VERSION ""

NS_ :

BS_:

BU_: VirtualNode_TEST LCDAM AVM ADV Gateway APA
VAL_TABLE_ HU_PDCAutoOnFunctionReq 3 "Reserved" 2 "OFF" 1 "ON" 0 "Inactive" ;
VAL_TABLE_ HU_BlindSpotFilledFunctionReq 3 "Reserved" 2 "On" 1 "Off" 0 "Inactive" ;
VAL_TABLE_ DisplayTheme 7 "Reserved" 6 "Reserved" 5 "Reserved" 4 "Reserved" 3 "Theme 3" 2 "Theme 2" 1 "Theme 1" 0 "Not define" ;
VAL_TABLE_ HU_PDCBuzzerReq 3 "Reserved" 2 "On" 1 "Off" 0 "Inactive" ;
VAL_TABLE_ PDCFunctionReq 3 "Reserved" 2 "On" 1 "Off" 0 "Inactive" ;
VAL_TABLE_ GW_OTAMode 7 "Reserved" 6 "Reserved" 5 "Reserved" 4 "Reserved" 3 "Reserved" 2 "Reserved" 1 "OTA Mode" 0 "Normal Mode" ;
VAL_TABLE_ GW_RemoteVehicleMode 1 "Remote Mode" 0 "Normal Mode" ;
VAL_TABLE_ WarningCmd_RCTA_Right 3 "Reserved" 2 "Warning level 2" 1 "Warning level 1" 0 "Inactive" ;
VAL_TABLE_ WarningCmd_RCTA_left 3 "Reserved" 2 "Warning level 2" 1 "Warning level 1" 0 "Inactive" ;
VAL_TABLE_ ADV_TargetTracingAvaialble 1 "Available" 0 "Not Available" ;
VAL_TABLE_ ADV_DebugEnabled 1 "Enabled" 0 "Not Enabled" ;
VAL_TABLE_ ADV_CurrentDirection 1 "Backward" 0 "Forward" ;
VAL_TABLE_ ADV_PathTracingAvaialble 1 "Available" 0 "Not Available" ;
VAL_TABLE_ ADV_Alarm_Position_Rear_Right 3 "Invalid" 2 "Range 2" 1 "Range 1" 0 "No Object" ;
VAL_TABLE_ ADV_Alarm_Position_Rear_Left 3 "Invalid" 2 "Range 2" 1 "Range 1" 0 "No Object" ;
VAL_TABLE_ ADV_Alarm_Position_Front_Right 3 "Invalid" 2 "Range 2" 1 "Range 1" 0 "No Object" ;
VAL_TABLE_ ADV_Alarm_Position_Front_Left 3 "Invalid" 2 "Range 2" 1 "Range 1" 0 "No Object" ;
VAL_TABLE_ ADV_PDCSchedule 3 "Reserved" 2 "Reserved" 1 "Sensor one time" 0 "No Request" ;
VAL_TABLE_ ADV_RightSlotSearchType 3 "All" 2 "Parallel" 1 "Perpedicular" 0 "Inactive" ;
VAL_TABLE_ ADV_LeftSlotSearchType 3 "All" 2 "Parallel" 1 "Perpedicular" 0 "Inactive" ;
VAL_TABLE_ ADV_FunctionAbnormalTip 63 "Reserved" 62 "Reserved" 61 "Reserved" 60 "Reserved" 59 "Reserved" 58 "Reserved" 57 "Reserved" 56 "Reserved" 55 "Wireless charging,ifstopcharging" 54 "Wireless charge station founded" 53 "Wireless charge enquiry charging" 52 "Air suspension is adjusting" 51 "Vehicle is in remote mode" 50 "Start park out tip" 49 "Start park in tip" 48 "Disclaimer tip" 47 "Wifi signal loss" 46 "Abnormal tire pressure" 45 "Space Unknown" 44 "Space Insufficient" 43 "Parking has been completed" 42 "Press DMH to start or exit" 41 "vehicle height not fulfilled" 40 "Vehicle direction incorrect" 39 "EPS Sys Can't Respons Correctly" 38 "Driving brake SysCan'tRespoCorre" 37 "AVS SysCan'tRespCorrectly" 36 "StartSysCan'tResp Correctly" 35 "Door SysCan'tResponCorrectly" 34 "Remote contro Sys Can't RespCorr" 33 "Gear shift SysCan'tResCorrectly" 32 "ParkinBrakeSysCan'tRespCorrectly" 31 "Forward-look signa is unavailab" 30 "PDC Signal Interf Not Available" 29 "AVS Signal Interf Not Available" 28 "YAW Signal Interf Not Available" 27 "SAS Signal Interf Not Available" 26 "Onekey startup interf is unavail" 25 "IVI Interface Not Available" 24 "VehicleDriveInterf Not Available" 23 "Comfort Sys Interfac unavailable" 22 "Steering interface unavailable" 21 "Parking Brake Interf unavailable" 20 "Shift gears interfac unavailable" 19 "DrivingBrake Interfa unavailable" 18 "SACC or LKA activated" 17 "Tracking error" 16 "Unable to switch vehicle mode" 15 "Space Insufficient" 14 "Obstacle is too close" 13 "Door open" 12 "Cannot enter parking status" 11 "Speed too fast,system exit" 10 "Speed too fast,Please slow down" 9 "Parki can'tcomple pleasetakeover" 8 "Road surface complexity" 7 "Gradient too high" 6 "Driver intervention EPB" 5 "Driver intervention steeringwhee" 4 "Driver intervention brake pedal" 3 "Vehicle not started" 2 "Parking syst exit by hard butt" 1 "Parking sys exit by soft butt" 0 "No Tip" ;
VAL_TABLE_ ADV_ParkOutDirection 7 "Reserved" 6 "Reserved" 5 "Left Parallel" 4 "Right Parallel" 3 "Left perpendicular" 2 "Rear perpendicular" 1 "Front perpendicular" 0 "Right perpendicular" ;
VAL_TABLE_ ADV_ParkInSlotSearchMode 1 "Manual" 0 "Auto" ;
VAL_TABLE_ ADV_ParkType 7 "Reserved" 6 "Reserved" 5 "Reserved" 4 "Reserved" 3 "Auto" 2 "Backward Oblique" 1 "Backward Perpendicular" 0 "Parallel" ;
VAL_TABLE_ RemoteAVSViewModeReq 15 "Reserved" 14 "Reserved" 13 "Reserved" 12 "Reserved" 11 "Screen Dragged 3D View" 10 "Rear Rim view" 9 "Front Rim view" 8 "Reserved" 7 "Rear Wide View" 6 "Front Wide View" 5 "Top View and Right View" 4 "Top View and Left View" 3 "Top View and Rear View" 2 "Top View and Front View" 1 "All Top View" 0 "Inactive" ;
VAL_TABLE_ RemoteAVSSharpnessReq 3 "Reserved" 2 "HD" 1 "SD" 0 "No Request" ;
VAL_TABLE_ RemoteMonitoringReq 3 "Reserved" 2 "On" 1 "Off" 0 "Inactive" ;
VAL_TABLE_ DoorSt_RR 1 "Open" 0 "Close" ;
VAL_TABLE_ DoorSt_RL 1 "Open" 0 "Close" ;
VAL_TABLE_ MCP_AVSandFRadarSwitch 1 "Pressed" 0 "Not pressed" ;
VAL_TABLE_ ParkOutDirection 15 "Reserved" 14 "Reserved" 13 "Reserved" 12 "Reserved" 11 "Reserved" 10 "Reserved" 9 "Reserved" 8 "Reserved" 7 "Remote control" 6 "Left Parallel" 5 "Right Parallel" 4 "Left perpendicular" 3 "Rear perpendicular" 2 "Front perpendicular" 1 "Right perpendicular" 0 "No request" ;
VAL_TABLE_ TargetSelection_Area 1 "Green Area" 0 "Red Area" ;
VAL_TABLE_ DMS_VehicleModeInfo 15 "Invalid value" 14 "Reserved" 13 "Reserved" 12 "Reserved" 11 "Reserved" 10 "Reserved" 9 "Reserved" 8 "Reserved" 7 "EV" 6 "Individual" 5 "Off road" 4 "Snow" 3 "Sport" 2 "Comfort" 1 "Eco" 0 "Auto" ;
VAL_TABLE_ EngineHoodSt 1 "Open" 0 "Close" ;
VAL_TABLE_ AutoLightMode 1 "Active" 0 "Inactive" ;
VAL_TABLE_ WheelSpeedDirection_RR 3 "Invalid Value" 2 "Backward" 1 "Forward" 0 "Stop" ;
VAL_TABLE_ WheelSpeedDirection_RL 3 "Invalid Value" 2 "Backward" 1 "Forward" 0 "Stop" ;
VAL_TABLE_ WheelSpeedDirection_FR 3 "Invalid Value" 2 "Backward" 1 "Forward" 0 "Stop" ;
VAL_TABLE_ WheelSpeedDirection_FL 3 "Invalid Value" 2 "Backward" 1 "Forward" 0 "Stop" ;
VAL_TABLE_ SensorErrorSt_RLS 1 "Error" 0 "No error" ;
VAL_TABLE_ ObjectRange_RLS 7 "Invalid Value" 6 "Range 6" 5 "Range 5" 4 "Range 4" 3 "Range 3" 2 "Range 2" 1 "Range 1" 0 "No Object" ;
VAL_TABLE_ SensorErrorSt_FRS 1 "Error" 0 "No error" ;
VAL_TABLE_ ObjectRange_FRS 7 "Invalid Value" 6 "Range 6" 5 "Range 5" 4 "Range 4" 3 "Range 3" 2 "Range 2" 1 "Range 1" 0 "No Object" ;
VAL_TABLE_ SensorErrorSt_FLS 1 "Error" 0 "No error" ;
VAL_TABLE_ ObjectRange_FLS 7 "Invalid Value" 6 "Range 6" 5 "Range 5" 4 "Range 4" 3 "Range 3" 2 "Range 2" 1 "Range 1" 0 "No Object" ;
VAL_TABLE_ SensorBlockageSt_RLS 1 "Blockage" 0 "No blockage" ;
VAL_TABLE_ SensorBlockageSt_FRS 1 "Blockage" 0 "No blockage" ;
VAL_TABLE_ SensorBlockageSt_FLS 1 "Blockage" 0 "No blockage" ;
VAL_TABLE_ PDC_FunctionTip 7 "Reserved" 6 "Searching both slot failure" 5 "Searching both slot success" 4 "Searching left slot success" 3 "Searching left slot failure" 2 "Searching right slot success" 1 "Searching right slot failure" 0 "Inactive" ;
VAL_TABLE_ SwitchScreenRequest_PDC 3 "Reserved" 2 "PDC Display Enter Request" 1 "PDC Display Exit Request" 0 "Inactive" ;
VAL_TABLE_ PDCAutoOnFunctionInd 1 "On" 0 "Off" ;
VAL_TABLE_ BuzzerSwitchSt 1 "On" 0 "Off" ;
VAL_TABLE_ RadarSysSt_RearSide 1 "On" 0 "Off" ;
VAL_TABLE_ RadarSysSt_FrontSide 1 "On" 0 "Off" ;
VAL_TABLE_ BuzzerAlarmPosition 7 "Reserved" 6 "Reserved" 5 "Reserved" 4 "Front + Rear" 3 "SelfCheck" 2 "Rear" 1 "Front" 0 "Off" ;
VAL_TABLE_ AVS_RemoteViewModeFeedback 31 "Reserved" 30 "Reserved" 29 "Reserved" 28 "Reserved" 27 "Reserved" 26 "Reserved" 25 "Reserved" 24 "Rear Rim view Failure" 23 "Rear Rim view Success" 22 "Front Rim view Failure" 21 "Front Rim view Success" 20 "Reserved" 19 "Reserved" 18 "Rear Wide View Failure" 17 "Rear Wide View Success" 16 "Front Wide View Failure" 15 "Front Wide View Success" 14 "Top View and Right View Failure" 13 "Top View and Right View Success" 12 "Top View and Left View Failure" 11 "Top View and Left View Success" 10 "Top View and Rear View Failure" 9 "Top View and Rear View Success" 8 "Top View and Front View Failure" 7 "Top View and Front View Success" 6 "All Top View Failure" 5 "All Top View Success" 4 "On Failure" 3 "On Success" 2 "Off Failure" 1 "Off Success" 0 "Inactive" ;
VAL_TABLE_ TurnFollowUpFunctionInd 1 "On" 0 "Off" ;
VAL_TABLE_ RemoteMonitoringModeSt_AVS 1 "Video Mode" 0 "Picture Mode" ;
VAL_TABLE_ RemoteMonitoringSt_AVS 1 "On" 0 "Off" ;
VAL_TABLE_ RemoteMonitoringSharpnessSt_AVS 1 "HD" 0 "SD" ;
VAL_TABLE_ AVS_RemoteSharpnessFeedback 7 "Reserved" 6 "Reserved" 5 "Reserved" 4 "HD Failure" 3 "HD Success" 2 "SD Failure" 1 "SD Success" 0 "Inactive" ;
VAL_TABLE_ AVS_RemoteMonitorigFeedback 7 "Reserved" 6 "Reserved" 5 "Reserved" 4 "On Failure" 3 "On Success" 2 "Off Failure" 1 "Off Success" 0 "Inactive" ;
VAL_TABLE_ AVS_PDWarning_Rear 1 "Warning" 0 "No warning" ;
VAL_TABLE_ AVS_PDWarning_Front 1 "Warning" 0 "No warning" ;
VAL_TABLE_ AVS_CalibrationSt 3 "Reserved" 2 "Calibrated" 1 "Calibrating" 0 "Not calibrated" ;
VAL_TABLE_ AVS_AbnormalTip 7 "Reserved" 6 "Reserved" 5 "Reserved" 4 "Reserved" 3 "Reserved" 2 "Reserved" 1 "Speed too high" 0 "Inactive" ;
VAL_TABLE_ AVSCameraBlockageSt_Right 1 "Blockage" 0 "No Blockage" ;
VAL_TABLE_ AVSCameraBlockageSt_Left 1 "Blockage" 0 "No Blockage" ;
VAL_TABLE_ AVSCameraBlockageSt_Rear 1 "Blockage" 0 "No Blockage" ;
VAL_TABLE_ AVSCameraBlockageSt_Front 1 "Blockage" 0 "No Blockage" ;
VAL_TABLE_ FoundSlotBuzzerTip 1 "Active" 0 "Inactive" ;
VAL_TABLE_ BlindSpotFilledFunctionInd 1 "On" 0 "Off" ;
VAL_TABLE_ AVSViewtype 3 "Reserved" 2 "Other" 1 "3D" 0 "2D" ;
VAL_TABLE_ SensorBlockageSt 1 "blockage" 0 "No blockage" ;
VAL_TABLE_ SensorErrorSt 1 "error" 0 "No error" ;
VAL_TABLE_ ObjectRange 7 "Invalid Value" 6 "Range 6" 5 "Range 5" 4 "Range 4" 3 "Range 3" 2 "Range 2" 1 "Range 1" 0 "No Object" ;
VAL_TABLE_ TxRxSt_ 3 "Reserved" 2 "Rx" 1 "Tx" 0 "Reserved" ;
VAL_TABLE_ VtSif_HU_SpeechReq_AVS 3 "Reserved" 2 "On" 1 "Off" 0 "Inactive" ;
VAL_TABLE_ ViSig_APS_Slot1_Info 3 "Reserved" 2 "Obstacle" 1 "No obstacle" 0 "Initial" ;
VAL_TABLE_ VtSigHU_AVMSwitchScreenResp 3 "Reserved" 2 "AVM Exit Response" 1 "AVM Enter Response" 0 "Inactive" ;

BO_ 3221225472 VECTOR__INDEPENDENT_SIG_MSG: 0 Vector__XXX
 SG_ USS_DIAG_MRL : 0|10@1+ (1,0) [0|1023] "" Vector__XXX
 SG_ Distance_PDC_6 : 0|10@1+ (1,0) [0|0] "cm" Vector__XXX
 SG_ SafetySW_PDCAVM_Switch : 0|1@1+ (1,0) [0|0] "" Vector__XXX
 SG_ YRS_2_Reserve : 0|16@1- (1,0) [0|0] "" Vector__XXX
 SG_ YRS_1_Reserve : 0|8@1+ (1,0) [0|0] "" Vector__XXX
 SG_ PDC_SwitchScreenRequest : 0|2@1+ (1,0) [0|0] "" Vector__XXX
 SG_ PDC_BuzzerSwitchSt : 0|1@1+ (1,0) [0|0] "" Vector__XXX
 SG_ PDC_AutoOnFunctionInd : 0|1@1+ (1,0) [0|0] "" Vector__XXX
 SG_ PDC_SideRadarSystemStatus : 0|1@1+ (1,0) [0|0] "" Vector__XXX
 SG_ PDC_RRLevel : 0|3@1+ (1,0) [0|0] "" Vector__XXX
 SG_ PDC_RLLevel : 0|3@1+ (1,0) [0|0] "" Vector__XXX
 SG_ PDC_RearRadarSystemStatus : 0|1@1+ (1,0) [0|0] "" Vector__XXX
 SG_ PDC_FrontRadarSystemStatus : 0|1@1+ (1,0) [0|0] "" Vector__XXX
 SG_ PDC_FRLevel : 0|3@1- (1,0) [0|0] "" Vector__XXX
 SG_ PDC_FLLevel : 0|3@1+ (1,0) [0|0] "" Vector__XXX
 SG_ PDC_CenterRRLevel : 0|3@1+ (1,0) [0|0] "" Vector__XXX
 SG_ PDC_CenterRLLevel : 0|3@1+ (1,0) [0|0] "" Vector__XXX
 SG_ PDC_CenterFRLevel : 0|3@1+ (1,0) [0|7] "" Vector__XXX
 SG_ PDC_CenterFLLevel : 0|3@1+ (1,0) [0|0] "" Vector__XXX
 SG_ PDC_BuzzerControl : 0|3@1+ (1,0) [0|0] "" Vector__XXX
 SG_ PDC_RightLongDistSensorErrSta : 0|2@1- (1,0) [0|0] "" Vector__XXX
 SG_ PDC_LeftLongDistSensorErrSta : 0|2@1- (1,0) [0|0] "" Vector__XXX
 SG_ PDC_RRSensorErrorStatus : 0|2@1- (1,0) [0|0] "" Vector__XXX
 SG_ PDC_CenterRRSensorErrorStatus : 0|2@1- (1,0) [0|0] "" Vector__XXX
 SG_ PDC_CenterRLSensorErrorStatus : 0|2@1- (1,0) [0|0] "" Vector__XXX
 SG_ PDC_RLSensorErrorStatus : 0|2@1- (1,0) [0|0] "" Vector__XXX
 SG_ PDC_FRSensorErrorStatus : 0|2@1- (1,0) [0|0] "" Vector__XXX
 SG_ PDC_CenterFRSensorErrorStatus : 0|2@1+ (1,0) [0|0] "" Vector__XXX
 SG_ PDC_CenterFLSensorErrorStatus : 0|2@1- (1,0) [0|0] "" Vector__XXX
 SG_ PDC_FLSensorErrorStatus : 0|2@1+ (1,0) [0|0] "" Vector__XXX
 SG_ AY1Offset : 0|12@1- (0.01,0) [-20.48|20.47] "m/s2" Vector__XXX
 SG_ AX1Offset : 0|12@1- (0.01,0) [-20.48|20.47] "m/s2" Vector__XXX
 SG_ YawRateOffset : 0|12@1- (0.05,0) [-102.4|102.35] "" Vector__XXX
 SG_ LiveCounter_YRS2 : 0|4@1+ (1,0) [0|0] "Pulse" Vector__XXX
 SG_ Checksum_YRS2 : 0|8@1+ (1,0) [0|0] "" Vector__XXX
 SG_ BCM_RightTurnLightCmd : 0|1@1+ (1,0) [0|0] "" Vector__XXX
 SG_ BCM_LeftTurnLightCmd : 0|1@1+ (1,0) [0|0] "" Vector__XXX
 SG_ HU_SpeechRequest_AVMView : 0|4@1+ (1,0) [0|0] "" Vector__XXX
 SG_ HU_SpeechRequest_AVMandPDC : 0|2@1+ (1,0) [0|0] "" Vector__XXX
 SG_ HU_PDCFunctionReq : 0|1@1+ (1,0) [0|0] "" Vector__XXX
 SG_ HU_PDCBuzzerReq : 0|1@1+ (1,0) [0|0] "" Vector__XXX
 SG_ HU_PDCAutoOnFunctionReq : 0|1@1+ (1,0) [0|0] "" Vector__XXX
 SG_ HU_PDCAVMFunctionCmd : 0|1@1+ (1,0) [0|0] "" Vector__XXX
 SG_ reserve_1 : 0|32@1+ (1,0) [0|0] "" Vector__XXX
 SG_ ScreenPressPosition_X : 0|11@1+ (1,0) [0|0] "pixel" Vector__XXX
 SG_ AVS_SpeechControlFeedback : 0|5@1+ (1,0) [0|0] "" Vector__XXX
 SG_ MODWarning_Right : 0|1@1+ (1,0) [0|0] "" Vector__XXX
 SG_ MODWarning_Left : 0|1@1+ (1,0) [0|0] "" Vector__XXX
 SG_ CTAWarning_Rear : 0|1@1+ (1,0) [0|0] "" Vector__XXX
 SG_ CTAWarning_Front : 0|1@1+ (1,0) [0|0] "" Vector__XXX
 SG_ SensorBlockageSt_RLong : 0|1@1+ (1,0) [0|0] "" Vector__XXX
 SG_ SensorBlockageSt_Llong : 0|1@1+ (1,0) [0|0] "" Vector__XXX
 SG_ PDC_SearchingSlotPosition : 0|2@1+ (1,0) [0|0] "" Vector__XXX
 SG_ PDC_SpeechControlFeedback : 0|3@1+ (1,0) [0|0] "" Vector__XXX
 SG_ SensorErrorSt_RLong : 0|1@1+ (1,0) [0|0] "" Vector__XXX
 SG_ SensorErrorSt_LLong : 0|1@1+ (1,0) [0|0] "" Vector__XXX
 SG_ RadarSysSt_Side : 0|1@1+ (1,0) [0|1] "" Vector__XXX
 SG_ HandParkingBrakeSt : 0|2@1+ (1,0) [0|0] "" Vector__XXX
 SG_ FogLightSt_FR : 0|1@1+ (1,0) [0|0] "" Vector__XXX
 SG_ FogLightSt_FL : 0|1@1+ (1,0) [0|0] "" Vector__XXX
 SG_ ParkInSlotSearchModeSet : 0|2@1+ (1,0) [0|0] "" Vector__XXX
 SG_ AVSViewModeReponse : 0|4@1+ (1,0) [0|0] "" Vector__XXX
 SG_ ScreenPressPosition_Y : 0|11@1+ (1,0) [0|0] "pixel" Vector__XXX
 SG_ ABS_2_Reserve : 0|8@1+ (1,0) [0|0] "" Vector__XXX
 SG_ PDC_DIS_RRS : 0|10@1- (1,0) [0|1023] "" Vector__XXX
 SG_ PDC_DIS_RLS : 0|10@1+ (1,0) [0|1023] "" Vector__XXX

BO_ 746 USS_SLOT_R_CD: 8 APA
 SG_ USS_SLOT_R_Dy : 48|16@1- (1,0) [-32768|32767] ""  APA
 SG_ USS_SLOT_R_Dx : 32|16@1- (1,0) [-32768|32767] ""  APA
 SG_ USS_SLOT_R_Cy : 16|16@1- (1,0) [-32768|32767] ""  APA
 SG_ USS_SLOT_R_Cx : 0|16@1- (1,0) [-32768|32767] ""  APA

BO_ 745 USS_SLOT_R_AB: 8 APA
 SG_ USS_SLOT_R_By : 48|16@1- (1,0) [-32768|32767] ""  APA
 SG_ USS_SLOT_R_Bx : 32|16@1- (1,0) [-32768|32767] ""  APA
 SG_ USS_SLOT_R_Ay : 16|16@1- (1,0) [-32768|32767] ""  APA
 SG_ USS_SLOT_R_Ax : 0|16@1- (1,0) [-32768|32767] ""  APA

BO_ 744 USS_SLOT_L_CD: 8 APA
 SG_ USS_SLOT_L_Dy : 48|16@1- (1,0) [-32768|32767] ""  APA
 SG_ USS_SLOT_L_Dx : 32|16@1- (1,0) [-32768|32767] ""  APA
 SG_ USS_SLOT_L_Cy : 16|16@1- (1,0) [-32768|32767] ""  APA
 SG_ USS_SLOT_L_Cx : 0|16@1- (1,0) [-32768|32767] ""  APA

BO_ 743 USS_SLOT_L_AB: 8 APA
 SG_ USS_SLOT_L_By : 48|16@1- (1,0) [-32768|32767] ""  APA
 SG_ USS_SLOT_L_Bx : 32|16@1- (1,0) [-32768|32767] ""  APA
 SG_ USS_SLOT_L_AY : 16|16@1- (1,0) [-32768|32767] ""  APA
 SG_ USS_SLOT_L_Ax : 0|16@1- (1,0) [-32768|32767] ""  APA

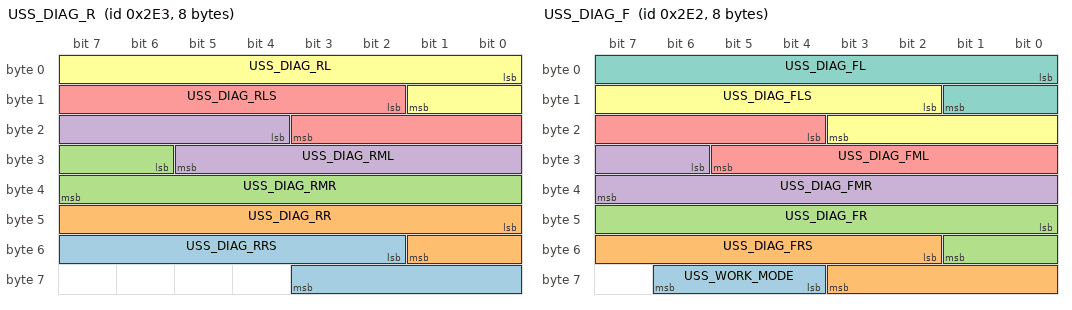
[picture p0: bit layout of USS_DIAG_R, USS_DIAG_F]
BO_ 739 USS_DIAG_R: 8 APA
 SG_ USS_DIAG_RRS : 50|10@1+ (1,0) [0|1023] ""  APA
 SG_ USS_DIAG_RR : 40|10@1+ (1,0) [0|1023] ""  APA
 SG_ USS_DIAG_RMR : 30|10@1+ (1,0) [0|1023] ""  APA
 SG_ USS_DIAG_RML : 20|10@1+ (1,0) [0|1023] ""  APA
 SG_ USS_DIAG_RLS : 10|10@1+ (1,0) [0|1023] ""  APA
 SG_ USS_DIAG_RL : 0|10@1+ (1,0) [0|1023] ""  APA

BO_ 738 USS_DIAG_F: 8 APA
 SG_ USS_WORK_MODE : 60|3@1+ (1,0) [0|7] ""  APA
 SG_ USS_DIAG_FRS : 50|10@1+ (1,0) [0|1023] ""  APA
 SG_ USS_DIAG_FR : 40|10@1+ (1,0) [0|1023] ""  APA
 SG_ USS_DIAG_FMR : 30|10@1+ (1,0) [0|1023] ""  APA
 SG_ USS_DIAG_FML : 20|10@1+ (1,0) [0|1023] ""  APA
 SG_ USS_DIAG_FLS : 10|10@1+ (1,0) [0|1023] ""  APA
 SG_ USS_DIAG_FL : 0|10@1+ (1,0) [0|1023] ""  APA

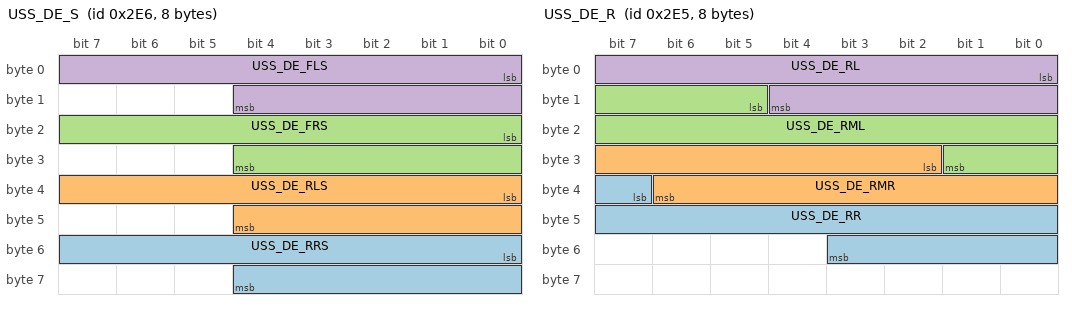
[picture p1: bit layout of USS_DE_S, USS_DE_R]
BO_ 742 USS_DE_S: 8 APA
 SG_ USS_DE_RRS : 48|13@1+ (1,0) [0|65535] ""  APA
 SG_ USS_DE_RLS : 32|13@1+ (1,0) [0|65535] ""  APA
 SG_ USS_DE_FRS : 16|13@1+ (1,0) [0|65535] ""  APA
 SG_ USS_DE_FLS : 0|13@1+ (1,0) [0|65535] ""  APA

BO_ 741 USS_DE_R: 8 APA
 SG_ USS_DE_RR : 39|13@1+ (1,0) [0|65535] ""  APA
 SG_ USS_DE_RMR : 26|13@1+ (1,0) [0|65535] ""  APA
 SG_ USS_DE_RML : 13|13@1+ (1,0) [0|65535] ""  APA
 SG_ USS_DE_RL : 0|13@1+ (1,0) [0|65535] ""  APA

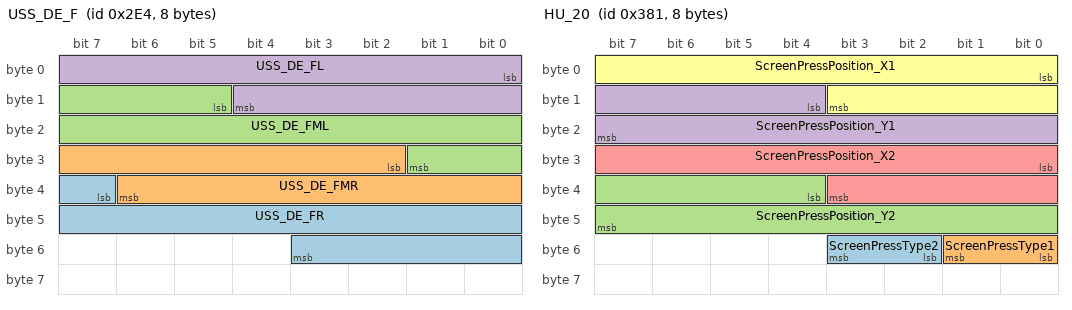
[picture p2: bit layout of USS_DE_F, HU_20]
BO_ 740 USS_DE_F: 8 APA
 SG_ USS_DE_FR : 39|13@1+ (1,0) [0|65535] "" Vector__XXX
 SG_ USS_DE_FMR : 26|13@1+ (1,0) [0|65535] "" Vector__XXX
 SG_ USS_DE_FML : 13|13@1+ (1,0) [0|65535] "" Vector__XXX
 SG_ USS_DE_FL : 0|13@1+ (1,0) [0|65535] "" Vector__XXX

BO_ 994 alpha_distance_R: 8 VirtualNode_TEST
 SG_ alpha_USS_RR : 48|16@1+ (1,0) [0|65535] ""  APA
 SG_ alpha_USS_RMR : 32|16@1+ (1,0) [0|65535] ""  APA
 SG_ alpha_USS_RML : 16|16@1+ (1,0) [0|65535] ""  APA
 SG_ alpha_USS_RL : 0|16@1+ (1,0) [0|65535] ""  APA

BO_ 995 alpha_distance_Long: 8 VirtualNode_TEST
 SG_ alpha_USS_RR_long : 48|16@1+ (1,0) [0|65535] ""  APA
 SG_ alpha_USS_RL_long : 32|16@1+ (1,0) [0|65535] ""  APA
 SG_ alpha_USS_FR_long : 16|16@1+ (1,0) [0|65535] ""  APA
 SG_ alpha_USS_FL_long : 0|16@1+ (1,0) [0|65535] ""  APA

BO_ 993 alpha_distance_F: 8 VirtualNode_TEST
 SG_ alpha_USS_FR : 48|16@1+ (1,0) [0|65535] ""  APA
 SG_ alpha_USS_FMR : 32|16@1+ (1,0) [0|65535] ""  APA
 SG_ alpha_USS_FML : 16|16@1+ (1,0) [0|65535] ""  APA
 SG_ alpha_USS_FL : 0|16@1+ (1,0) [0|65535] ""  APA

BO_ 897 HU_20: 8 Gateway
 SG_ ScreenPressType2 : 50|2@1+ (1,0) [0|0] ""  APA
 SG_ ScreenPressType1 : 48|2@1+ (1,0) [0|0] ""  APA
 SG_ ScreenPressPosition_Y2 : 36|12@1+ (1,0) [0|720] "pixel"  APA
 SG_ ScreenPressPosition_Y1 : 12|12@1+ (1,0) [0|720] "pixel"  APA
 SG_ ScreenPressPosition_X2 : 24|12@1+ (1,0) [0|2607] "pixel"  APA
 SG_ ScreenPressPosition_X1 : 0|12@1+ (1,0) [0|2607] "pixel"  APA

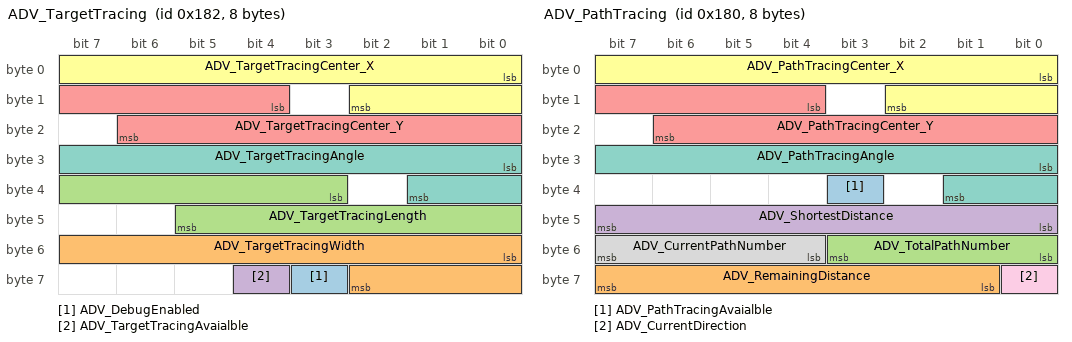
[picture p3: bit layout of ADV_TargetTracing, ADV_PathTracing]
BO_ 386 ADV_TargetTracing: 8 ADV
 SG_ ADV_DebugEnabled : 59|1@1+ (1,0) [0|0] ""  APA
 SG_ ADV_TargetTracingWidth : 48|11@1+ (1,0) [0|2000] "cm"  APA
 SG_ ADV_TargetTracingLength : 35|11@1- (1,0) [0|2000] "cm"  APA
 SG_ ADV_TargetTracingAvaialble : 60|1@1+ (1,0) [0|0] ""  APA
 SG_ ADV_TargetTracingCenter_Y : 12|11@1- (1,0) [-1000|1000] "cm"  APA
 SG_ ADV_TargetTracingCenter_X : 0|11@1- (1,0) [-1000|1000] "cm"  APA
 SG_ ADV_TargetTracingAngle : 24|10@1+ (1,0) [0|360] "degree"  APA

BO_ 384 ADV_PathTracing: 8 ADV
 SG_ ADV_PathTracingAvaialble : 35|1@1- (1,0) [0|0] ""  APA
 SG_ ADV_RemainingDistance : 57|7@1+ (1,0) [0|100] "%"  APA
 SG_ ADV_TotalPathNumber : 48|4@1+ (1,0) [0|10] ""  APA
 SG_ ADV_ShortestDistance : 40|8@1- (1,0) [-126|127] "cm"  APA
 SG_ ADV_PathTracingCenter_Y : 12|11@1- (1,0) [-1000|1000] "cm"  APA
 SG_ ADV_PathTracingCenter_X : 0|11@1- (1,0) [-1000|1000] "cm"  APA
 SG_ ADV_PathTracingAngle : 24|10@1+ (1,0) [0|360] "degree"  APA
 SG_ ADV_CurrentPathNumber : 52|4@1+ (1,0) [0|10] ""  APA
 SG_ ADV_CurrentDirection : 56|1@1+ (1,0) [0|0] ""  APA

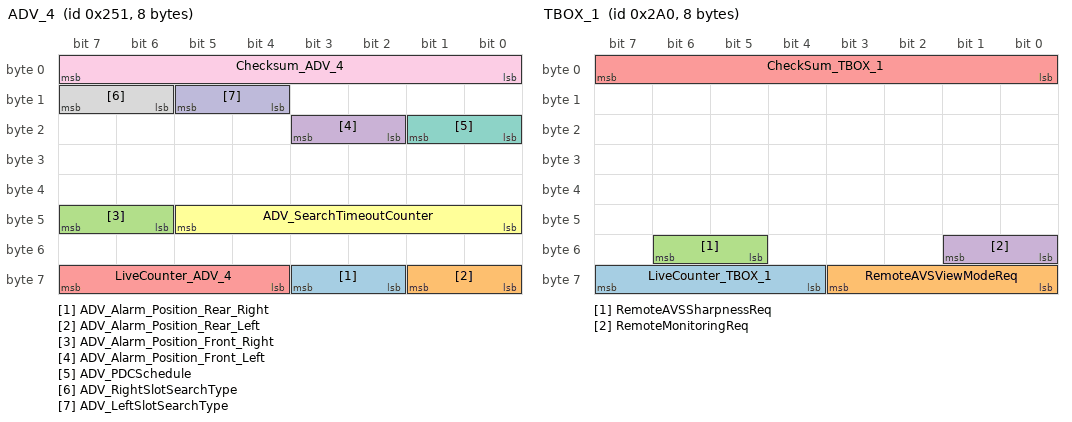
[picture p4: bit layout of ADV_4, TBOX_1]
BO_ 593 ADV_4: 8 ADV
 SG_ ADV_Alarm_Position_Rear_Right : 58|2@1+ (1,0) [0|0] ""  APA
 SG_ ADV_Alarm_Position_Rear_Left : 56|2@1+ (1,0) [0|0] ""  APA
 SG_ ADV_Alarm_Position_Front_Right : 46|2@1+ (1,0) [0|0] ""  APA
 SG_ ADV_Alarm_Position_Front_Left : 18|2@1+ (1,0) [0|0] ""  APA
 SG_ LiveCounter_ADV_4 : 60|4@1+ (1,0) [0|15] "Pulse"  APA
 SG_ ADV_SearchTimeoutCounter : 40|6@1+ (1,0) [0|63] "seconds"  APA
 SG_ ADV_PDCSchedule : 16|2@1+ (1,0) [0|0] ""  APA
 SG_ ADV_RightSlotSearchType : 14|2@1+ (1,0) [0|0] ""  APA
 SG_ Checksum_ADV_4 : 0|8@1+ (1,0) [0|255] ""  APA
 SG_ ADV_LeftSlotSearchType : 12|2@1+ (1,0) [0|0] ""  APA

BO_ 672 TBOX_1: 8 Gateway
 SG_ LiveCounter_TBOX_1 : 60|4@1+ (1,0) [0|15] "pulse"  APA
 SG_ RemoteAVSViewModeReq : 56|4@1+ (1,0) [0|0] ""  APA
 SG_ RemoteAVSSharpnessReq : 53|2@1+ (1,0) [0|0] ""  APA
 SG_ RemoteMonitoringReq : 48|2@1+ (1,0) [0|0] ""  APA
 SG_ CheckSum_TBOX_1 : 0|8@1+ (1,0) [0|255] ""  APA

BO_ 591 RRDCU_1: 8 Gateway
 SG_ DoorSt_RR : 2|1@1+ (1,0) [0|0] ""  APA

BO_ 590 RLDCU_1: 8 Gateway
 SG_ DoorSt_RL : 2|1@1+ (1,0) [0|0] ""  APA

BO_ 420 MCP_1: 8 Gateway
 SG_ MCP_AVSandFRadarSwitch : 25|1@1+ (1,0) [0|1] ""  APA

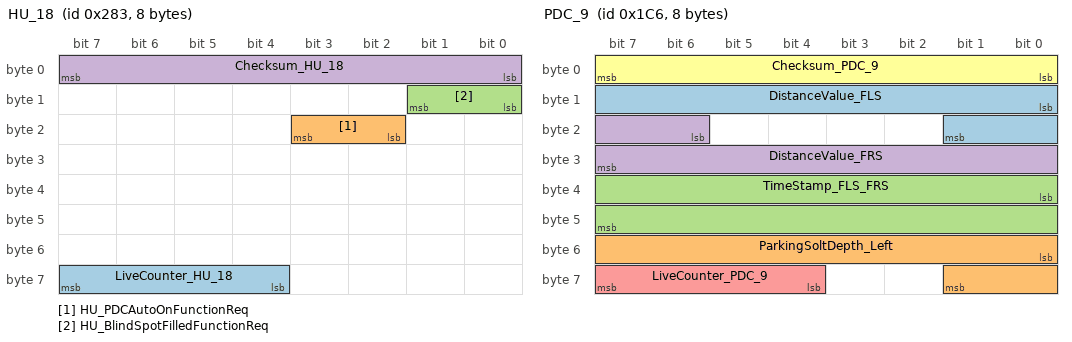
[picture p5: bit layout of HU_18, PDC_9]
BO_ 643 HU_18: 8 Gateway
 SG_ LiveCounter_HU_18 : 60|4@1+ (1,0) [0|15] "Pulse"  APA
 SG_ HU_PDCAutoOnFunctionReq : 18|2@1+ (1,0) [0|0] ""  APA
 SG_ HU_BlindSpotFilledFunctionReq : 8|2@1+ (1,0) [0|0] ""  APA
 SG_ Checksum_HU_18 : 0|8@1+ (1,0) [0|255] ""  APA

BO_ 657 HU_14: 8 Gateway
 SG_ DisplayTheme : 24|3@1+ (1,0) [0|0] ""  APA

BO_ 667 HU_10: 8 Gateway
 SG_ LiveCounter_HU_10 : 60|4@1+ (1,0) [0|15] "Pulse"  APA
 SG_ HU_PDCBuzzerReq : 22|2@1+ (1,0) [0|0] ""  APA
 SG_ Checksum_HU_10 : 0|8@1+ (1,0) [0|255] ""  APA

BO_ 688 GW_Config: 8 Gateway
 SG_ GW_RemoteVehicleMode : 12|1@1+ (1,0) [0|0] ""  APA
 SG_ GW_OTAMode : 16|3@1+ (1,0) [0|0] ""  APA

BO_ 534 DMS_2: 8 Gateway
 SG_ DMS_VehicleModeinfo : 8|4@1+ (1,0) [0|0] ""  APA

BO_ 571 BCM1_7: 8 Gateway
 SG_ Brightness_L : 8|8@1+ (400,0) [0|101200] "LUX"  APA
 SG_ Brightness_H : 16|10@1+ (6,0) [0|6126] "LUX"  APA
 SG_ Rainlntensity : 0|4@1+ (0.1,0) [0|1.5] ""  APA

BO_ 564 BCM1_3: 8 Gateway
 SG_ EngineHoodSt : 12|1@1+ (1,0) [0|0] ""  APA

BO_ 454 PDC_9: 8 APA
 SG_ DistanceValue_FLS : 8|10@1+ (1,0) [0|500] "cm"  AVM,ADV
 SG_ ParkingSoltDepth_Left : 48|10@1+ (1,0) [0|500] "cm"  AVM,ADV
 SG_ TimeStamp_FLS_FRS : 32|16@1+ (1,0) [0|65535] "ms"  AVM,ADV
 SG_ DistanceValue_FRS : 22|10@1+ (1,0) [0|500] "cm"  AVM,ADV
 SG_ LiveCounter_PDC_9 : 60|4@1+ (1,0) [0|15] "Pulse"  AVM,ADV
 SG_ Checksum_PDC_9 : 0|8@1+ (1,0) [0|255] ""  AVM,ADV

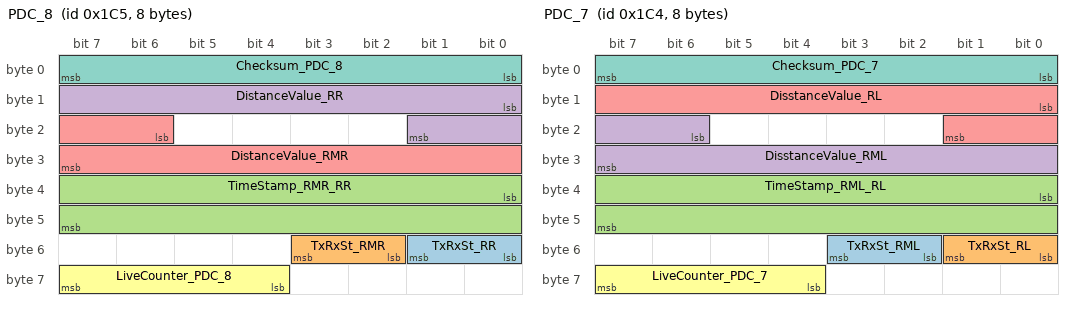
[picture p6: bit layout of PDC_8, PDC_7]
BO_ 453 PDC_8: 8 APA
 SG_ TxRxSt_RR : 48|2@1+ (1,0) [0|0] ""  AVM,ADV
 SG_ TxRxSt_RMR : 50|2@1+ (1,0) [0|0] ""  AVM,ADV
 SG_ TimeStamp_RMR_RR : 32|16@1+ (1,0) [0|65535] "ms"  AVM,ADV
 SG_ DistanceValue_RR : 8|10@1+ (1,0) [0|500] "cm"  AVM,ADV
 SG_ DistanceValue_RMR : 22|10@1+ (1,0) [0|500] "cm"  AVM,ADV
 SG_ LiveCounter_PDC_8 : 60|4@1+ (1,0) [0|15] "Pulse"  AVM,ADV
 SG_ Checksum_PDC_8 : 0|8@1+ (1,0) [0|255] ""  AVM,ADV

BO_ 452 PDC_7: 8 APA
 SG_ TxRxSt_RML : 50|2@1+ (1,0) [0|0] ""  AVM,ADV
 SG_ TxRxSt_RL : 48|2@1+ (1,0) [0|0] ""  AVM,ADV
 SG_ TimeStamp_RML_RL : 32|16@1+ (1,0) [0|65535] "ms"  AVM,ADV
 SG_ DisstanceValue_RML : 22|10@1+ (1,0) [0|500] "cm"  AVM,ADV
 SG_ DisstanceValue_RL : 8|10@1+ (1,0) [0|500] "cm"  AVM,ADV
 SG_ LiveCounter_PDC_7 : 60|4@1+ (1,0) [0|15] "Pulse"  AVM,ADV
 SG_ Checksum_PDC_7 : 0|8@1+ (1,0) [0|255] ""  AVM,ADV

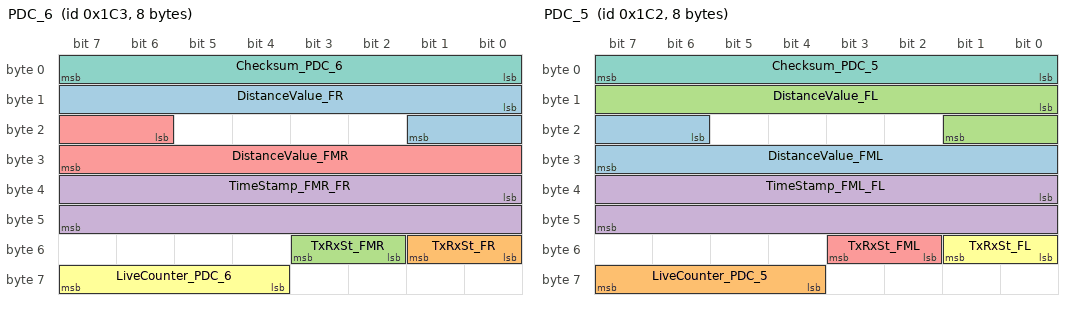
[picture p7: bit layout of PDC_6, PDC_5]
BO_ 451 PDC_6: 8 APA
 SG_ DistanceValue_FR : 8|10@1+ (1,0) [0|500] "cm"  AVM,ADV
 SG_ TxRxSt_FR : 48|2@1+ (1,0) [0|0] ""  AVM,ADV
 SG_ TxRxSt_FMR : 50|2@1+ (1,0) [0|0] ""  AVM,ADV
 SG_ TimeStamp_FMR_FR : 32|16@1+ (1,0) [0|65535] "ms"  AVM,ADV
 SG_ DistanceValue_FMR : 22|10@1+ (1,0) [0|500] "cm"  AVM,ADV
 SG_ LiveCounter_PDC_6 : 60|4@1+ (1,0) [0|15] "Pulse"  AVM,ADV
 SG_ Checksum_PDC_6 : 0|8@1+ (1,0) [0|255] ""  AVM,ADV

BO_ 450 PDC_5: 8 APA
 SG_ DistanceValue_FML : 22|10@1+ (1,0) [0|500] "cm" Vector__XXX
 SG_ LiveCounter_PDC_5 : 60|4@1+ (1,0) [0|15] "Pulse"  AVM,ADV
 SG_ DistanceValue_FL : 8|10@1+ (1,0) [0|500] "cm"  AVM,ADV
 SG_ TimeStamp_FML_FL : 32|16@1+ (1,0) [0|65535] "ms"  AVM,ADV
 SG_ TxRxSt_FML : 50|2@1+ (1,0) [0|0] ""  AVM,ADV
 SG_ TxRxSt_FL : 48|2@1+ (1,0) [0|0] ""  AVM,ADV
 SG_ Checksum_PDC_5 : 0|8@1+ (1,0) [0|255] ""  AVM,ADV

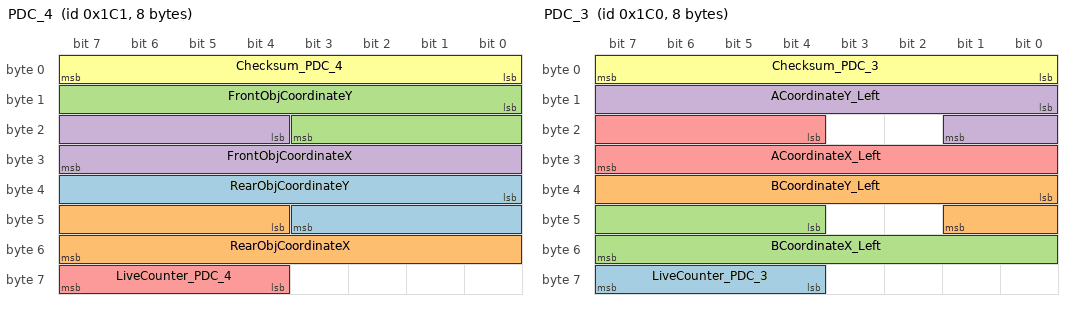
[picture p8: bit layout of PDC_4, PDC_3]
BO_ 449 PDC_4: 8 APA
 SG_ RearObjCoordinateY : 32|12@1- (2,0) [-4000|4000] "cm"  AVM,ADV
 SG_ RearObjCoordinateX : 44|12@1- (2,0) [-4000|4000] "cm"  AVM,ADV
 SG_ FrontObjCoordinateY : 8|12@1- (2,0) [-4000|4000] "cm"  AVM,ADV
 SG_ FrontObjCoordinateX : 20|12@1- (2,0) [-4000|4000] "cm"  AVM,ADV
 SG_ LiveCounter_PDC_4 : 60|4@1+ (1,0) [0|15] "Pulse"  AVM,ADV
 SG_ Checksum_PDC_4 : 0|8@1+ (1,0) [0|255] ""  AVM,ADV

BO_ 448 PDC_3: 8 APA
 SG_ LiveCounter_PDC_3 : 60|4@1+ (1,0) [0|15] "Pulse"  AVM,ADV
 SG_ BCoordinateY_Left : 32|10@1+ (1,0) [0|500] "cm"  AVM,ADV
 SG_ BCoordinateX_Left : 44|12@1+ (1,0) [0|3600] "cm"  AVM,ADV
 SG_ ACoordinateY_Left : 8|10@1+ (1,0) [0|500] "cm"  AVM,ADV
 SG_ ACoordinateX_Left : 20|12@1+ (1,0) [0|3600] "cm"  AVM,ADV
 SG_ Checksum_PDC_3 : 0|8@1+ (1,0) [0|255] ""  AVM,ADV

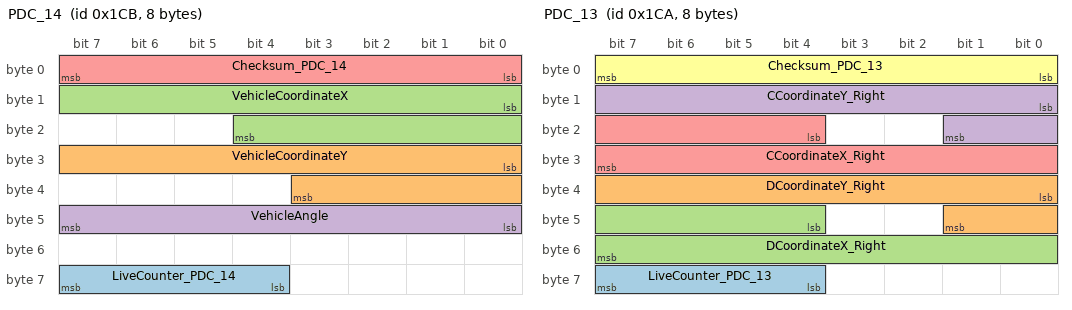
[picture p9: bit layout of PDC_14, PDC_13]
BO_ 459 PDC_14: 8 APA
 SG_ LiveCounter_PDC_14 : 60|4@1+ (1,0) [0|15] "Pulse"  AVM,ADV
 SG_ VehicleCoordinateY : 24|12@1- (1,0) [-1000|1000] "cm"  AVM,ADV
 SG_ VehicleCoordinateX : 8|13@1+ (1,0) [0|5000] "cm"  AVM,ADV
 SG_ VehicleAngle : 40|8@1- (0.1,0) [-10|10] "бу"  AVM,ADV
 SG_ Checksum_PDC_14 : 0|8@1+ (1,0) [0|255] ""  AVM,ADV

BO_ 458 PDC_13: 8 APA
 SG_ LiveCounter_PDC_13 : 60|4@1+ (1,0) [0|15] "Pulse"  AVM,ADV
 SG_ DCoordinateY_Right : 32|10@1+ (1,0) [0|500] "cm"  AVM,ADV
 SG_ DCoordinateX_Right : 44|12@1+ (1,0) [0|3600] "cm"  AVM,ADV
 SG_ CCoordinateY_Right : 8|10@1+ (1,0) [0|500] "cm"  AVM,ADV
 SG_ CCoordinateX_Right : 20|12@1+ (1,0) [0|3600] "cm"  AVM,ADV
 SG_ Checksum_PDC_13 : 0|8@1+ (1,0) [0|255] ""  AVM,ADV

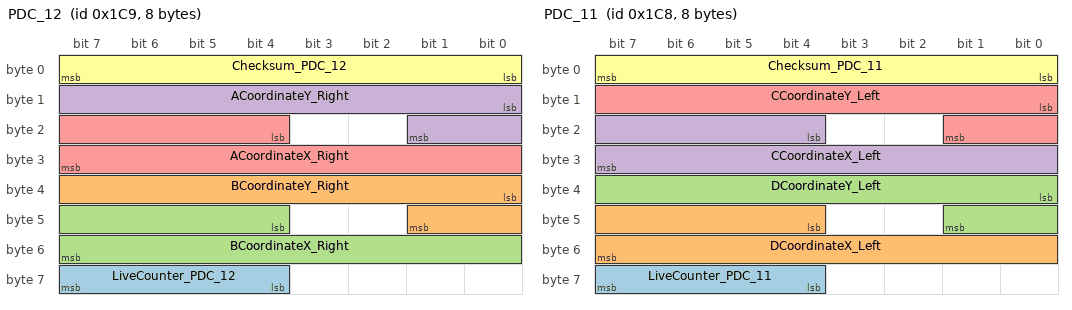
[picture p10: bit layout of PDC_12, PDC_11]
BO_ 457 PDC_12: 8 APA
 SG_ LiveCounter_PDC_12 : 60|4@1+ (1,0) [0|15] "Pulse"  AVM
 SG_ BCoordinateY_Right : 32|10@1+ (1,0) [0|500] "cm"  AVM
 SG_ BCoordinateX_Right : 44|12@1+ (1,0) [0|3600] "cm"  AVM
 SG_ ACoordinateY_Right : 8|10@1+ (1,0) [0|500] "cm"  AVM
 SG_ ACoordinateX_Right : 20|12@1+ (1,0) [0|3600] "cm"  AVM
 SG_ Checksum_PDC_12 : 0|8@1+ (1,0) [0|255] ""  AVM

BO_ 456 PDC_11: 8 APA
 SG_ LiveCounter_PDC_11 : 60|4@1+ (1,0) [0|15] "Pulse"  AVM,ADV
 SG_ DCoordinateX_Left : 44|12@1+ (1,0) [0|3600] "cm"  AVM,ADV
 SG_ DCoordinateY_Left : 32|10@1+ (1,0) [0|500] "cm"  AVM,ADV
 SG_ CCoordinateX_Left : 20|12@1+ (1,0) [0|3600] "cm"  AVM,ADV
 SG_ CCoordinateY_Left : 8|10@1+ (1,0) [0|500] "cm"  AVM,ADV
 SG_ Checksum_PDC_11 : 0|8@1+ (1,0) [0|255] ""  AVM,ADV

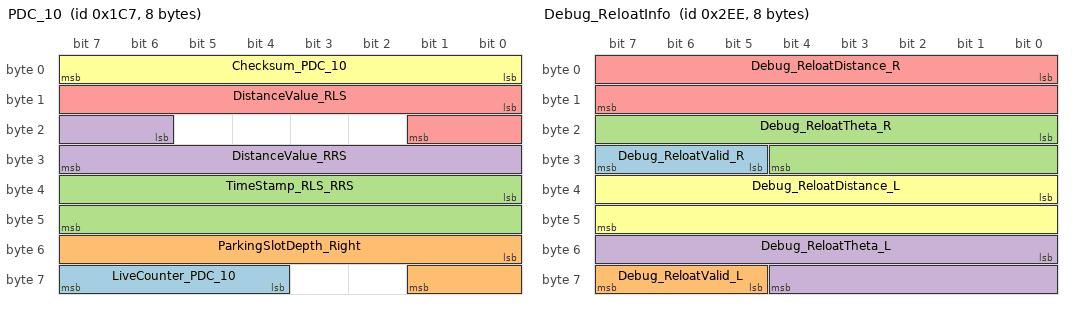
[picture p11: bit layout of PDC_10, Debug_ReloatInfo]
BO_ 455 PDC_10: 8 APA
 SG_ LiveCounter_PDC_10 : 60|4@1+ (1,0) [0|15] "Pulse"  AVM,ADV
 SG_ ParkingSlotDepth_Right : 48|10@1+ (1,0) [0|500] "cm"  AVM,ADV
 SG_ TimeStamp_RLS_RRS : 32|16@1+ (1,0) [0|65535] "ms"  AVM,ADV
 SG_ DistanceValue_RRS : 22|10@1+ (1,0) [0|500] "cm"  AVM,ADV
 SG_ DistanceValue_RLS : 8|10@1+ (1,0) [0|500] "cm"  AVM,ADV
 SG_ Checksum_PDC_10 : 0|8@1+ (1,0) [0|255] ""  AVM,ADV

BO_ 751 Debug_CanStaInfo: 8 APA
 SG_ CanTaskAlive : 16|16@1+ (1,0) [0|0] "" Vector__XXX
 SG_ PubuicCanSta : 8|8@1+ (1,0) [0|0] "" Vector__XXX
 SG_ PrivateCanSta : 0|8@1+ (1,0) [0|0] "" Vector__XXX

BO_ 750 Debug_ReloatInfo: 8 APA
 SG_ Debug_ReloatValid_R : 29|3@1+ (1,0) [0|7] "" Vector__XXX
 SG_ Debug_ReloatValid_L : 61|3@1+ (1,0) [0|7] "" Vector__XXX
 SG_ Debug_ReloatTheta_R : 16|13@1- (0.1,0) [-409.6|409.5] "deg" Vector__XXX
 SG_ Debug_ReloatTheta_L : 48|13@1- (0.1,0) [-409.6|409.5] "deg" Vector__XXX
 SG_ Debug_ReloatDistance_R : 0|16@1+ (1,0) [0|65535] "mm" Vector__XXX
 SG_ Debug_ReloatDistance_L : 32|16@1+ (1,0) [0|65535] "mm" Vector__XXX

BO_ 747 TargetSlot_AB: 8 APA
 SG_ TargetSlot_By : 48|16@1- (1,0) [-32768|32767] "mm" Vector__XXX
 SG_ TargetSlot_Bx : 32|16@1- (1,0) [-32768|32767] "mm" Vector__XXX
 SG_ TargetSlot_Ay : 16|16@1- (1,0) [-32768|32767] "mm" Vector__XXX
 SG_ TargetSlot_Ax : 0|16@1- (1,0) [-32768|32767] "mm" Vector__XXX

BO_ 749 TargetPointInfo: 8 APA
 SG_ FV_TargetPoint_Y : 32|16@1- (0.001,0) [-32.768|32.767] "mm" Vector__XXX
 SG_ FV_TargetPoint_X : 16|16@1- (0.001,0) [-32.768|32.767] "mm" Vector__XXX
 SG_ FV_TargetPoint_Angle : 0|16@1- (0.0001,0) [-3.2768|3.2767] "rad" Vector__XXX

BO_ 748 TargetSlot_CD: 8 APA
 SG_ TargetSlot_Dy : 48|16@1- (1,0) [-32768|32767] "mm" Vector__XXX
 SG_ TargetSlot_Dx : 32|16@1- (1,0) [-32768|32767] "mm" Vector__XXX
 SG_ TargetSlot_Cy : 16|16@1- (1,0) [-32768|32767] "mm" Vector__XXX
 SG_ TargetSlot_Cx : 0|16@1- (1,0) [-32768|32767] "mm" Vector__XXX

BO_ 737 DR_2: 8 APA
 SG_ USS_SLOT_R_DEPTH : 48|16@1+ (1,0) [0|65535] "mm" Vector__XXX
 SG_ USS_SLOT_L_DEPTH : 32|16@1+ (1,0) [0|65535] "mm" Vector__XXX
 SG_ DR_RAW : 0|32@1+ (1,0) [0|4294967295] "" Vector__XXX

BO_ 736 DR_1: 8 APA
 SG_ DR_Y : 32|32@1- (1,0) [-2147483648|2147483647] "mm" Vector__XXX
 SG_ DR_X : 0|32@1- (1,0) [-2147483648|2147483647] "mm" Vector__XXX

BO_ 578 PLG_1: 8 Gateway
 SG_ LuggageDoorSt : 0|1@1+ (1,0) [0|0] ""  APA

BO_ 588 PDCU_1: 8 Gateway
 SG_ MirrorFoldSt_FR : 34|2@1+ (1,0) [0|0] ""  APA
 SG_ DoorSt_FR : 2|1@1+ (1,0) [0|0] ""  APA

BO_ 656 IC_1: 8 Gateway
 SG_ OdometerValue : 24|25@1+ (0.1,0) [0|3355443] "km"  APA

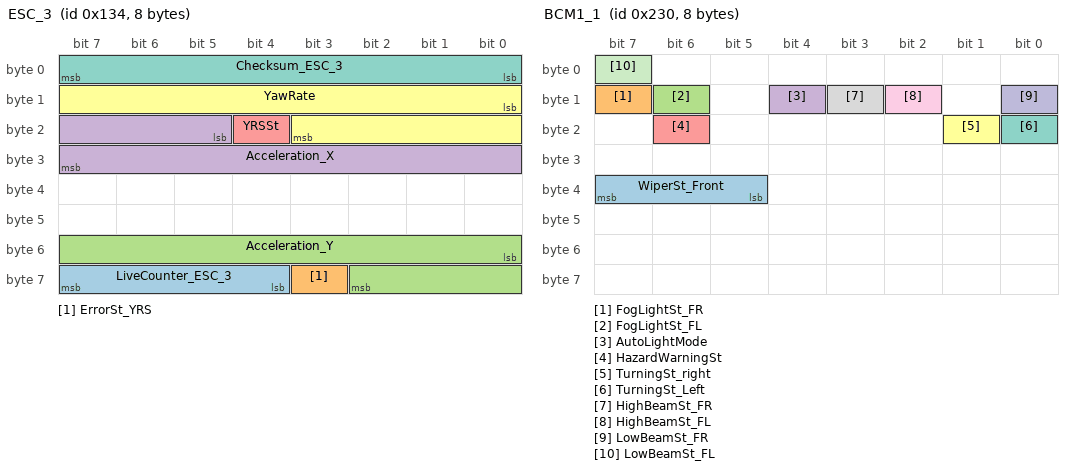
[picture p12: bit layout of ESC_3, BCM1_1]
BO_ 308 ESC_3: 8 Gateway
 SG_ LiveCounter_ESC_3 : 60|4@1+ (1,0) [0|15] ""  APA
 SG_ ErrorSt_YRS : 59|1@1+ (1,0) [0|0] ""  APA
 SG_ Acceleration_Y : 48|11@1+ (0.027127,-21.593) [-21.593|21.593184] "m/s2"  APA
 SG_ Acceleration_X : 21|11@1+ (0.027127,-21.593) [-21.593|21.593184] "m/s2"  APA
 SG_ YRSSt : 20|1@1+ (1,0) [0|0] ""  APA
 SG_ YawRate : 8|12@1+ (0.05,-100) [-100|100] "deg/s"  APA
 SG_ Checksum_ESC_3 : 0|8@1+ (1,0) [0|255] ""  APA

BO_ 306 ESC_2: 8 Gateway
 SG_ LiveCounter_ESC_2 : 60|4@1+ (1,0) [0|15] ""  APA
 SG_ WorkingSt_EPB : 48|2@1+ (1,0) [0|0] ""  APA
 SG_ Checksum_ESC_2 : 0|8@1+ (1,0) [0|255] ""  APA

BO_ 148 EMS_3: 8 Gateway
 SG_ LiveCounter_EMS_3 : 60|4@1+ (1,0) [0|15] ""  APA
 SG_ BrakePedalSt : 35|2@1+ (1,0) [0|0] ""  APA
 SG_ Checksum_EMS_3 : 0|8@1+ (1,0) [0|255] ""  APA

BO_ 586 DDCU_1: 8 Gateway
 SG_ MirrorFoldSt_FL : 34|2@1+ (1,0) [0|0] ""  APA
 SG_ DoorSt_FL : 2|1@1+ (1,0) [0|0] ""  APA

BO_ 560 BCM1_1: 8 Gateway
 SG_ WiperSt_Front : 37|3@1+ (1,0) [0|0] ""  APA
 SG_ FogLightSt_FR : 15|1@1+ (1,0) [0|0] ""  APA
 SG_ FogLightSt_FL : 14|1@1+ (1,0) [0|0] ""  APA
 SG_ AutoLightMode : 12|1@1+ (1,0) [0|0] ""  APA
 SG_ HazardWarningSt : 22|1@1+ (1,0) [0|0] ""  APA
 SG_ TurningSt_right : 17|1@1+ (1,0) [0|0] ""  APA
 SG_ TurningSt_Left : 16|1@1+ (1,0) [0|0] ""  APA
 SG_ HighBeamSt_FR : 11|1@1+ (1,0) [0|0] ""  APA
 SG_ HighBeamSt_FL : 10|1@1+ (1,0) [0|0] ""  APA
 SG_ LowBeamSt_FR : 8|1@1+ (1,0) [0|0] ""  APA
 SG_ LowBeamSt_FL : 7|1@1+ (1,0) [0|0] ""  APA

BO_ 546 ATC_2: 8 Gateway
 SG_ AmbientTemp : 24|8@1+ (0.5,-40) [-40|86.5] "буC"  APA

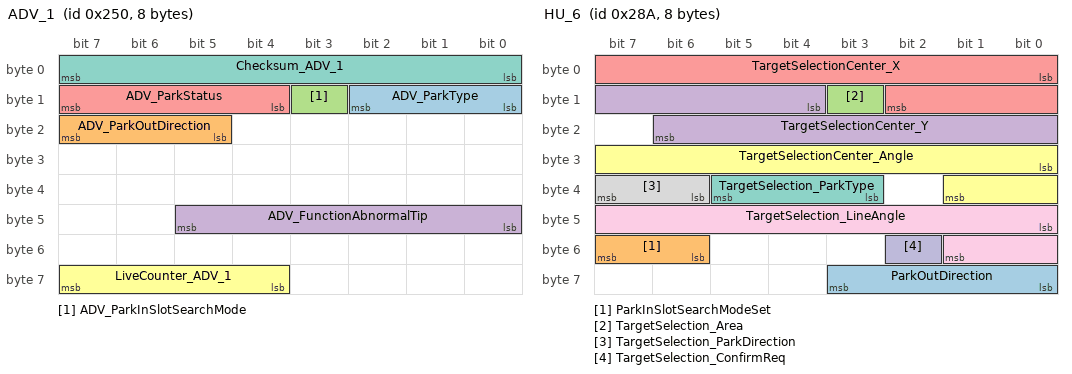
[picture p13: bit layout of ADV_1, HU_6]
BO_ 592 ADV_1: 8 ADV
 SG_ ADV_ParkType : 8|3@1+ (1,0) [0|0] ""  APA
 SG_ ADV_ParkOutDirection : 21|3@1- (1,0) [0|0] ""  APA
 SG_ ADV_ParkInSlotSearchMode : 11|1@1+ (1,0) [0|0] ""  APA
 SG_ ADV_FunctionAbnormalTip : 40|6@1+ (1,0) [0|0] ""  APA
 SG_ ADV_ParkStatus : 12|4@1+ (1,0) [0|0] ""  APA
 SG_ LiveCounter_ADV_1 : 60|4@1+ (1,0) [0|15] "Pulse"  APA
 SG_ Checksum_ADV_1 : 0|8@1+ (1,0) [0|255] ""  APA

BO_ 650 HU_6: 8 Gateway
 SG_ ParkOutDirection : 56|4@1+ (1,0) [0|0] ""  APA
 SG_ ParkInSlotSearchModeSet : 54|2@1+ (1,0) [0|0] ""  APA
 SG_ TargetSelection_Area : 11|1@1+ (1,0) [0|0] ""  APA
 SG_ TargetSelectionCenter_Y : 12|11@1+ (1,-1000) [-1000|1000] "cm"  APA
 SG_ TargetSelectionCenter_X : 0|11@1+ (1,-1000) [-1000|1000] "cm"  APA
 SG_ TargetSelectionCenter_Angle : 24|10@1+ (1,0) [0|360] "degree"  APA
 SG_ TargetSelection_ParkType : 35|3@1+ (1,0) [0|7] ""  APA
 SG_ TargetSelection_ParkDirection : 38|2@1+ (1,0) [0|0] ""  APA
 SG_ TargetSelection_LineAngle : 40|10@1+ (1,0) [0|360] "degree"  APA
 SG_ TargetSelection_ConfirmReq : 50|1@1+ (1,0) [0|0] ""  APA

BO_ 605 PDC_2: 8 APA
 SG_ SensorErrorSt_RRS : 39|1@1+ (1,0) [0|0] ""  AVM,Gateway
 SG_ SensorErrorSt_RLS : 35|1@1+ (1,0) [0|0] ""  AVM,Gateway
 SG_ SensorErrorSt_FRS : 31|1@1+ (1,0) [0|0] ""  AVM,Gateway
 SG_ SensorErrorSt_FLS : 27|1@1+ (1,0) [0|0] ""  AVM,Gateway
 SG_ SensorBlockageSt_RRS : 21|1@1+ (1,0) [0|0] ""  ADV,AVM,Gateway
 SG_ SensorBlockageSt_RLS : 20|1@1+ (1,0) [0|0] ""  ADV,AVM,Gateway
 SG_ SensorBlockageSt_FRS : 19|1@1+ (1,0) [0|0] ""  ADV,AVM,Gateway
 SG_ SensorBlockageSt_FLS : 18|1@1+ (1,0) [0|0] ""  ADV,AVM,Gateway
 SG_ ObjectRange_RRS : 36|3@1+ (1,0) [0|0] ""  AVM,Gateway
 SG_ ObjectRange_RLS : 32|3@1+ (1,0) [0|0] ""  AVM,Gateway
 SG_ ObjectRange_FRS : 28|3@1+ (1,0) [0|0] ""  AVM,Gateway
 SG_ ObjectRange_FLS : 24|3@1+ (1,0) [0|0] ""  AVM,Gateway
 SG_ ParkingSlotDegree_Right : 52|12@1+ (0.1,0) [0|180] "бу"  AVM,Gateway
 SG_ ParkingSlotDegree_Left : 40|12@1+ (0.1,0) [0|180] "бу"  AVM,Gateway
 SG_ SensorBlockageSt_RR : 8|1@1+ (1,0) [0|0] ""  ADV,Gateway,AVM
 SG_ SensorBlockageSt_RMR : 9|1@1+ (1,0) [0|0] ""  ADV,Gateway,AVM
 SG_ SensorBlockageSt_RML : 10|1@1+ (1,0) [0|0] ""  ADV,Gateway,AVM
 SG_ SensorBlockageSt_RL : 11|1@1+ (1,0) [0|0] ""  ADV,Gateway,AVM
 SG_ SensorBlockageSt_FR : 12|1@1+ (1,0) [0|0] ""  ADV,Gateway,AVM
 SG_ SensorBlockageSt_FMR : 13|1@1+ (1,0) [0|0] ""  ADV,Gateway,AVM
 SG_ SensorBlockageSt_FML : 14|1@1+ (1,0) [0|0] ""  ADV,Gateway,AVM
 SG_ SensorBlockageSt_FL : 15|1@1+ (1,0) [0|1] ""  ADV,Gateway,AVM

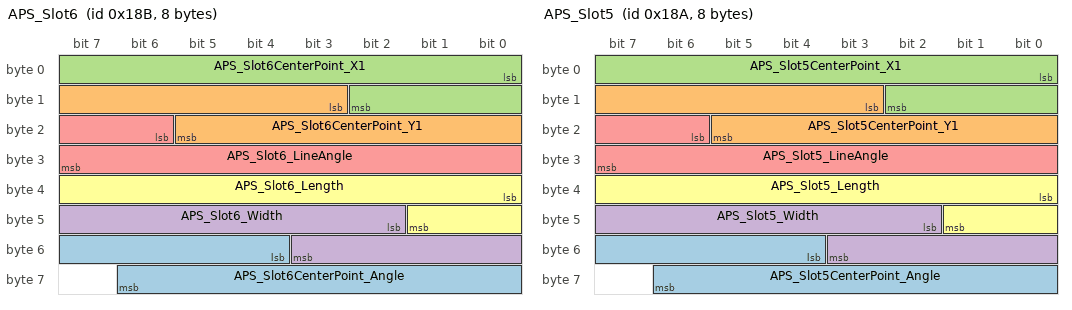
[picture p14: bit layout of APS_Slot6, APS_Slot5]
BO_ 395 APS_Slot6: 8 APA
 SG_ APS_Slot6CenterPoint_Angle : 52|11@1+ (0.1,0) [0|204.7] "degree" Vector__XXX
 SG_ APS_Slot6CenterPoint_Y1 : 11|11@1+ (1,-1000) [-1000|1000] "cm"  ADV,Gateway
 SG_ APS_Slot6CenterPoint_X1 : 0|11@1+ (1,-1000) [-1000|1000] "cm"  ADV,Gateway
 SG_ APS_Slot6_Width : 42|10@1+ (1,0) [0|1000] "cm"  ADV,Gateway
 SG_ APS_Slot6_LineAngle : 22|10@1+ (1,0) [0|360] "degree"  ADV,Gateway
 SG_ APS_Slot6_Length : 32|10@1+ (1,0) [0|1000] "cm"  ADV,Gateway

BO_ 394 APS_Slot5: 8 APA
 SG_ APS_Slot5CenterPoint_Angle : 52|11@1+ (0.1,0) [0|204.7] "degree" Vector__XXX
 SG_ APS_Slot5CenterPoint_Y1 : 11|11@1+ (1,-1000) [-1000|1000] "cm"  ADV,Gateway
 SG_ APS_Slot5CenterPoint_X1 : 0|11@1+ (1,-1000) [-1000|1000] "cm"  ADV,Gateway
 SG_ APS_Slot5_Width : 42|10@1+ (1,0) [0|1000] "cm"  ADV,Gateway
 SG_ APS_Slot5_LineAngle : 22|10@1+ (1,0) [0|360] "degree"  ADV,Gateway
 SG_ APS_Slot5_Length : 32|10@1+ (1,0) [0|1000] "cm"  ADV,Gateway

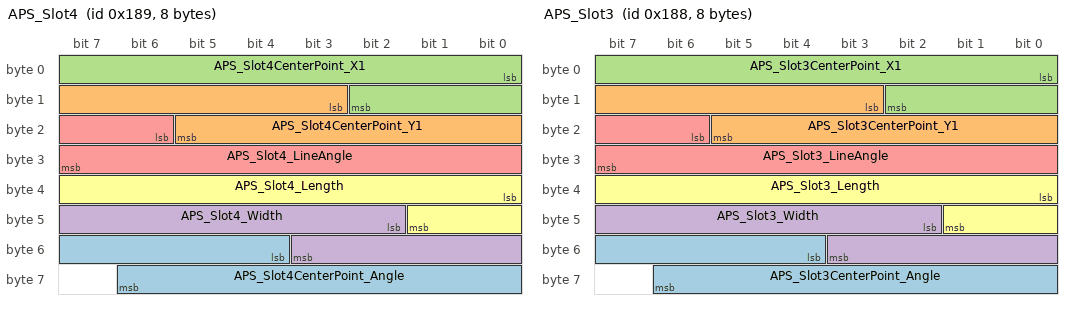
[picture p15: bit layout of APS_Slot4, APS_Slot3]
BO_ 393 APS_Slot4: 8 APA
 SG_ APS_Slot4CenterPoint_Angle : 52|11@1+ (0.1,0) [0|204.7] "degree" Vector__XXX
 SG_ APS_Slot4CenterPoint_Y1 : 11|11@1+ (1,-1000) [-1000|1000] "cm"  ADV,Gateway
 SG_ APS_Slot4CenterPoint_X1 : 0|11@1+ (1,-1000) [-1000|1000] "cm"  ADV,Gateway
 SG_ APS_Slot4_Width : 42|10@1+ (1,0) [0|1023] "cm"  ADV,Gateway
 SG_ APS_Slot4_LineAngle : 22|10@1+ (1,0) [0|360] "degree"  ADV,Gateway
 SG_ APS_Slot4_Length : 32|10@1+ (1,0) [0|1000] "cm"  ADV,Gateway

BO_ 392 APS_Slot3: 8 APA
 SG_ APS_Slot3CenterPoint_Angle : 52|11@1+ (0.1,0) [0|180] "degree" Vector__XXX
 SG_ APS_Slot3CenterPoint_Y1 : 11|11@1+ (1,-1000) [-1000|1000] "cm"  ADV,Gateway
 SG_ APS_Slot3CenterPoint_X1 : 0|11@1+ (1,-1000) [-1000|1000] "cm"  ADV,Gateway
 SG_ APS_Slot3_Width : 42|10@1+ (1,0) [0|1000] "cm"  ADV,Gateway
 SG_ APS_Slot3_LineAngle : 22|10@1+ (1,0) [0|360] "degree"  ADV,Gateway
 SG_ APS_Slot3_Length : 32|10@1+ (1,0) [0|1000] "cm"  ADV,Gateway

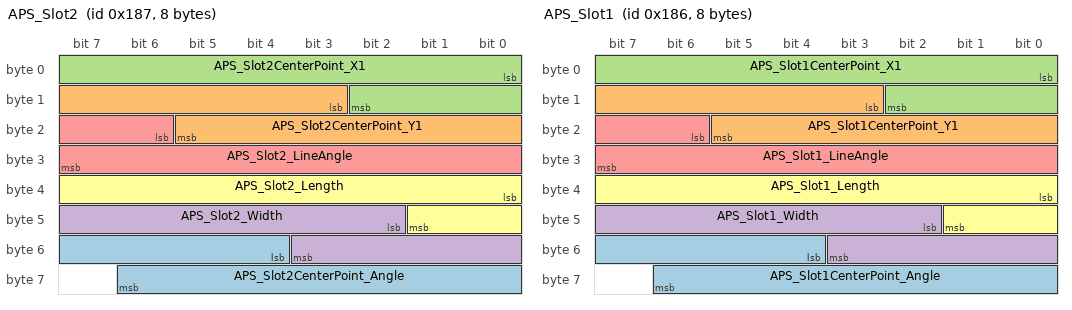
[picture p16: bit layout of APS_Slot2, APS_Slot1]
BO_ 391 APS_Slot2: 8 APA
 SG_ APS_Slot2CenterPoint_Angle : 52|11@1+ (0.1,0) [0|204.7] "degree" Vector__XXX
 SG_ APS_Slot2CenterPoint_Y1 : 11|11@1+ (1,-1000) [-1000|1000] "cm"  ADV,Gateway
 SG_ APS_Slot2CenterPoint_X1 : 0|11@1+ (1,-1000) [-1000|1000] "cm"  ADV,Gateway
 SG_ APS_Slot2_Width : 42|10@1+ (1,0) [0|1000] "cm"  ADV,Gateway
 SG_ APS_Slot2_LineAngle : 22|10@1+ (1,0) [0|360] "degree"  ADV,Gateway
 SG_ APS_Slot2_Length : 32|10@1+ (1,0) [0|1000] "cm"  ADV,Gateway

BO_ 390 APS_Slot1: 8 APA
 SG_ APS_Slot1CenterPoint_Angle : 52|11@1+ (0.1,0) [0|204.7] "degree" Vector__XXX
 SG_ APS_Slot1CenterPoint_Y1 : 11|11@1+ (1,-1000) [-1000|1000] "cm"  ADV,Gateway
 SG_ APS_Slot1CenterPoint_X1 : 0|11@1+ (1,-1000) [-1000|1000] "cm"  ADV,Gateway
 SG_ APS_Slot1_Width : 42|10@1+ (1,0) [0|1000] "cm"  ADV,Gateway
 SG_ APS_Slot1_LineAngle : 22|10@1+ (1,0) [0|360] "degree"  ADV,Gateway
 SG_ APS_Slot1_Length : 32|10@1+ (1,0) [0|1000] "cm"  ADV,Gateway

BO_ 388 APS_PSD: 8 APA
 SG_ APS_ParkingSlotAvailability : 63|1@1+ (1,0) [0|0] "" Vector__XXX
 SG_ APS_Slot6_BothSidesInfo : 58|2@1+ (1,0) [0|0] ""  Gateway,ADV
 SG_ APS_Slot5_BothSidesInfo : 56|2@1+ (1,0) [0|0] ""  Gateway,ADV
 SG_ APS_Slot3_BothSidesInfo : 52|2@1+ (1,0) [0|0] ""  Gateway,ADV
 SG_ APS_Slot4_BothSidesInfo : 54|2@1+ (1,0) [0|0] ""  Gateway,ADV
 SG_ APS_Slot2_BothSidesInfo : 50|2@1+ (1,0) [0|0] ""  Gateway,ADV
 SG_ APS_Slot1_BothSidesInfo : 48|2@1+ (1,0) [0|0] ""  Gateway,ADV
 SG_ APS_Slot6_ParkType : 44|2@1+ (1,0) [0|0] ""  Gateway,ADV
 SG_ APS_Slot6_ParkDirection : 46|1@1+ (1,0) [0|0] ""  Gateway,ADV
 SG_ APS_Slot6_Info : 42|2@1+ (1,0) [0|0] ""  Gateway,ADV
 SG_ APS_Slot6_DetectStatus : 40|2@1+ (1,0) [0|0] ""  Gateway,ADV
 SG_ APS_Slot5_ParkType : 36|2@1+ (1,0) [0|0] ""  Gateway,ADV
 SG_ APS_Slot5_ParkDirection : 38|1@1+ (1,0) [0|0] ""  Gateway,ADV
 SG_ APS_Slot5_Info : 34|2@1+ (1,0) [0|0] ""  Gateway,ADV
 SG_ APS_Slot5_DetectStatus : 32|2@1+ (1,0) [0|0] ""  Gateway,ADV
 SG_ APS_Slot4_ParkType : 28|2@1+ (1,0) [0|0] ""  Gateway,ADV
 SG_ APS_Slot4_ParkDirection : 30|1@1+ (1,0) [0|0] ""  Gateway,ADV
 SG_ APS_Slot4_Info : 26|2@1+ (1,0) [0|0] ""  Gateway,ADV
 SG_ APS_Slot4_DetectStatus : 24|2@1+ (1,0) [0|0] ""  Gateway,ADV
 SG_ APS_Slot3_ParkType : 20|2@1+ (1,0) [0|0] ""  Gateway,ADV
 SG_ APS_Slot3_ParkDirection : 22|1@1+ (1,0) [0|0] ""  Gateway,ADV
 SG_ APS_Slot3_Info : 18|2@1+ (1,0) [0|0] ""  Gateway,ADV
 SG_ APS_Slot3_DetectStatus : 16|2@1+ (1,0) [0|0] ""  Gateway,ADV
 SG_ APS_Slot2_ParkType : 12|2@1+ (1,0) [0|0] ""  Gateway,ADV
 SG_ APS_Slot2_ParkDirection : 14|1@1+ (1,0) [0|0] ""  Gateway,ADV
 SG_ APS_Slot2_Info : 10|2@1+ (1,0) [0|0] ""  Gateway,ADV
 SG_ APS_Slot2_DetectStatus : 8|2@1+ (1,0) [0|0] ""  Gateway,ADV
 SG_ APS_Slot1_ParkType : 4|2@1+ (1,0) [0|0] ""  Gateway,ADV
 SG_ APS_Slot1_ParkDirection : 6|1@1+ (1,0) [0|0] ""  Gateway,ADV
 SG_ APS_Slot1_Info : 2|2@1+ (1,0) [0|0] ""  Gateway,ADV
 SG_ APS_Slot1_DetectStatus : 0|2@1+ (1,0) [0|0] ""  Gateway,ADV

BO_ 604 PDC_1: 8 APA
 SG_ PDC_FunctionTip : 61|3@1+ (1,0) [0|0] ""  Gateway
 SG_ BuzzerAlarmPosition : 8|3@1+ (1,0) [0|0] ""  Gateway
 SG_ RadarSysSt_RearSide : 12|1@1+ (1,0) [0|0] ""  Gateway
 SG_ RadarSysSt_FrontSide : 11|1@1+ (1,0) [0|0] ""  Gateway
 SG_ BuzzerSwitchSt : 13|1@1+ (1,0) [0|0] ""  Gateway
 SG_ SwitchScreenRequest_PDC : 54|2@1+ (1,0) [0|0] ""  Gateway
 SG_ PDCAutoOnFunctionInd : 53|1@1+ (1,0) [0|0] ""  Gateway
 SG_ SensorErrorSt_FL : 47|1@1+ (1,0) [0|0] ""  Gateway
 SG_ ObjectRange_FL : 44|3@1+ (1,0) [0|0] ""  Gateway
 SG_ SensorErrorSt_FML : 43|1@1+ (1,0) [0|0] ""  Gateway
 SG_ ObjectRange_FML : 40|3@1+ (1,0) [0|0] ""  Gateway
 SG_ SensorErrorSt_FMR : 39|1@1+ (1,0) [0|0] ""  Gateway
 SG_ ObjectRange_FMR : 36|3@1+ (1,0) [0|0] ""  Gateway
 SG_ SensorErrorSt_FR : 35|1@1+ (1,0) [0|0] ""  Gateway
 SG_ ObjectRange_FR : 32|3@1+ (1,0) [0|0] ""  Gateway
 SG_ SensorErrorSt_RL : 31|1@1+ (1,0) [0|0] ""  Gateway
 SG_ ObjectRange_RL : 28|3@1+ (1,0) [0|0] ""  Gateway
 SG_ SensorErrorSt_RML : 27|1@1+ (1,0) [0|0] ""  Gateway
 SG_ ObjectRange_RML : 24|3@1+ (1,0) [0|0] ""  Gateway
 SG_ SensorErrorSt_RMR : 23|1@1+ (1,0) [0|0] ""  Gateway
 SG_ ObjectRange_RMR : 20|3@1+ (1,0) [0|0] ""  Gateway
 SG_ SensorErrorSt_RR : 19|1@1+ (1,0) [0|0] ""  Gateway
 SG_ ObjectRange_RR : 16|3@1+ (1,0) [0|0] ""  Gateway
 SG_ BuzeerCmd_PDC : 5|3@1+ (1,0) [0|7] ""  Gateway
 SG_ RadarSysSt_Rear : 3|1@1+ (1,0) [0|1] ""  ADV,Gateway
 SG_ RadarSysSt_Front : 2|1@1+ (1,0) [0|0] ""  ADV,Gateway
 SG_ ErrorSt_PDC : 1|1@1+ (1,0) [0|0] ""  ADV,Gateway,APA
 SG_ SysSt_PDC : 0|1@1+ (1,0) [0|0] ""  ADV,Gateway,APA
 SG_ PDC_SearchingSlotPosition : 59|2@1+ (1,0) [0|0] ""  Gateway
 SG_ PDC_SpeechControlFeedback : 56|3@1+ (1,0) [0|0] ""  Gateway

BO_ 180 TCU_3: 8 Gateway
 SG_ LiveCounter_TCU_3 : 60|4@1+ (1,0) [0|15] ""  APA
 SG_ Checksum_TCU_3 : 0|8@1+ (1,0) [0|255] ""  APA
 SG_ LeverInfo : 56|4@1+ (1,0) [0|0] ""  APA

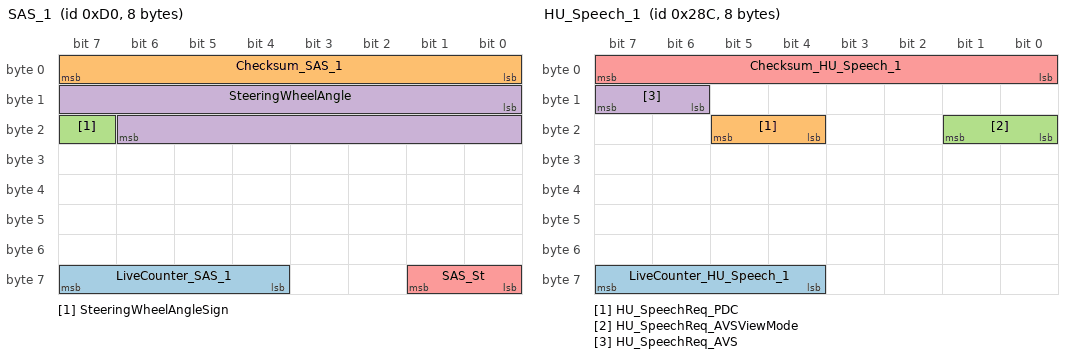
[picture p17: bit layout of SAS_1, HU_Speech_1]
BO_ 208 SAS_1: 8 Gateway
 SG_ LiveCounter_SAS_1 : 60|4@1+ (1,0) [0|15] ""  APA
 SG_ Checksum_SAS_1 : 0|8@1+ (1,0) [0|255] ""  APA
 SG_ SteeringWheelAngleSign : 23|1@1+ (1,0) [0|0] ""  APA
 SG_ SteeringWheelAngle : 8|15@1+ (0.04375,0) [0|1433.5125] "бу"  APA
 SG_ SAS_St : 56|2@1+ (1,0) [0|0] ""  APA

BO_ 652 HU_Speech_1: 8 Gateway
 SG_ LiveCounter_HU_Speech_1 : 60|4@1+ (1,0) [0|0] "Pulse"  APA
 SG_ HU_SpeechReq_PDC : 20|2@1+ (1,0) [0|0] ""  APA
 SG_ HU_SpeechReq_AVSViewMode : 16|2@1+ (1,0) [0|0] ""  APA
 SG_ HU_SpeechReq_AVS : 14|2@1+ (1,0) [0|0] ""  APA
 SG_ Checksum_HU_Speech_1 : 0|8@1+ (1,0) [0|255] ""  APA

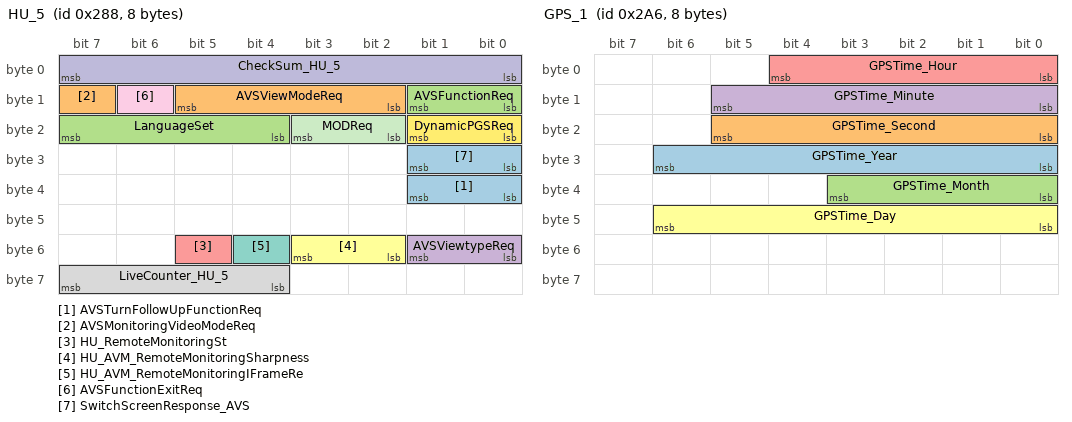
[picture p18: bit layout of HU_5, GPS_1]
BO_ 648 HU_5: 8 Gateway
 SG_ AVSTurnFollowUpFunctionReq : 32|2@1+ (1,0) [0|0] ""  APA
 SG_ AVSMonitoringVideoModeReq : 15|1@1+ (1,0) [0|0] ""  APA
 SG_ AVSFunctionReq : 8|2@1+ (1,0) [0|0] ""  APA
 SG_ AVSViewtypeReq : 48|2@1+ (1,0) [0|0] ""  APA
 SG_ HU_RemoteMonitoringSt : 53|1@1+ (1,0) [0|0] "" Vector__XXX
 SG_ HU_AVM_RemoteMonitoringSharpness : 50|2@1+ (1,0) [0|0] "" Vector__XXX
 SG_ HU_AVM_RemoteMonitoringIFrameRe : 52|1@1+ (1,0) [0|0] "" Vector__XXX
 SG_ LiveCounter_HU_5 : 60|4@1+ (1,0) [0|15] "pulse"  APA
 SG_ AVSFunctionExitReq : 14|1@1+ (1,0) [0|0] ""  APA
 SG_ CheckSum_HU_5 : 0|8@1+ (1,0) [0|255] ""  APA
 SG_ MODReq : 18|2@1+ (1,0) [0|0] ""  APA
 SG_ DynamicPGSReq : 16|2@1+ (1,0) [0|0] ""  APA
 SG_ SwitchScreenResponse_AVS : 24|2@1+ (1,0) [0|0] ""  APA
 SG_ AVSViewModeReq : 10|4@1+ (1,0) [0|0] ""  APA
 SG_ LanguageSet : 20|4@1+ (1,0) [0|0] ""  APA

BO_ 562 BCM1_2: 8 Gateway
 SG_ PowerMode : 4|4@1+ (1,0) [0|0] ""  APA

BO_ 678 GPS_1: 8 Gateway
 SG_ GPSTime_Year : 24|7@1+ (1,0) [0|125] "year"  APA
 SG_ GPSTime_Second : 16|6@1+ (1,0) [0|59] "minute"  APA
 SG_ GPSTime_Month : 32|4@1+ (1,0) [1|12] "month"  APA
 SG_ GPSTime_Minute : 8|6@1+ (1,0) [0|59] "minute"  APA
 SG_ GPSTime_Hour : 0|5@1+ (1,0) [0|23] "hour"  APA
 SG_ GPSTime_Day : 40|7@1+ (1,0) [1|31] "day"  APA

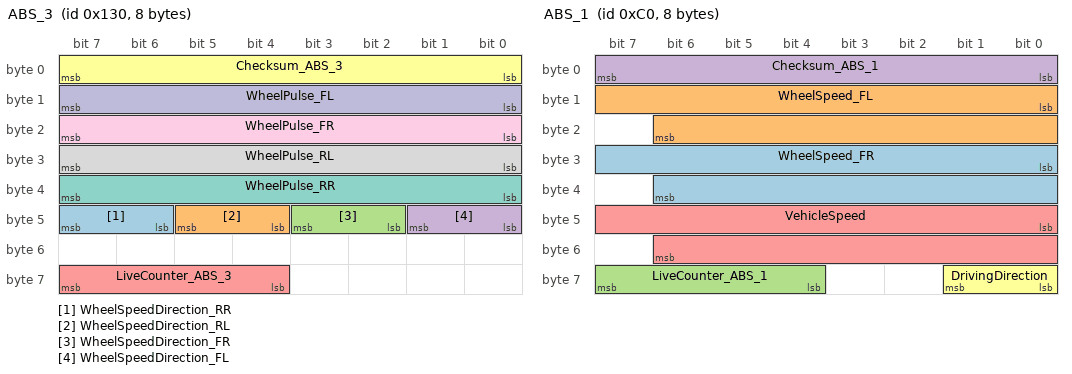
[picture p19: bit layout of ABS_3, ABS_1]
BO_ 304 ABS_3: 8 Gateway
 SG_ WheelSpeedDirection_RR : 46|2@1+ (1,0) [0|0] ""  APA
 SG_ WheelSpeedDirection_RL : 44|2@1+ (1,0) [0|0] ""  APA
 SG_ WheelSpeedDirection_FR : 42|2@1+ (1,0) [0|0] ""  APA
 SG_ WheelSpeedDirection_FL : 40|2@1+ (1,0) [0|0] ""  APA
 SG_ LiveCounter_ABS_3 : 60|4@1+ (1,0) [0|15] ""  APA
 SG_ Checksum_ABS_3 : 0|8@1+ (1,0) [0|255] ""  APA
 SG_ WheelPulse_RR : 32|8@1+ (1,0) [0|253] ""  APA
 SG_ WheelPulse_RL : 24|8@1+ (1,0) [0|253] ""  APA
 SG_ WheelPulse_FR : 16|8@1+ (1,0) [0|253] ""  APA
 SG_ WheelPulse_FL : 8|8@1+ (1,0) [0|253] ""  APA

BO_ 194 ABS_2: 8 Gateway
 SG_ WheelSpeed_RR : 24|15@1+ (0.01,0) [0|327.65] "km/h"  APA
 SG_ WheelSpeed_RL : 8|15@1+ (0.01,0) [0|327.65] "km/h"  APA
 SG_ LiveCounter_ABS_2 : 60|4@1+ (1,0) [0|15] ""  APA
 SG_ Checksum_ABS_2 : 0|8@1+ (1,0) [0|255] ""  APA

BO_ 192 ABS_1: 8 Gateway
 SG_ WheelSpeed_FR : 24|15@1+ (0.01,0) [0|327.65] "km/h"  APA
 SG_ WheelSpeed_FL : 8|15@1+ (0.01,0) [0|327.65] "km/h"  APA
 SG_ LiveCounter_ABS_1 : 60|4@1+ (1,0) [0|15] ""  APA
 SG_ Checksum_ABS_1 : 0|8@1+ (1,0) [0|255] ""  APA
 SG_ VehicleSpeed : 40|15@1+ (0.01,0) [0|327.65] "km/h"  APA
 SG_ DrivingDirection : 56|2@1+ (1,0) [0|0] ""  APA

BO_ 1422 AVM_NM: 8 APA
 SG_ Extension_information : 32|8@1+ (1,0) [0|0] "" Vector__XXX
 SG_ Stay_awake_reason : 24|8@1+ (1,0) [0|0] "" Vector__XXX
 SG_ Wakeup_reason : 16|8@1+ (1,0) [0|0] "" Vector__XXX

BO_ 2015 Diag_Fun_Req: 8 Gateway
 SG_ Diag_Fun_Req : 0|64@1+ (1,0) [0|0] ""  APA,Gateway

BO_ 1838 AVM_Phy_Resp: 8 APA
 SG_ AVM_Phy_Resp : 0|64@1+ (1,0) [0|0] ""  Gateway

BO_ 1830 AVM_Phy_Req: 8 Gateway
 SG_ AVM_Phy_Req : 0|64@1+ (1,0) [0|0] ""  APA

BO_ 600 AVS_1: 8 APA
 SG_ TurnFollowUpFunctionInd : 57|1@1+ (1,0) [0|0] "" Vector__XXX
 SG_ RemoteMonitoringSt_AVS : 55|1@1+ (1,0) [0|0] ""  Gateway
 SG_ RemoteMonitoringSharpnessSt_AVS : 54|1@1+ (1,0) [0|0] ""  Gateway
 SG_ RemoteMonitoringModeSt_AVS : 56|1@1+ (1,0) [0|0] ""  Gateway
 SG_ FoundSlotBuzzerTip : 27|1@1+ (1,0) [0|0] ""  Gateway
 SG_ BlindSpotFilledFunctionInd : 26|1@1+ (1,0) [0|0] ""  Gateway
 SG_ AVSViewtype : 6|2@1+ (1,0) [0|0] ""  Gateway
 SG_ AVSCameraBlockageSt_Right : 40|1@1+ (1,0) [0|0] ""  Gateway
 SG_ AVSCameraBlockageSt_Rear : 38|1@1+ (1,0) [0|0] ""  Gateway
 SG_ AVSCameraBlockageSt_Left : 39|1@1+ (1,0) [0|0] ""  Gateway
 SG_ AVSCameraBlockageSt_Front : 37|1@1+ (1,0) [0|0] ""  Gateway
 SG_ AVS_RemoteViewModeFeedback : 59|5@1+ (1,0) [0|0] ""  Gateway
 SG_ AVS_RemoteSharpnessFeedback : 51|3@1+ (1,0) [0|0] ""  Gateway
 SG_ AVS_RemoteMonitorigFeedback : 48|3@1+ (1,0) [0|0] ""  Gateway
 SG_ AVS_PDWarning_Rear : 47|1@1+ (1,0) [0|0] ""  Gateway
 SG_ AVS_PDWarning_Front : 46|1@1+ (1,0) [0|0] ""  Gateway
 SG_ AVS_CalibrationSt : 44|2@1+ (1,0) [0|0] ""  Gateway
 SG_ AVS_AbnormalTip : 41|3@1+ (1,0) [0|0] ""  Gateway
 SG_ AVSViewMode : 2|4@1+ (1,0) [0|0] ""  Gateway
 SG_ AVSErrorSt : 1|1@1+ (1,0) [0|0] ""  Gateway
 SG_ SwitchScreenRequest_AVS : 24|2@1+ (1,0) [0|0] ""  Gateway
 SG_ AVSCameraErrorSt_Right : 11|1@1+ (1,0) [0|0] ""  Gateway
 SG_ AVSCameraErrorSt_Rear : 9|1@1+ (1,0) [0|0] ""  Gateway
 SG_ MODSt_AVS : 17|1@1+ (1,0) [0|0] ""  Gateway
 SG_ AVSTurnLightFollowupFunctionSt : 20|1@1+ (1,0) [0|0] ""  Gateway
 SG_ MODWarning_Rear : 19|1@1+ (1,0) [0|0] ""  Gateway
 SG_ MODWarning_Front : 18|1@1+ (1,0) [0|0] ""  Gateway
 SG_ AVSCameraErrorSt_Left : 10|1@1+ (1,0) [0|0] ""  Gateway
 SG_ LanguageTypeSt_AVS : 12|4@1+ (1,0) [0|0] ""  Gateway
 SG_ AVSCameraErrorSt_Front : 8|1@1+ (1,0) [0|0] ""  Gateway
 SG_ DynamicPGSSt_AVS : 16|1@1+ (1,0) [0|0] ""  Gateway
 SG_ AVSSt : 0|1@1+ (1,0) [0|0] ""  Gateway
 SG_ AVS_SpeechControlFeedback : 32|5@1+ (1,0) [0|0] ""  Gateway

CM_ "

";
CM_ BO_ 3221225472 "This is a message for not used signals, created by Vector CANdb++ DBC OLE DB Provider.";
CM_ SG_ 3221225472 PDC_SwitchScreenRequest "PDC request IVI to switch the screen in case of object detected.";
CM_ SG_ 3221225472 PDC_BuzzerSwitchSt "This signal indicates the buzzer switch status.";
CM_ SG_ 3221225472 PDC_AutoOnFunctionInd "This signal indicates if the PDC auto on function on or not.";
CM_ SG_ 3221225472 PDC_SideRadarSystemStatus "Side Rada rSystem is off or on";
CM_ SG_ 3221225472 PDC_RRLevel "Rear right radar level,level1 indicates the nearest distance";
CM_ SG_ 3221225472 PDC_RLLevel "Rear left radar level,level1 indicates the nearest distance";
CM_ SG_ 3221225472 PDC_RearRadarSystemStatus "Rear Rada rSystem is off or on";
CM_ SG_ 3221225472 PDC_FrontRadarSystemStatus "Front Rada rSystem is off or on";
CM_ SG_ 3221225472 PDC_FRLevel "Front right radar level,level1 indicates the nearest distance";
CM_ SG_ 3221225472 PDC_FLLevel "Front left radar level,level1 indicates the nearest distance";
CM_ SG_ 3221225472 PDC_CenterRRLevel "Centrer rear right radar level,level1 indicates the nearest distance";
CM_ SG_ 3221225472 PDC_CenterRLLevel "Centrer rear left radar level,level1 indicates the nearest distance";
CM_ SG_ 3221225472 PDC_CenterFRLevel "Centrer front right radar level,level1 indicates the nearest distance";
CM_ SG_ 3221225472 PDC_CenterFLLevel "Centrer front left radar level,level1 indicates the nearest distance";
CM_ SG_ 3221225472 PDC_BuzzerControl "Radar buzzer control";
CM_ SG_ 3221225472 PDC_RightLongDistSensorErrSta "Error status of Right Long Distance sensor";
CM_ SG_ 3221225472 PDC_LeftLongDistSensorErrSta "Error status of Left Long Distance sensor";
CM_ SG_ 3221225472 PDC_RRSensorErrorStatus "Error status of rear right PDC radar sensor";
CM_ SG_ 3221225472 PDC_CenterRRSensorErrorStatus "Error status of center rear right PDC radar sensor";
CM_ SG_ 3221225472 PDC_CenterRLSensorErrorStatus "Error status of center rear left PDC radar sensor";
CM_ SG_ 3221225472 PDC_RLSensorErrorStatus "Error status of rear left PDC radar sensor";
CM_ SG_ 3221225472 PDC_FRSensorErrorStatus "Error status of front right PDC radar sensor";
CM_ SG_ 3221225472 PDC_CenterFRSensorErrorStatus "Error status of center front right PDC radar sensor";
CM_ SG_ 3221225472 PDC_CenterFLSensorErrorStatus "Error status of center front left PDC radar sensor";
CM_ SG_ 3221225472 PDC_FLSensorErrorStatus "Error status of front left PDC radar sensor";
CM_ SG_ 3221225472 AY1Offset "Lateral acceleration offset value";
CM_ SG_ 3221225472 AX1Offset "Longitudinal acceleration offset value";
CM_ SG_ 3221225472 YawRateOffset "Yaw rate offset value";
CM_ SG_ 3221225472 LiveCounter_YRS2 "Live counter for YRS_2";
CM_ SG_ 3221225472 Checksum_YRS2 "Checksum of YRS_2";
CM_ SG_ 3221225472 BCM_RightTurnLightCmd "94times/min:BCM first sends value б░1б▒ continuously for 16 times, then sendsvalue б░0б▒ continuously for 16 times, repeat this send sequence.";
CM_ SG_ 3221225472 BCM_LeftTurnLightCmd "94times/min:BCM first sends value б░1б▒ continuously for 16 times, then sendsvalue б░0б▒ continuously for 16 times, repeat this send sequence.";
CM_ SG_ 3221225472 HU_SpeechRequest_AVMView "Speech request of AVM View";
CM_ SG_ 3221225472 HU_SpeechRequest_AVMandPDC "Speech request of AVM and PDC";
CM_ SG_ 3221225472 HU_PDCFunctionReq "This signal is used to request PDC function on or off.";
CM_ SG_ 3221225472 HU_PDCBuzzerReq "This signal is used to request PDC buzzer on or off.";
CM_ SG_ 3221225472 HU_PDCAutoOnFunctionReq "This signal indicate function of turn the PDC auto on function on or not";
CM_ SG_ 3221225472 HU_PDCAVMFunctionCmd "PDCAVM function activated or deactivated command from Head unit";
CM_ SG_ 3221225472 ScreenPressPosition_X "0x7FE indicates no press";
CM_ SG_ 3221225472 AVS_SpeechControlFeedback "This signal indicates AVS speech control feedback";
CM_ SG_ 3221225472 MODWarning_Right "This signal indicates AVS MOD right 2arning";
CM_ SG_ 3221225472 MODWarning_Left "This signal indicates AVS MOD left warning";
CM_ SG_ 3221225472 CTAWarning_Rear "This signal indicatesAVS CTA rear wide warning";
CM_ SG_ 3221225472 CTAWarning_Front "This signal indicates AVS CTA front wide warning";
CM_ SG_ 3221225472 SensorBlockageSt_RLong "This signal indicates if the right long radar sensor Blockage or not";
CM_ SG_ 3221225472 SensorBlockageSt_Llong "This signal indicates if the left long radar sensor Blockage or not";
CM_ SG_ 3221225472 PDC_SpeechControlFeedback "PDC Speech Control Feedback";
CM_ SG_ 3221225472 SensorErrorSt_RLong "This signal indicates if the right long radar sensor error or not.";
CM_ SG_ 3221225472 SensorErrorSt_LLong "This signal indicates if the left long radar sensor error or not.";
CM_ SG_ 3221225472 RadarSysSt_Side "This signal indicates the working status of the side radar system.";
CM_ SG_ 3221225472 HandParkingBrakeSt "The signal indicates Hand Parking Brake Binding Status.Only for hand brake vehicle";
CM_ SG_ 3221225472 FogLightSt_FR "The signal is indicates the status of front right fog indicator.";
CM_ SG_ 3221225472 FogLightSt_FL "The signal is indicates the status of front left fog indicator.";
CM_ SG_ 3221225472 ParkInSlotSearchModeSet "ParkIn Function Cancel Switch";
CM_ SG_ 3221225472 AVSViewModeReponse "This signal is used to response to AVS view mode";
CM_ SG_ 3221225472 ScreenPressPosition_Y "0x7FE indicates no press";
CM_ SG_ 897 ScreenPressType2 "This signal indicates screen press touch type for touch point 2.";
CM_ SG_ 897 ScreenPressType1 "This signal indicates screen press touch type for touch point 1.";
CM_ SG_ 897 ScreenPressPosition_X1 "ScreenPressPosition_X1";
CM_ SG_ 386 ADV_DebugEnabled "Indicates Debugging is Enabled or not";
CM_ SG_ 386 ADV_TargetTracingWidth "Target Tracing Width";
CM_ SG_ 386 ADV_TargetTracingLength "Target Tracing Length";
CM_ SG_ 386 ADV_TargetTracingAvaialble "Indicates ADV TargetTracing is available or not";
CM_ SG_ 386 ADV_TargetTracingCenter_Y "Target Tracing Center Y";
CM_ SG_ 386 ADV_TargetTracingCenter_X "Target Tracing Center X";
CM_ SG_ 386 ADV_TargetTracingAngle "Target Tracing Angle";
CM_ SG_ 384 ADV_PathTracingAvaialble "Indicates ADV PathTracing is available or not";
CM_ SG_ 384 ADV_RemainingDistance "RemainingDistance";
CM_ SG_ 384 ADV_TotalPathNumber "Total Path Number";
CM_ SG_ 384 ADV_ShortestDistance "The shortest distance";
CM_ SG_ 384 ADV_PathTracingCenter_Y "Path Tracing Center Y";
CM_ SG_ 384 ADV_PathTracingCenter_X "Path Tracing Center X";
CM_ SG_ 384 ADV_CurrentPathNumber "Current Path Number";
CM_ SG_ 384 ADV_CurrentDirection "CurrentDirection";
CM_ SG_ 593 ADV_Alarm_Position_Rear_Right "This signal indicates the rear right radar objects range.";
CM_ SG_ 593 ADV_Alarm_Position_Rear_Left "This signal indicates the rear left radar objects range.";
CM_ SG_ 593 ADV_Alarm_Position_Front_Right "This signal indicates the front right radar objects range.";
CM_ SG_ 593 ADV_Alarm_Position_Front_Left "This signal indicates the front left radar objects range.";
CM_ SG_ 593 LiveCounter_ADV_4 "The Livecounter is used to check the signal consistency of the messages . If the
signals are consecutive, the LiveCounter should also be sequential in the way 0, 1, 2
бн15, 0, 1 бн";
CM_ SG_ 593 ADV_SearchTimeoutCounter "This signal Indicates to display the seconds to exit search process.";
CM_ SG_ 593 ADV_PDCSchedule "This signal indicates the ADV request radar scan schedule of PDC.";
CM_ SG_ 593 ADV_RightSlotSearchType "This signal set the slot search type of right radar";
CM_ SG_ 593 ADV_LeftSlotSearchType "This signal set the slot search type of left radar.";
CM_ SG_ 672 LiveCounter_TBOX_1 "The Livecounter is used to check the signal consistency of the messages . If the
signals are consecutive, the LiveCounter should also be sequential in the way 0, 1, 2
бн15, 0, 1";
CM_ SG_ 672 RemoteAVSViewModeReq "The signals indicates the view mode changing request by remote monitoring.";
CM_ SG_ 672 RemoteAVSSharpnessReq "This signal indicates the remote AVM sharpness request.";
CM_ SG_ 672 RemoteMonitoringReq "This signal indicates the remote monitoring request.";
CM_ SG_ 672 CheckSum_TBOX_1 "The checksum is used to check whether the data from the CPU buffer are shifted
without transmission errors to the CAN communication controller buffer and vice
versa";
CM_ SG_ 591 DoorSt_RR "This signal indicates the state of RR door.";
CM_ SG_ 590 DoorSt_RL "This signal indicates the state of RL door.";
CM_ SG_ 420 MCP_AVSandFRadarSwitch "Indicates the AVS and front radar switch is pressed or not.";
CM_ SG_ 643 LiveCounter_HU_18 "The Livecounter is used to check the signal consistency of the messages . If the
signals are consecutive, the LiveCounter should also be sequential in the way 0, 1, 2
бн15, 0, 1";
CM_ SG_ 643 HU_PDCAutoOnFunctionReq "This signal indicate function of turn the PDC auto on function on or not";
CM_ SG_ 643 HU_BlindSpotFilledFunctionReq "This signal indicate function of turn the blind spot fiiled function on or not";
CM_ SG_ 643 Checksum_HU_18 "The checksum is used to check whether the data from the CPU buffer are shifted
without transmission errors to the CAN communication controller buffer and vice
versa.";
CM_ SG_ 657 DisplayTheme "This signal indicates the display theme of the IVI.";
CM_ SG_ 667 LiveCounter_HU_10 "The Livecounter is used to check the signal consistency of the messages . If the
signals are consecutive, the LiveCounter should also be sequential in the way 0, 1, 2
бн15, 0, 1 бн";
CM_ SG_ 667 HU_PDCBuzzerReq "This signal is used to request PDC buzzer on or off";
CM_ SG_ 667 Checksum_HU_10 "The checksum is used to check whether the data from the CPU buffer are shifted
without transmission errors to the CAN communication controller buffer and vice
versa.";
CM_ SG_ 688 GW_RemoteVehicleMode "The signal indicates the vehicle is in remote mode or not";
CM_ SG_ 688 GW_OTAMode "The signal indicates the vehicle is in OTA mode or not";
CM_ SG_ 534 DMS_VehicleModeinfo "The signal indicates the vehicle mode.
For C095, only ECO,Comfort,Sport,Snow four modes.";
CM_ SG_ 571 Brightness_L "This signal indicate the low precision light intensity expressed in 8 Bit.";
CM_ SG_ 571 Brightness_H "This signal indicate the high precision light intensity expressed in 10 Bit.";
CM_ SG_ 571 Rainlntensity "This signal delivers information about rain intensity: from 0% (no rain) to 100%
(very heavy rain).";
CM_ SG_ 564 EngineHoodSt "This signal shows engine hood status.";
CM_ SG_ 454 DistanceValue_FLS "This signal indicates the obstacle detection distance by front left side radar.0x3FE
means no object was detected.";
CM_ SG_ 454 ParkingSoltDepth_Left "This signal indicates the left parking slot depth.0x3FE means no object was
detected";
CM_ SG_ 454 TimeStamp_FLS_FRS "This signal indicates the time stamp of the obstacle detection distance by front left
side and front right side radar.";
CM_ SG_ 454 DistanceValue_FRS "This signal indicates the obstacle detection distance by front right side radar.0x3FE
means no object was detected.";
CM_ SG_ 454 LiveCounter_PDC_9 "The Livecounter is used to check the signal consistency of the messages . If the
signals are consecutive, the LiveCounter should also be sequential in the way 0, 1, 2
бн15, 0, 1 бн";
CM_ SG_ 454 Checksum_PDC_9 "The checksum is used to check whether the data from the CPU buffer are shifted
without transmission errors to the CAN communication controller buffer and vice
versa.";
CM_ SG_ 453 TxRxSt_RR "Ultrasonic wave transmit and receive status of rear right radar.";
CM_ SG_ 453 TxRxSt_RMR "Ultrasonic wave transmit and receive status of rear middle right radar.";
CM_ SG_ 453 TimeStamp_RMR_RR "This signal indicates the time stamp of the obstacle detection distance by rear
middle right and rear right radar.";
CM_ SG_ 453 DistanceValue_RR "This signal indicates the obstacle detection distance by rear right radar.0x3FE
means no object was detected";
CM_ SG_ 453 DistanceValue_RMR "This signal indicates the obstacle detection distance by rear middle right
radar.0x3FE means no object was detected.";
CM_ SG_ 453 LiveCounter_PDC_8 "The Livecounter is used to check the signal consistency of the messages . If the
signals are consecutive, the LiveCounter should also be sequential in the way 0, 1, 2
бн15, 0, 1 бн";
CM_ SG_ 453 Checksum_PDC_8 "The checksum is used to check whether the data from the CPU buffer are shifted
without transmission errors to the CAN communication controller buffer and vice
versa.";
CM_ SG_ 452 TxRxSt_RML "Ultrasonic wave transmit and receive status of rear middle left radar.";
CM_ SG_ 452 TxRxSt_RL "Ultrasonic wave transmit and receive status of front left radar.";
CM_ SG_ 452 TimeStamp_RML_RL "This signal indicates the time stamp of the obstacle detection distance by rear
middle left and rear left radar";
CM_ SG_ 452 DisstanceValue_RML "This signal indicates the obstacle detection distance by rear middle left radar.0x3FE
means no object was detected";
CM_ SG_ 452 DisstanceValue_RL "This signal indicates the obstacle detection distance by rear left radar.0x3FE means
no object was detected";
CM_ SG_ 452 LiveCounter_PDC_7 "The Livecounter is used to check the signal consistency of the messages . If the
signals are consecutive, the LiveCounter should also be sequential in the way 0, 1, 2
бн15, 0, 1 бн";
CM_ SG_ 452 Checksum_PDC_7 "The checksum is used to check whether the data from the CPU buffer are shifted
without transmission errors to the CAN communication controller buffer and vice
versa.";
CM_ SG_ 451 DistanceValue_FR "This signal indicates the obstacle detection distance by front right radar.0x3FE
means no object was detected";
CM_ SG_ 451 TxRxSt_FR "Ultrasonic wave transmit and receive status of front right radar";
CM_ SG_ 451 TxRxSt_FMR "Ultrasonic wave transmit and receive status of front middle right radar.";
CM_ SG_ 451 TimeStamp_FMR_FR "This signal indicates the time stamp of the obstacle detection distance by front
middle right and front right radar.";
CM_ SG_ 451 DistanceValue_FMR "This signal indicates the obstacle detection distance by front middle right
radar.0x3FE means no object was detected";
CM_ SG_ 451 LiveCounter_PDC_6 "The Livecounter is used to check the signal consistency of the messages . If the
signals are consecutive, the LiveCounter should also be sequential in the way 0, 1, 2
бн15, 0, 1 бн";
CM_ SG_ 451 Checksum_PDC_6 "The checksum is used to check whether the data from the CPU buffer are shifted
without transmission errors to the CAN communication controller buffer and vice
versa.";
CM_ SG_ 450 DistanceValue_FML "This signal indicates the obstacle detection distance by front middle left radar.0x3FE
means no object was detected";
CM_ SG_ 450 LiveCounter_PDC_5 "The Livecounter is used to check the signal consistency of the messages . If the
signals are consecutive, the LiveCounter should also be sequential in the way 0, 1, 2
бн15, 0, 1 бн";
CM_ SG_ 450 DistanceValue_FL "This signal indicates the obstacle detection distance by front left radar.0x3FE means
no object was detected";
CM_ SG_ 450 TimeStamp_FML_FL "This signal indicates the time stamp of the obstacle detection distance by front
middle left and front left radar";
CM_ SG_ 450 TxRxSt_FML "Ultrasonic wave transmit and receive status of front middle left radar.";
CM_ SG_ 450 TxRxSt_FL "Ultrasonic wave transmit and receive status of front left radar.";
CM_ SG_ 450 Checksum_PDC_5 "The checksum is used to check whether the data from the CPU buffer are shifted
without transmission errors to the CAN communication controller buffer and vice
versa.";
CM_ SG_ 449 RearObjCoordinateY "This signal indicates the Y coordinate of rear object";
CM_ SG_ 449 RearObjCoordinateX "This signal indicates the X coordinate of rear object";
CM_ SG_ 449 FrontObjCoordinateY "This signal indicates the Y coordinate of front object.";
CM_ SG_ 449 FrontObjCoordinateX "This signal indicates the X coordinate of front object";
CM_ SG_ 449 LiveCounter_PDC_4 "The Livecounter is used to check the signal consistency of the messages . If the
signals are consecutive, the LiveCounter should also be sequential in the way 0, 1, 2
бн15, 0, 1 бн";
CM_ SG_ 449 Checksum_PDC_4 "The checksum is used to check whether the data from the CPU buffer are shifted
without transmission errors to the CAN communication controller buffer and vice
versa.";
CM_ SG_ 448 LiveCounter_PDC_3 "The Livecounter is used to check the signal consistency of the messages . If the
signals are consecutive, the LiveCounter should also be sequential in the way 0, 1, 2
бн15, 0, 1 бн";
CM_ SG_ 448 BCoordinateY_Left "This signal indicates the Y coordinate of parking cell point B.0x3FE means no object
was detected";
CM_ SG_ 448 BCoordinateX_Left "This signal indicates the X coordinate of parking cell point B.0xFFE means no object
was detected";
CM_ SG_ 448 ACoordinateY_Left "This signal indicates the Y coordinate of parking cell point A.0x3FE means no object
was detected.";
CM_ SG_ 448 ACoordinateX_Left "This signal indicates the X coordinate of parking cell point A.0xFFE means no object
was detected";
CM_ SG_ 448 Checksum_PDC_3 "The checksum is used to check whether the data from the CPU buffer are shifted
without transmission errors to the CAN communication controller buffer and vice
versa.";
CM_ SG_ 459 LiveCounter_PDC_14 "The Livecounter is used to check the signal consistency of the messages . If the
signals are consecutive, the LiveCounter should also be sequential in the way 0, 1, 2
бн15, 0, 1 бн";
CM_ SG_ 459 VehicleCoordinateY "This signal indicates the coordinate Y of vehicle after searched a parking space";
CM_ SG_ 459 VehicleCoordinateX "This signal indicates the coordinate X of vehicle after searched a parking space.";
CM_ SG_ 459 VehicleAngle "This signal indicates the angle of vehicle after searched a parking space.";
CM_ SG_ 459 Checksum_PDC_14 "The checksum is used to check whether the data from the CPU buffer are shifted
without transmission errors to the CAN communication controller buffer and vice
versa.";
CM_ SG_ 458 LiveCounter_PDC_13 "The Livecounter is used to check the signal consistency of the messages . If the
signals are consecutive, the LiveCounter should also be sequential in the way 0, 1, 2
бн15, 0, 1 бн";
CM_ SG_ 458 DCoordinateY_Right "This signal indicates the Y coordinate of parking cell point D.0x3FE means no object
was detected";
CM_ SG_ 458 DCoordinateX_Right "This signal indicates the X coordinate of parking cell point D.0xFFE means no object
was detected";
CM_ SG_ 458 CCoordinateY_Right "This signal indicates the Y coordinate of parking cell point C.0x3FE means no object
was detected";
CM_ SG_ 458 CCoordinateX_Right "This signal indicates the X coordinate of parking cell point C.0xFFE means no object
was detected";
CM_ SG_ 458 Checksum_PDC_13 "The checksum is used to check whether the data from the CPU buffer are shifted
without transmission errors to the CAN communication controller buffer and vice
versa.";
CM_ SG_ 457 LiveCounter_PDC_12 "The Livecounter is used to check the signal consistency of the messages . If the
signals are consecutive, the LiveCounter should also be sequential in the way 0, 1, 2
бн15, 0, 1 бн";
CM_ SG_ 457 BCoordinateY_Right "This signal indicates the Y coordinate of parking cell point B.0x3FE means no object
was detected";
CM_ SG_ 457 BCoordinateX_Right "This signal indicates the X coordinate of parking cell point B.0xFFE means no object
was detected";
CM_ SG_ 457 ACoordinateY_Right "This signal indicates the Y coordinate of parking cell point A.0x3FE means no object
was detected.";
CM_ SG_ 457 ACoordinateX_Right "This signal indicates the X coordinate of parking cell point A.0xFFE means no object
was detected";
CM_ SG_ 457 Checksum_PDC_12 "The checksum is used to check whether the data from the CPU buffer are shifted
without transmission errors to the CAN communication controller buffer and vice
versa.";
CM_ SG_ 456 LiveCounter_PDC_11 "The Livecounter is used to check the signal consistency of the messages . If the
signals are consecutive, the LiveCounter should also be sequential in the way 0, 1, 2
бн15, 0, 1 бн";
CM_ SG_ 456 DCoordinateX_Left "This signal indicates the X coordinate of parking cell point D.0xFFE means no object
was detected";
CM_ SG_ 456 DCoordinateY_Left "This signal indicates the Y coordinate of parking cell point D.0x3FE means no object
was detected.";
CM_ SG_ 456 CCoordinateX_Left "This signal indicates the X coordinate of parking cell point C.0xFFE means no object
was detected";
CM_ SG_ 456 CCoordinateY_Left "This signal indicates the Y coordinate of parking cell point C.0x3FE means no object
was detected.";
CM_ SG_ 456 Checksum_PDC_11 "The checksum is used to check whether the data from the CPU buffer are shifted
without transmission errors to the CAN communication controller buffer and vice
versa.";
CM_ SG_ 455 LiveCounter_PDC_10 "The Livecounter is used to check the signal consistency of the messages . If the
signals are consecutive, the LiveCounter should also be sequential in the way 0, 1, 2
бн15, 0, 1 бн";
CM_ SG_ 455 ParkingSlotDepth_Right "This signal indicates the right parking slot depth.0x3FE means no object was
detected.";
CM_ SG_ 455 TimeStamp_RLS_RRS "This signal indicates the time stamp of the obstacle detection distance by rear left
side and rear right side radar.";
CM_ SG_ 455 DistanceValue_RRS "This signal indicates the obstacle detection distance by rear right side radar.0x3FE
means no object was detected";
CM_ SG_ 455 DistanceValue_RLS "This signal indicates the obstacle detection distance by rear left side radar.0x3FE
means no object was detected.";
CM_ SG_ 455 Checksum_PDC_10 "The checksum is used to check whether the data from the CPU buffer are shifted
without transmission errors to the CAN communication controller buffer and vice
versa.";
CM_ SG_ 578 LuggageDoorSt "This signal indicates luggage door status";
CM_ SG_ 588 MirrorFoldSt_FR "Fold status of right mirror";
CM_ SG_ 588 DoorSt_FR "This signal indicates the state of passenger door.";
CM_ SG_ 656 OdometerValue "This signal is drive distance since prime start .";
CM_ SG_ 308 LiveCounter_ESC_3 "The Livecounter is used to check the signal consistency of the messages . Ifthe signals are consecutive, the LiveCounter should also be sequential in theway 0, 1, 2 бн15, 0, 1 бн";
CM_ SG_ 308 ErrorSt_YRS "This signal indicates if the YRS is error or not.";
CM_ SG_ 308 Acceleration_Y "The signal is Lateral Acceleration(exact value).Positive value represents rightside of vehicle, negative value represents left side of vehicle.";
CM_ SG_ 308 Acceleration_X "The signal is LongitudinalAcceleration(exact value).Positive value representsforward, negative value represents backward.";
CM_ SG_ 308 YRSSt "This signal indicates the status of yaw rate sensor";
CM_ SG_ 308 YawRate "This signal indicates the yaw rate data (real data; sign depends on mountingposition)anticlockwise=positive, clockwise=negative";
CM_ SG_ 308 Checksum_ESC_3 "The checksum is used to check whether the data from the CPU buffer areshifted without transmission errors to the CAN communication controllerbuffer and vice versa.";
CM_ SG_ 306 LiveCounter_ESC_2 "The Livecounter is used to check the signal consistency of the messages . Ifthe signals are consecutive, the LiveCounter should also be sequential in theway 0, 1, 2 бн15, 0, 1 бн";
CM_ SG_ 306 WorkingSt_EPB "The signal indicates the working status of EPB.";
CM_ SG_ 306 Checksum_ESC_2 "The checksum is used to check whether the data from the CPU buffer areshifted without transmission errors to the CAN communication controllerbuffer and vice versa.";
CM_ SG_ 148 LiveCounter_EMS_3 "The Livecounter is used to check the signal consistency of the messages . Ifthe signals are consecutive, the LiveCounter should also be sequential in theway 0, 1, 2 бн15, 0, 1 бн";
CM_ SG_ 148 BrakePedalSt "This signal indicates the brake pedal status.";
CM_ SG_ 148 Checksum_EMS_3 "The checksum is used to check whether the data from the CPU buffer areshifted without transmission errors to the CAN communication controllerbuffer and vice versa.";
CM_ SG_ 586 MirrorFoldSt_FL "Fold status of left mirror";
CM_ SG_ 586 DoorSt_FL "This signal indicates the state of driver door.";
CM_ SG_ 560 AutoLightMode "This signal shows light is in Automatic Mode.";
CM_ SG_ 560 HazardWarningSt "The signal indicates Indicates the Hazard Warning is active or not";
CM_ SG_ 560 TurningSt_right "The signal indicates the driving status of the right turn light.";
CM_ SG_ 560 TurningSt_Left "The signal indicates the driving status of the left turn light.";
CM_ SG_ 560 HighBeamSt_FR "The signal indicates the status of front right high beam indicator.";
CM_ SG_ 560 HighBeamSt_FL "The signal indicates the status of front left high beam indicator.";
CM_ SG_ 560 LowBeamSt_FR "The signal indicates the status of front right low beam indicator.";
CM_ SG_ 560 LowBeamSt_FL "The signal indicates the status of front left low beam indicator.";
CM_ SG_ 546 AmbientTemp "The signal indicate ambient temperature.";
CM_ SG_ 592 ADV_ParkType "Indicates the current park type of ADV.";
CM_ SG_ 592 ADV_ParkOutDirection "Indicates the park out direction.";
CM_ SG_ 592 ADV_ParkInSlotSearchMode "Park-in slot search mode";
CM_ SG_ 592 ADV_FunctionAbnormalTip "ADV Function Abnormal Tip
For C095, 110101бв110110бв110111 are reserved.";
CM_ SG_ 592 ADV_ParkStatus "ADV Park Status";
CM_ SG_ 592 LiveCounter_ADV_1 "The Livecounter is used to check the signal consistency of the messages . If the
signals are consecutive, the LiveCounter should also be sequential in the way 0, 1, 2
бн15, 0, 1 бн";
CM_ SG_ 650 ParkOutDirection "Park out direction";
CM_ SG_ 650 TargetSelection_Area "Target Selection Area";
CM_ SG_ 650 TargetSelectionCenter_Y "Target Selection Center Y";
CM_ SG_ 650 TargetSelectionCenter_X "Target Selection Center X";
CM_ SG_ 650 TargetSelectionCenter_Angle "Target Selection Center Angle";
CM_ SG_ 650 TargetSelection_ParkType "Target Selection Park Type";
CM_ SG_ 650 TargetSelection_ParkDirection "Target Selection ParkDirection";
CM_ SG_ 650 TargetSelection_LineAngle "Target Selection Line Angle";
CM_ SG_ 650 TargetSelection_ConfirmReq "Target Selection Confirm Request";
CM_ SG_ 605 SensorErrorSt_RRS "This signal indicates if the rear right side radar sensor error or not,";
CM_ SG_ 605 SensorErrorSt_RLS "This signal indicates if the rear left side radar sensor error or not,";
CM_ SG_ 605 SensorErrorSt_FRS "This signal indicates if the front right side radar sensor error or not,";
CM_ SG_ 605 SensorErrorSt_FLS "This signal indicates if the front left side radar sensor error or not,";
CM_ SG_ 605 SensorBlockageSt_RRS "This signal indicates if the rear right side radar sensor Blockage or not";
CM_ SG_ 605 SensorBlockageSt_RLS "This signal indicates if the rear left side radar sensor Blockage or not";
CM_ SG_ 605 SensorBlockageSt_FRS "This signal indicates if the front right side radar sensor Blockage or not";
CM_ SG_ 605 SensorBlockageSt_FLS "This signal indicates if the front left side radar sensor Blockage or not";
CM_ SG_ 605 ObjectRange_RRS "This signal indicates the rear right side object's range";
CM_ SG_ 605 ObjectRange_RLS "This signal indicates the rear left side object's range";
CM_ SG_ 605 ObjectRange_FRS "This signal indicates the front right side object's range.";
CM_ SG_ 605 ObjectRange_FLS "This signal indicates the front left side object's range";
CM_ SG_ 605 ParkingSlotDegree_Right "This signal indicates the right parking slot degree with the curb.0xFFE means no
object was detected";
CM_ SG_ 605 ParkingSlotDegree_Left "This signal indicates the left parking slot degree with the curb.0xFFE means no
object was detected";
CM_ SG_ 605 SensorBlockageSt_RR "This signal indicates if the rear right radar sensor Blockage or not";
CM_ SG_ 605 SensorBlockageSt_RMR "This signal indicates if the rear middle right radar sensor Blockage or not";
CM_ SG_ 605 SensorBlockageSt_RML "This signal indicates if therear middle right left radar sensor Blockage or not";
CM_ SG_ 605 SensorBlockageSt_RL "This signal indicates if the rear left radar sensor Blockage or not";
CM_ SG_ 605 SensorBlockageSt_FR "This signal indicates if the front right radar sensor Blockage or not";
CM_ SG_ 605 SensorBlockageSt_FMR "This signal indicates if the front middle right radar sensor Blockage or not";
CM_ SG_ 605 SensorBlockageSt_FML "This signal indicates if the front middle left radar sensor Blockage or not";
CM_ SG_ 605 SensorBlockageSt_FL "This signal indicates if the front left radar sensor Blockage or not";
CM_ SG_ 395 APS_Slot6CenterPoint_Angle "SlotCenterPoint Angle";
CM_ SG_ 395 APS_Slot6CenterPoint_Y1 "SlotCenterPoint Y1";
CM_ SG_ 395 APS_Slot6CenterPoint_X1 "SlotCenterPoint X1";
CM_ SG_ 395 APS_Slot6_Width "Slot Width";
CM_ SG_ 395 APS_Slot6_LineAngle "Line Angle";
CM_ SG_ 395 APS_Slot6_Length "Slot Length";
CM_ SG_ 394 APS_Slot5CenterPoint_Angle "SlotCenterPoint Angle";
CM_ SG_ 394 APS_Slot5CenterPoint_Y1 "SlotCenterPoint Y1";
CM_ SG_ 394 APS_Slot5CenterPoint_X1 "SlotCenterPoint X1";
CM_ SG_ 394 APS_Slot5_Width "Slot Width";
CM_ SG_ 394 APS_Slot5_LineAngle "Line Angle";
CM_ SG_ 394 APS_Slot5_Length "Slot Length";
CM_ SG_ 393 APS_Slot4CenterPoint_Angle "SlotCenterPoint Angle";
CM_ SG_ 393 APS_Slot4CenterPoint_Y1 "SlotCenterPoint Y1";
CM_ SG_ 393 APS_Slot4CenterPoint_X1 "SlotCenterPoint X1";
CM_ SG_ 393 APS_Slot4_Width "Slot Width";
CM_ SG_ 393 APS_Slot4_LineAngle "Line Angle";
CM_ SG_ 393 APS_Slot4_Length "Slot Length";
CM_ SG_ 392 APS_Slot3CenterPoint_Angle "SlotCenterPoint Angle";
CM_ SG_ 392 APS_Slot3CenterPoint_Y1 "SlotCenterPoint Y1";
CM_ SG_ 392 APS_Slot3CenterPoint_X1 "SlotCenterPoint X1";
CM_ SG_ 392 APS_Slot3_Width "Slot Width";
CM_ SG_ 392 APS_Slot3_LineAngle "Line Angle";
CM_ SG_ 392 APS_Slot3_Length "Slot Length";
CM_ SG_ 391 APS_Slot2CenterPoint_Angle "SlotCenterPoint Angle";
CM_ SG_ 391 APS_Slot2CenterPoint_Y1 "SlotCenterPoint Y1";
CM_ SG_ 391 APS_Slot2CenterPoint_X1 "SlotCenterPoint X1";
CM_ SG_ 391 APS_Slot2_Width "Slot Width";
CM_ SG_ 391 APS_Slot2_LineAngle "Line Angle";
CM_ SG_ 391 APS_Slot2_Length "Slot Length";
CM_ SG_ 390 APS_Slot1CenterPoint_Angle "SlotCenterPoint Angle";
CM_ SG_ 390 APS_Slot1CenterPoint_Y1 "SlotCenterPoint Y1";
CM_ SG_ 390 APS_Slot1CenterPoint_X1 "SlotCenterPoint X1";
CM_ SG_ 390 APS_Slot1_Width "Slot Width";
CM_ SG_ 390 APS_Slot1_LineAngle "Line Angle";
CM_ SG_ 390 APS_Slot1_Length "Slot Length";
CM_ SG_ 388 APS_ParkingSlotAvailability "This signal indicates that availble parking slot exist or not";
CM_ SG_ 388 APS_Slot6_BothSidesInfo "APS Slot6 Both sides Info";
CM_ SG_ 388 APS_Slot5_BothSidesInfo "APS Slot5 Both sides Info";
CM_ SG_ 388 APS_Slot3_BothSidesInfo "APS Slot3 Both sides Info";
CM_ SG_ 388 APS_Slot4_BothSidesInfo "APS Slot4 Both sides Info";
CM_ SG_ 388 APS_Slot2_BothSidesInfo "APS Slot2 Both sides Info";
CM_ SG_ 388 APS_Slot1_BothSidesInfo "APS Slot1 Both sides Info";
CM_ SG_ 388 APS_Slot6_ParkType "APS Slot6 Park Type";
CM_ SG_ 388 APS_Slot6_ParkDirection "APS Slot6 ParkDirection";
CM_ SG_ 388 APS_Slot6_Info "APS Slot6 Info";
CM_ SG_ 388 APS_Slot6_DetectStatus "APS Slot6 DetectStatus";
CM_ SG_ 388 APS_Slot5_ParkType "APS Slot5 Park Type";
CM_ SG_ 388 APS_Slot5_ParkDirection "APS Slot5 ParkDirection";
CM_ SG_ 388 APS_Slot5_Info "APS Slot5 Info";
CM_ SG_ 388 APS_Slot5_DetectStatus "APS Slot5 DetectStatus";
CM_ SG_ 388 APS_Slot4_ParkType "APS Slot4 Park Type";
CM_ SG_ 388 APS_Slot4_ParkDirection "APS Slot4 ParkDirection";
CM_ SG_ 388 APS_Slot4_Info "APS Slot4 Info";
CM_ SG_ 388 APS_Slot4_DetectStatus "APS Slot4 DetectStatus";
CM_ SG_ 388 APS_Slot3_ParkType "APS Slot3 Park Type";
CM_ SG_ 388 APS_Slot3_ParkDirection "APS Slot3 ParkDirection";
CM_ SG_ 388 APS_Slot3_Info "APS Slot3 Info";
CM_ SG_ 388 APS_Slot3_DetectStatus "APS Slot3 DetectStatus";
CM_ SG_ 388 APS_Slot2_ParkType "APS Slot2 Park Type";
CM_ SG_ 388 APS_Slot2_ParkDirection "APS Slot2 ParkDirection";
CM_ SG_ 388 APS_Slot2_Info "APS Slot2 Info";
CM_ SG_ 388 APS_Slot2_DetectStatus "APS Slot2 DetectStatus";
CM_ SG_ 388 APS_Slot1_ParkType "APS Slot1 Park Type";
CM_ SG_ 388 APS_Slot1_ParkDirection "APS Slot1 ParkDirection";
CM_ SG_ 388 APS_Slot1_Info "APS Slot1 Info";
CM_ SG_ 388 APS_Slot1_DetectStatus "APS Slot1 DetectStatus";
CM_ SG_ 604 PDC_FunctionTip "This signal indicates if the searching function is OK for PDC";
CM_ SG_ 604 BuzzerAlarmPosition "This signal indicates the alarm position of buzzer.";
CM_ SG_ 604 RadarSysSt_RearSide "This signal indicates the working status of the rear side radar system.";
CM_ SG_ 604 RadarSysSt_FrontSide "This signal indicates the working status of the front side radar system.";
CM_ SG_ 604 BuzzerSwitchSt "This signal indicates the buzzer switch status";
CM_ SG_ 604 SwitchScreenRequest_PDC "PDC request IVI to switch the screen in case of object detected.";
CM_ SG_ 604 PDCAutoOnFunctionInd "This signal indicates if the PDC auto on function on or not.";
CM_ SG_ 604 SensorErrorSt_FL "This signal indicates if the front left radar sensor error or not.";
CM_ SG_ 604 ObjectRange_FL "This signal indicates the front left object's range";
CM_ SG_ 604 SensorErrorSt_FML "This signal indicates if the front middle left radar sensor error or not.";
CM_ SG_ 604 ObjectRange_FML "This signal indicates the front middle left object's range";
CM_ SG_ 604 SensorErrorSt_FMR "This signal indicates if the front middle right radar sensor error or not,";
CM_ SG_ 604 ObjectRange_FMR "This signal indicates the front middle object's range";
CM_ SG_ 604 SensorErrorSt_FR "This signal indicates if the front right radar sensor error or not.";
CM_ SG_ 604 ObjectRange_FR "This signal indicates the front right object's range";
CM_ SG_ 604 SensorErrorSt_RL "This signal indicates if the rear left radar sensor error or not,";
CM_ SG_ 604 ObjectRange_RL "This signal indicates the rear left object's range";
CM_ SG_ 604 SensorErrorSt_RML "This signal indicates if the rear middle left radar sensor error or not,";
CM_ SG_ 604 ObjectRange_RML "This signal indicates the rear middle left object's range";
CM_ SG_ 604 SensorErrorSt_RMR "This signal indicates if the rear middle right radar sensor error or not,";
CM_ SG_ 604 ObjectRange_RMR "This signal indicates the rear middle object's range.";
CM_ SG_ 604 SensorErrorSt_RR "This signal indicates if the rear right radar sensor error or not,";
CM_ SG_ 604 ObjectRange_RR "This signal indicates the rear right object's range.";
CM_ SG_ 604 BuzeerCmd_PDC "This signal is used for buzzer warning to remind the PDC status for driver.";
CM_ SG_ 604 RadarSysSt_Rear "This signal indicates the working status of rear radar system";
CM_ SG_ 604 RadarSysSt_Front "This signal indicates the working status of front radar system";
CM_ SG_ 604 ErrorSt_PDC "This signal indicates the error status of the PDC system.";
CM_ SG_ 604 SysSt_PDC "This signal indicate the PDC system status";
CM_ SG_ 180 LiveCounter_TCU_3 "The Livecounter is used to check the signal consistency of the messages . Ifthe signals are consecutive, the LiveCounter should also be sequential in theway 0, 1, 2 бн15, 0, 1 бн";
CM_ SG_ 180 Checksum_TCU_3 "The checksum is used to check whether the data from the CPU buffer areshifted without transmission errors to the CAN communication controllerbuffer and vice versa.";
CM_ SG_ 180 LeverInfo "This signal indicates the lever position information which should be displayed on the
dashboard.
For C095, only P,R,N,D,S,M,E,No Connection,Invalid Value.";
CM_ SG_ 208 LiveCounter_SAS_1 "The Livecounter is used to check the signal consistency of the messages . If the
signals are consecutive, the LiveCounter should also be sequential in the way 0, 1, 2
бн15, 0, 1";
CM_ SG_ 208 Checksum_SAS_1 "The checksum is used to check whether the data from the CPU buffer are shifted
without transmission errors to the CAN communication controller buffer and vice
versa.";
CM_ SG_ 208 SteeringWheelAngleSign "This signal shows the direction of steering wheel angle, it's used in pairs with
б░SteeringWheelAngleб▒.";
CM_ SG_ 208 SteeringWheelAngle "This signal indicates the angle of steering wheel .";
CM_ SG_ 208 SAS_St "The signal indicates the status of SAS.";
CM_ SG_ 652 LiveCounter_HU_Speech_1 "The Livecounter is used to check the signal consistency of the messages . Ifthe signals are consecutive, the LiveCounter should also be sequential in theway 0, 1, 2 бн15, 0, 1 бн";
CM_ SG_ 652 HU_SpeechReq_AVS "This signal is used to request AVS function on or Off by speech.";
CM_ SG_ 652 Checksum_HU_Speech_1 "The checksum is used to check whether the data from the CPU buffer areshifted without transmission errors to the CAN communication controllerbuffer and vice versa.";
CM_ SG_ 648 AVSTurnFollowUpFunctionReq "This signal is used to request AVS turn follow up function on or off.";
CM_ SG_ 648 AVSMonitoringVideoModeReq "AVS remote monitoring video mode Request";
CM_ SG_ 648 AVSFunctionReq "This signal is used to request AVS function on or off.";
CM_ SG_ 648 AVSViewtypeReq "This signal is used to request AVS View type";
CM_ SG_ 648 HU_RemoteMonitoringSt "This signal is used to indicate remote monitoring status of IVI.";
CM_ SG_ 648 HU_AVM_RemoteMonitoringSharpness "Indicates the remote monitoring sharpness set command";
CM_ SG_ 648 HU_AVM_RemoteMonitoringIFrameRe "This signal is used to request AVM to re-translate the I-Frame of remote monitoring
video.";
CM_ SG_ 648 LiveCounter_HU_5 "The Livecounter is used to check the signal consistency of the messages . Ifthe signals are consecutive, the LiveCounter should also be sequential in theway 0, 1, 2 бн15, 0, 1 бн";
CM_ SG_ 648 AVSFunctionExitReq "AVS Function Exit Request";
CM_ SG_ 648 CheckSum_HU_5 "The checksum is used to check whether the data from the CPU buffer areshifted without transmission errors to the CAN communication controllerbuffer and vice versa.";
CM_ SG_ 648 MODReq "This signal is used to request MOD function.";
CM_ SG_ 648 DynamicPGSReq "This signal is used to request dynamic PGS function.";
CM_ SG_ 648 SwitchScreenResponse_AVS "Head Unit response the switching screen request from AVS(Always happenwhen the switching screen command is not from IVI but from AVM in case oflever R,lever P or etc)";
CM_ SG_ 648 AVSViewModeReq "HU AVM View Mode Cmd";
CM_ SG_ 648 LanguageSet "This signal Indicates the language setting.";
CM_ SG_ 562 PowerMode "The signal indicates the vehicle power mode.";
CM_ SG_ 678 GPSTime_Year "Indicates the GPS year sent by GPS";
CM_ SG_ 678 GPSTime_Second "Indicates the GPS second sent by GPS";
CM_ SG_ 678 GPSTime_Month "Indicates the GPS month sent by GPS";
CM_ SG_ 678 GPSTime_Minute "Indicates the GPS minute sent by GPS";
CM_ SG_ 678 GPSTime_Hour "Indicates the GPS hour sent by GPS.";
CM_ SG_ 678 GPSTime_Day "Indicates the GPS day sent by GPS";
CM_ SG_ 304 WheelSpeedDirection_RR "the rear right wheel speed direction";
CM_ SG_ 304 WheelSpeedDirection_RL "the rear left wheel speed direction";
CM_ SG_ 304 WheelSpeedDirection_FR "the front right wheel speed direction";
CM_ SG_ 304 WheelSpeedDirection_FL "the the front left wheel speed direction.";
CM_ SG_ 304 LiveCounter_ABS_3 "The Livecounter is used to check the signal consistency of the messages . If the
signals are consecutive, the LiveCounter should also be sequential in the way 0, 1, 2
бн15, 0, 1 бн";
CM_ SG_ 304 Checksum_ABS_3 "The checksum is used to check whether the data from the CPU buffer are shifted
without transmission errors to the CAN communication controller buffer and vice
versa.";
CM_ SG_ 304 WheelPulse_RR "rear right wheel speed pulse(raw data)";
CM_ SG_ 304 WheelPulse_RL "rear left wheel speed pulse(raw data)";
CM_ SG_ 304 WheelPulse_FR "front right wheel speed pulse(raw data)";
CM_ SG_ 304 WheelPulse_FL "front left wheel speed pulse(raw data)";
CM_ SG_ 194 WheelSpeed_RR "This signal is rear right wheel speed which sent by ABS without filtering.";
CM_ SG_ 194 WheelSpeed_RL "This signal is rear left wheel speed which sent by ABS without filtering.";
CM_ SG_ 194 LiveCounter_ABS_2 "The Livecounter is used to check the signal consistency of the messages . If the
signals are consecutive, the LiveCounter should also be sequential in the way 0, 1, 2
бн15, 0, 1 бн";
CM_ SG_ 194 Checksum_ABS_2 "The checksum is used to check whether the data from the CPU buffer are shifted
without transmission errors to the CAN communication controller buffer and vice
versa.";
CM_ SG_ 192 WheelSpeed_FR "This signal is front right wheel speed which sent by ABS without filtering.";
CM_ SG_ 192 WheelSpeed_FL "This signal is front left wheel speed which sent by ABS without filtering.";
CM_ SG_ 192 LiveCounter_ABS_1 "The Livecounter is used to check the signal consistency of the messages . If the
signals are consecutive, the LiveCounter should also be sequential in the way 0, 1, 2
бн15, 0, 1 бн";
CM_ SG_ 192 Checksum_ABS_1 "The checksum is used to check whether the data from the CPU buffer are shifted
without transmission errors to the CAN communication controller buffer and vice
versa.";
CM_ SG_ 192 VehicleSpeed "The signal describes the raw vehicle speed calculated by ABS. The ABS calculates the
vehicle speed based on the raw wheel speed signals from the wheel speed sensors.
The vehicle speed output could be the average of the wheel speeds of the driven
axle.";
CM_ SG_ 192 DrivingDirection "The signal indicates driving direction of the vehicle.";
CM_ SG_ 600 TurnFollowUpFunctionInd "This signal indicates the AVS turn follow up function status.";
CM_ SG_ 600 RemoteMonitoringSt_AVS "This signal indicates the remote monitoring status.";
CM_ SG_ 600 RemoteMonitoringSharpnessSt_AVS "This signal indicates the remote monitoring sharpness setting status";
CM_ SG_ 600 RemoteMonitoringModeSt_AVS "This signal indicates the remote monitoring mode status";
CM_ SG_ 600 BlindSpotFilledFunctionInd "Indicates the blind spot filled function status";
CM_ SG_ 600 AVSViewtype "This signal indicates the AVS view type";
CM_ SG_ 600 AVSCameraBlockageSt_Right "This signal indicates AVS right camera Blockage status";
CM_ SG_ 600 AVSCameraBlockageSt_Rear "This signal indicates AVS rear camera Blockage status";
CM_ SG_ 600 AVSCameraBlockageSt_Left "This signal indicates AVS left camera Blockage status";
CM_ SG_ 600 AVSCameraBlockageSt_Front "This signal indicates AVS front camera Blockage status";
CM_ SG_ 600 AVS_RemoteViewModeFeedback "This signal indicates AVS remote view mode feedback";
CM_ SG_ 600 AVS_RemoteSharpnessFeedback "This signal indicates AVS remote sharpness feedback";
CM_ SG_ 600 AVS_RemoteMonitorigFeedback "This signal indicates AVS remote monitoring feedback";
CM_ SG_ 600 AVS_PDWarning_Rear "PD warning status";
CM_ SG_ 600 AVS_PDWarning_Front "PD warning status";
CM_ SG_ 600 AVS_CalibrationSt "AVS calibration status";
CM_ SG_ 600 AVS_AbnormalTip "AVS abnormal tips";
CM_ SG_ 600 AVSViewMode "This signal indicates the AVS view mode";
CM_ SG_ 600 AVSErrorSt "This signal indicates the AVS system error status.";
CM_ SG_ 600 SwitchScreenRequest_AVS "AVS request IVI to switch the screen in case of lever R, lever P or voicecontrol command or etc";
CM_ SG_ 600 AVSCameraErrorSt_Right "This signal indicates AVS right camera error status";
CM_ SG_ 600 AVSCameraErrorSt_Rear "This signal indicates AVS rear camera error status";
CM_ SG_ 600 MODSt_AVS "This signal indicates the AVS MOD status";
CM_ SG_ 600 MODWarning_Rear "This signal indicates AVS MOD rear warning";
CM_ SG_ 600 MODWarning_Front "This signal indicates AVS MOD front warning";
CM_ SG_ 600 AVSCameraErrorSt_Left "This signal indicates AVS left camera error status";
CM_ SG_ 600 LanguageTypeSt_AVS "The signal indicates the AVS language type status";
CM_ SG_ 600 AVSCameraErrorSt_Front "This signal indicates AVS front camera error status";
CM_ SG_ 600 DynamicPGSSt_AVS "This signal indicates the AVS dynamic PGS status";
CM_ SG_ 600 AVSSt "This signal indicates the AVS system status.";
BA_DEF_ BU_  "NmStationAddress" HEX 0 255;
BA_DEF_ SG_  "GenSigSendType" ENUM  "Cyclic","OnWrite","OnWriteWithRepetition","OnChange","OnChangeWithRepetition","IfActive","IfActiveWithRepetition","NoSigSendType","OnChangeAndIfActive","OnChangeAndIfActiveWithRepetition";
BA_DEF_ SG_  "GenSigStartValue" INT 0 65535;
BA_DEF_ BO_  "GenMsgCycleTime" INT 0 65535;
BA_DEF_ BO_  "GenMsgSendType" ENUM  "Cyclic ","NotUsed ","NotUsed ","NotUsed ","NotUsed ","NotUsed ","NotUsed ","IfActive ","NoMsgSendType";
BA_DEF_ BO_  "DiagRequest" ENUM  "No","Yes";
BA_DEF_ BO_  "DiagResponse" ENUM  "No","Yes";
BA_DEF_ BO_  "DiagState" ENUM  "No","Yes";
BA_DEF_ BO_  "GenMsgDelayTime" INT 0 1000;
BA_DEF_ BO_  "GenMsgILSupport" ENUM  "No","Yes";
BA_DEF_ BU_  "ILUsed" ENUM  "No","Yes";
BA_DEF_ BU_  "NmAsrNode" ENUM  "No","Yes";
BA_DEF_  "Baudrate" INT 0 0;
BA_DEF_  "NmType" STRING ;
BA_DEF_  "Manufacturer" STRING ;
BA_DEF_  "ILTxTimeout" INT 0 65535;
BA_DEF_  "DBName" STRING ;
BA_DEF_  "BusType" STRING ;
BA_DEF_ BO_  "NmAsrMessage" ENUM  "No","Yes";
BA_DEF_ BU_  "NmAsrCanMsgReducedTime" INT 0 0;
BA_DEF_  "NmAsrRepeatMessageTime" INT 0 0;
BA_DEF_  "NmAsrWaitBusSleepTime" INT 0 0;
BA_DEF_  "NmAsrTimeoutTime" INT 0 0;
BA_DEF_  "NmAsrCanMsgCycleTime" INT 0 0;
BA_DEF_  "NmAsrMessageCount" INT 0 256;
BA_DEF_ BU_  "NmAsrNodeIdentifier" HEX 0 255;
BA_DEF_  "NmAsrBaseAddress" HEX 0 0;
BA_DEF_ SG_  "GenSigTimeoutTime" INT 0 65535;
BA_DEF_DEF_  "NmStationAddress" 0;
BA_DEF_DEF_  "GenSigSendType" "NoSigSendType";
BA_DEF_DEF_  "GenSigStartValue" 0;
BA_DEF_DEF_  "GenMsgCycleTime" 0;
BA_DEF_DEF_  "GenMsgSendType" "NoMsgSendType";
BA_DEF_DEF_  "DiagRequest" "No";
BA_DEF_DEF_  "DiagResponse" "No";
BA_DEF_DEF_  "DiagState" "No";
BA_DEF_DEF_  "GenMsgDelayTime" 0;
BA_DEF_DEF_  "GenMsgILSupport" "Yes";
BA_DEF_DEF_  "ILUsed" "Yes";
BA_DEF_DEF_  "NmAsrNode" "No";
BA_DEF_DEF_  "Baudrate" 500000;
BA_DEF_DEF_  "NmType" "NmPwrTrainChery";
BA_DEF_DEF_  "Manufacturer" "Chery";
BA_DEF_DEF_  "ILTxTimeout" 40;
BA_DEF_DEF_  "DBName" "";
BA_DEF_DEF_  "BusType" "CAN";
BA_DEF_DEF_  "NmAsrMessage" "No";
BA_DEF_DEF_  "NmAsrCanMsgReducedTime" 0;
BA_DEF_DEF_  "NmAsrRepeatMessageTime" 3200;
BA_DEF_DEF_  "NmAsrWaitBusSleepTime" 1500;
BA_DEF_DEF_  "NmAsrTimeoutTime" 2000;
BA_DEF_DEF_  "NmAsrCanMsgCycleTime" 640;
BA_DEF_DEF_  "NmAsrMessageCount" 64;
BA_DEF_DEF_  "NmAsrNodeIdentifier" 0;
BA_DEF_DEF_  "NmAsrBaseAddress" 0;
BA_DEF_DEF_  "GenSigTimeoutTime" 0;
BA_ "NmAsrTimeoutTime" 1000;
BA_ "NmAsrMessageCount" 128;
BA_ "NmAsrCanMsgCycleTime" 100;
BA_ "NmAsrWaitBusSleepTime" 5000;
BA_ "NmAsrRepeatMessageTime" 500;
BA_ "Manufacturer" "Vector";
BA_ "NmType" "NmAsr";
BA_ "ILTxTimeout" 0;
BA_ "NmAsrBaseAddress" 1408;
BA_ "DBName" "AB02_FAW_C100_APA";
BA_ "NmStationAddress" BU_ APA 14;
BA_ "NmAsrNode" BU_ APA 1;
BA_ "NmAsrCanMsgReducedTime" BU_ APA 575;
BA_ "NmAsrNodeIdentifier" BU_ APA 14;
BA_ "GenMsgCycleTime" BO_ 897 100;
BA_ "GenMsgSendType" BO_ 386 0;
BA_ "GenMsgCycleTime" BO_ 386 30;
BA_ "GenMsgSendType" BO_ 384 0;
BA_ "GenMsgCycleTime" BO_ 384 30;
BA_ "GenMsgSendType" BO_ 593 0;
BA_ "GenMsgCycleTime" BO_ 593 100;
BA_ "GenMsgSendType" BO_ 672 0;
BA_ "GenMsgCycleTime" BO_ 672 100;
BA_ "GenMsgSendType" BO_ 591 0;
BA_ "GenMsgCycleTime" BO_ 591 100;
BA_ "GenMsgSendType" BO_ 590 0;
BA_ "GenMsgCycleTime" BO_ 590 100;
BA_ "GenMsgSendType" BO_ 420 0;
BA_ "GenMsgCycleTime" BO_ 420 50;
BA_ "GenMsgSendType" BO_ 643 0;
BA_ "GenMsgCycleTime" BO_ 643 100;
BA_ "GenMsgSendType" BO_ 657 0;
BA_ "GenMsgCycleTime" BO_ 657 100;
BA_ "GenMsgSendType" BO_ 667 0;
BA_ "GenMsgCycleTime" BO_ 667 100;
BA_ "GenMsgSendType" BO_ 688 0;
BA_ "GenMsgCycleTime" BO_ 688 100;
BA_ "GenMsgSendType" BO_ 534 0;
BA_ "GenMsgCycleTime" BO_ 534 100;
BA_ "GenMsgSendType" BO_ 571 0;
BA_ "GenMsgCycleTime" BO_ 571 100;
BA_ "GenMsgSendType" BO_ 564 0;
BA_ "GenMsgCycleTime" BO_ 564 100;
BA_ "GenMsgSendType" BO_ 454 0;
BA_ "GenMsgCycleTime" BO_ 454 50;
BA_ "GenMsgSendType" BO_ 453 0;
BA_ "GenMsgCycleTime" BO_ 453 50;
BA_ "GenMsgSendType" BO_ 452 0;
BA_ "GenMsgCycleTime" BO_ 452 50;
BA_ "GenMsgSendType" BO_ 451 0;
BA_ "GenMsgCycleTime" BO_ 451 50;
BA_ "GenMsgSendType" BO_ 450 0;
BA_ "GenMsgCycleTime" BO_ 450 50;
BA_ "GenMsgSendType" BO_ 449 0;
BA_ "GenMsgCycleTime" BO_ 449 50;
BA_ "GenMsgSendType" BO_ 448 0;
BA_ "GenMsgCycleTime" BO_ 448 50;
BA_ "GenMsgSendType" BO_ 459 0;
BA_ "GenMsgCycleTime" BO_ 459 50;
BA_ "GenMsgSendType" BO_ 458 0;
BA_ "GenMsgCycleTime" BO_ 458 50;
BA_ "GenMsgSendType" BO_ 457 0;
BA_ "GenMsgCycleTime" BO_ 457 50;
BA_ "GenMsgSendType" BO_ 456 0;
BA_ "GenMsgCycleTime" BO_ 456 50;
BA_ "GenMsgCycleTime" BO_ 455 50;
BA_ "GenMsgSendType" BO_ 455 0;
BA_ "GenMsgCycleTime" BO_ 578 100;
BA_ "GenMsgSendType" BO_ 578 0;
BA_ "GenMsgCycleTime" BO_ 588 100;
BA_ "GenMsgSendType" BO_ 588 0;
BA_ "GenMsgCycleTime" BO_ 656 100;
BA_ "GenMsgSendType" BO_ 656 0;
BA_ "GenMsgCycleTime" BO_ 308 20;
BA_ "GenMsgSendType" BO_ 308 0;
BA_ "GenMsgSendType" BO_ 306 0;
BA_ "GenMsgCycleTime" BO_ 306 20;
BA_ "GenMsgSendType" BO_ 148 0;
BA_ "GenMsgCycleTime" BO_ 148 10;
BA_ "GenMsgSendType" BO_ 586 0;
BA_ "GenMsgCycleTime" BO_ 586 100;
BA_ "GenMsgSendType" BO_ 560 0;
BA_ "GenMsgCycleTime" BO_ 560 100;
BA_ "GenMsgSendType" BO_ 546 0;
BA_ "GenMsgCycleTime" BO_ 546 100;
BA_ "GenMsgCycleTime" BO_ 592 100;
BA_ "GenMsgSendType" BO_ 592 0;
BA_ "GenMsgCycleTime" BO_ 650 100;
BA_ "GenMsgSendType" BO_ 650 0;
BA_ "GenMsgCycleTime" BO_ 605 100;
BA_ "GenMsgSendType" BO_ 605 0;
BA_ "GenMsgCycleTime" BO_ 395 100;
BA_ "GenMsgSendType" BO_ 395 0;
BA_ "GenMsgCycleTime" BO_ 394 100;
BA_ "GenMsgSendType" BO_ 394 0;
BA_ "GenMsgCycleTime" BO_ 393 100;
BA_ "GenMsgSendType" BO_ 393 0;
BA_ "GenMsgCycleTime" BO_ 392 100;
BA_ "GenMsgSendType" BO_ 392 0;
BA_ "GenMsgCycleTime" BO_ 391 100;
BA_ "GenMsgSendType" BO_ 391 0;
BA_ "GenMsgCycleTime" BO_ 390 100;
BA_ "GenMsgSendType" BO_ 390 0;
BA_ "GenMsgCycleTime" BO_ 388 100;
BA_ "GenMsgSendType" BO_ 388 0;
BA_ "GenMsgCycleTime" BO_ 604 100;
BA_ "GenMsgSendType" BO_ 604 0;
BA_ "GenMsgCycleTime" BO_ 180 10;
BA_ "GenMsgSendType" BO_ 180 0;
BA_ "GenMsgCycleTime" BO_ 208 10;
BA_ "GenMsgSendType" BO_ 208 0;
BA_ "GenMsgCycleTime" BO_ 652 1000;
BA_ "GenMsgSendType" BO_ 652 0;
BA_ "GenMsgCycleTime" BO_ 648 100;
BA_ "GenMsgSendType" BO_ 648 0;
BA_ "GenMsgSendType" BO_ 562 0;
BA_ "GenMsgCycleTime" BO_ 562 100;
BA_ "GenMsgCycleTime" BO_ 678 100;
BA_ "GenMsgSendType" BO_ 678 0;
BA_ "GenMsgSendType" BO_ 304 0;
BA_ "GenMsgCycleTime" BO_ 304 20;
BA_ "GenMsgSendType" BO_ 194 0;
BA_ "GenMsgCycleTime" BO_ 194 10;
BA_ "GenMsgCycleTime" BO_ 192 10;
BA_ "GenMsgSendType" BO_ 192 0;
BA_ "GenMsgCycleTime" BO_ 1422 100;
BA_ "GenMsgSendType" BO_ 1422 0;
BA_ "GenMsgILSupport" BO_ 1422 0;
BA_ "NmAsrMessage" BO_ 1422 1;
BA_ "DiagState" BO_ 2015 1;
BA_ "DiagResponse" BO_ 1838 1;
BA_ "DiagRequest" BO_ 1830 1;
BA_ "GenMsgSendType" BO_ 1830 0;
BA_ "GenMsgCycleTime" BO_ 600 100;
BA_ "GenMsgSendType" BO_ 600 0;
BA_ "GenSigSendType" SG_ 3221225472 USS_DIAG_MRL 3;
BA_ "GenSigSendType" SG_ 3221225472 PDC_SideRadarSystemStatus 3;
BA_ "GenSigSendType" SG_ 3221225472 PDC_RRLevel 3;
BA_ "GenSigSendType" SG_ 3221225472 PDC_RLLevel 3;
BA_ "GenSigSendType" SG_ 3221225472 PDC_RearRadarSystemStatus 3;
BA_ "GenSigSendType" SG_ 3221225472 PDC_FrontRadarSystemStatus 3;
BA_ "GenSigSendType" SG_ 3221225472 PDC_FRLevel 3;
BA_ "GenSigSendType" SG_ 3221225472 PDC_FLLevel 3;
BA_ "GenSigSendType" SG_ 3221225472 PDC_CenterRRLevel 3;
BA_ "GenSigSendType" SG_ 3221225472 PDC_CenterRLLevel 3;
BA_ "GenSigSendType" SG_ 3221225472 PDC_CenterFRLevel 3;
BA_ "GenSigSendType" SG_ 3221225472 PDC_CenterFLLevel 3;
BA_ "GenSigSendType" SG_ 3221225472 PDC_BuzzerControl 3;
BA_ "GenSigSendType" SG_ 3221225472 PDC_FLSensorErrorStatus 3;
BA_ "GenSigSendType" SG_ 3221225472 BCM_RightTurnLightCmd 1;
BA_ "GenSigTimeoutTime" SG_ 3221225472 BCM_RightTurnLightCmd 500;
BA_ "GenSigSendType" SG_ 3221225472 BCM_LeftTurnLightCmd 1;
BA_ "GenSigTimeoutTime" SG_ 3221225472 BCM_LeftTurnLightCmd 500;
BA_ "GenSigTimeoutTime" SG_ 3221225472 HU_SpeechRequest_AVMView 5000;
BA_ "GenSigTimeoutTime" SG_ 3221225472 HU_SpeechRequest_AVMandPDC 5000;
BA_ "GenSigTimeoutTime" SG_ 3221225472 ScreenPressPosition_X 5000;
BA_ "GenSigSendType" SG_ 3221225472 AVS_SpeechControlFeedback 3;
BA_ "GenSigSendType" SG_ 3221225472 MODWarning_Right 3;
BA_ "GenSigSendType" SG_ 3221225472 MODWarning_Left 3;
BA_ "GenSigSendType" SG_ 3221225472 CTAWarning_Rear 3;
BA_ "GenSigSendType" SG_ 3221225472 CTAWarning_Front 3;
BA_ "GenSigSendType" SG_ 3221225472 PDC_SpeechControlFeedback 3;
BA_ "GenSigSendType" SG_ 3221225472 SensorErrorSt_RLong 3;
BA_ "GenSigSendType" SG_ 3221225472 SensorErrorSt_LLong 3;
BA_ "GenSigSendType" SG_ 3221225472 RadarSysSt_Side 3;
BA_ "GenSigTimeoutTime" SG_ 3221225472 ScreenPressPosition_Y 5000;
BA_ "GenSigSendType" SG_ 3221225472 PDC_DIS_RRS 1;
BA_ "GenSigSendType" SG_ 3221225472 PDC_DIS_RLS 1;
BA_ "GenSigSendType" SG_ 746 USS_SLOT_R_Dy 3;
BA_ "GenSigSendType" SG_ 746 USS_SLOT_R_Dx 3;
BA_ "GenSigSendType" SG_ 746 USS_SLOT_R_Cy 3;
BA_ "GenSigSendType" SG_ 746 USS_SLOT_R_Cx 3;
BA_ "GenSigSendType" SG_ 745 USS_SLOT_R_By 3;
BA_ "GenSigSendType" SG_ 745 USS_SLOT_R_Bx 3;
BA_ "GenSigSendType" SG_ 745 USS_SLOT_R_Ay 3;
BA_ "GenSigSendType" SG_ 745 USS_SLOT_R_Ax 3;
BA_ "GenSigSendType" SG_ 744 USS_SLOT_L_Dy 3;
BA_ "GenSigSendType" SG_ 744 USS_SLOT_L_Dx 3;
BA_ "GenSigSendType" SG_ 744 USS_SLOT_L_Cy 3;
BA_ "GenSigSendType" SG_ 744 USS_SLOT_L_Cx 3;
BA_ "GenSigSendType" SG_ 743 USS_SLOT_L_By 3;
BA_ "GenSigSendType" SG_ 743 USS_SLOT_L_Bx 3;
BA_ "GenSigSendType" SG_ 743 USS_SLOT_L_AY 3;
BA_ "GenSigSendType" SG_ 743 USS_SLOT_L_Ax 3;
BA_ "GenSigSendType" SG_ 739 USS_DIAG_RRS 3;
BA_ "GenSigSendType" SG_ 739 USS_DIAG_RR 3;
BA_ "GenSigSendType" SG_ 739 USS_DIAG_RMR 3;
BA_ "GenSigSendType" SG_ 739 USS_DIAG_RML 3;
BA_ "GenSigSendType" SG_ 739 USS_DIAG_RLS 3;
BA_ "GenSigSendType" SG_ 739 USS_DIAG_RL 3;
BA_ "GenSigSendType" SG_ 738 USS_WORK_MODE 3;
BA_ "GenSigSendType" SG_ 738 USS_DIAG_FRS 3;
BA_ "GenSigSendType" SG_ 738 USS_DIAG_FR 3;
BA_ "GenSigSendType" SG_ 738 USS_DIAG_FMR 3;
BA_ "GenSigSendType" SG_ 738 USS_DIAG_FML 3;
BA_ "GenSigSendType" SG_ 738 USS_DIAG_FLS 3;
BA_ "GenSigSendType" SG_ 738 USS_DIAG_FL 3;
BA_ "GenSigSendType" SG_ 742 USS_DE_RRS 3;
BA_ "GenSigSendType" SG_ 742 USS_DE_RLS 3;
BA_ "GenSigSendType" SG_ 742 USS_DE_FRS 3;
BA_ "GenSigSendType" SG_ 742 USS_DE_FLS 3;
BA_ "GenSigSendType" SG_ 741 USS_DE_RR 3;
BA_ "GenSigSendType" SG_ 741 USS_DE_RMR 3;
BA_ "GenSigSendType" SG_ 741 USS_DE_RML 3;
BA_ "GenSigSendType" SG_ 741 USS_DE_RL 3;
BA_ "GenSigSendType" SG_ 740 USS_DE_FR 3;
BA_ "GenSigSendType" SG_ 740 USS_DE_FMR 3;
BA_ "GenSigSendType" SG_ 740 USS_DE_FML 3;
BA_ "GenSigSendType" SG_ 740 USS_DE_FL 3;
BA_ "GenSigSendType" SG_ 994 alpha_USS_RR 1;
BA_ "GenSigSendType" SG_ 994 alpha_USS_RMR 1;
BA_ "GenSigSendType" SG_ 994 alpha_USS_RML 1;
BA_ "GenSigSendType" SG_ 994 alpha_USS_RL 1;
BA_ "GenSigSendType" SG_ 995 alpha_USS_RR_long 1;
BA_ "GenSigSendType" SG_ 995 alpha_USS_RL_long 1;
BA_ "GenSigSendType" SG_ 995 alpha_USS_FR_long 1;
BA_ "GenSigSendType" SG_ 995 alpha_USS_FL_long 1;
BA_ "GenSigSendType" SG_ 993 alpha_USS_FR 1;
BA_ "GenSigSendType" SG_ 993 alpha_USS_FMR 1;
BA_ "GenSigSendType" SG_ 993 alpha_USS_FML 1;
BA_ "GenSigSendType" SG_ 993 alpha_USS_FL 1;
BA_ "GenSigSendType" SG_ 657 DisplayTheme 3;
BA_ "GenSigSendType" SG_ 667 LiveCounter_HU_10 3;
BA_ "GenSigSendType" SG_ 667 HU_PDCBuzzerReq 3;
BA_ "GenSigSendType" SG_ 667 Checksum_HU_10 3;
BA_ "GenSigSendType" SG_ 564 EngineHoodSt 3;
BA_ "GenSigSendType" SG_ 751 CanTaskAlive 1;
BA_ "GenSigSendType" SG_ 751 PubuicCanSta 3;
BA_ "GenSigSendType" SG_ 751 PrivateCanSta 3;
BA_ "GenSigSendType" SG_ 750 Debug_ReloatValid_R 1;
BA_ "GenSigSendType" SG_ 750 Debug_ReloatValid_L 1;
BA_ "GenSigSendType" SG_ 750 Debug_ReloatTheta_R 1;
BA_ "GenSigSendType" SG_ 750 Debug_ReloatTheta_L 1;
BA_ "GenSigSendType" SG_ 750 Debug_ReloatDistance_R 1;
BA_ "GenSigSendType" SG_ 750 Debug_ReloatDistance_L 1;
BA_ "GenSigSendType" SG_ 747 TargetSlot_By 1;
BA_ "GenSigSendType" SG_ 747 TargetSlot_Bx 1;
BA_ "GenSigSendType" SG_ 747 TargetSlot_Ay 1;
BA_ "GenSigSendType" SG_ 747 TargetSlot_Ax 1;
BA_ "GenSigSendType" SG_ 749 FV_TargetPoint_Y 1;
BA_ "GenSigSendType" SG_ 749 FV_TargetPoint_X 1;
BA_ "GenSigSendType" SG_ 749 FV_TargetPoint_Angle 1;
BA_ "GenSigSendType" SG_ 748 TargetSlot_Dy 1;
BA_ "GenSigSendType" SG_ 748 TargetSlot_Dx 1;
BA_ "GenSigSendType" SG_ 748 TargetSlot_Cy 1;
BA_ "GenSigSendType" SG_ 748 TargetSlot_Cx 1;
BA_ "GenSigSendType" SG_ 737 USS_SLOT_R_DEPTH 3;
BA_ "GenSigSendType" SG_ 737 USS_SLOT_L_DEPTH 3;
BA_ "GenSigSendType" SG_ 737 DR_RAW 1;
BA_ "GenSigSendType" SG_ 736 DR_Y 1;
BA_ "GenSigSendType" SG_ 736 DR_X 1;
BA_ "GenSigStartValue" SG_ 308 Acceleration_Y 795.996608544992;
BA_ "GenSigStartValue" SG_ 308 Acceleration_X 795.996608544992;
BA_ "GenSigStartValue" SG_ 308 YawRate 2204.8;
BA_ "GenSigStartValue" SG_ 546 AmbientTemp 80;
BA_ "GenSigStartValue" SG_ 650 TargetSelectionCenter_Y 1000;
BA_ "GenSigStartValue" SG_ 650 TargetSelectionCenter_X 1000;
BA_ "GenSigStartValue" SG_ 395 APS_Slot6CenterPoint_Y1 1000;
BA_ "GenSigStartValue" SG_ 395 APS_Slot6CenterPoint_X1 1000;
BA_ "GenSigStartValue" SG_ 394 APS_Slot5CenterPoint_Y1 1000;
BA_ "GenSigStartValue" SG_ 394 APS_Slot5CenterPoint_X1 1000;
BA_ "GenSigStartValue" SG_ 393 APS_Slot4CenterPoint_Y1 1000;
BA_ "GenSigStartValue" SG_ 393 APS_Slot4CenterPoint_X1 1000;
BA_ "GenSigStartValue" SG_ 392 APS_Slot3CenterPoint_Y1 1000;
BA_ "GenSigStartValue" SG_ 392 APS_Slot3CenterPoint_X1 1000;
BA_ "GenSigStartValue" SG_ 391 APS_Slot2CenterPoint_Y1 1000;
BA_ "GenSigStartValue" SG_ 391 APS_Slot2CenterPoint_X1 1000;
BA_ "GenSigStartValue" SG_ 390 APS_Slot1CenterPoint_Y1 1000;
BA_ "GenSigStartValue" SG_ 390 APS_Slot1CenterPoint_X1 1000;
BA_ "GenSigSendType" SG_ 388 APS_ParkingSlotAvailability 0;
BA_ "GenSigSendType" SG_ 388 APS_Slot6_BothSidesInfo 0;
BA_ "GenSigSendType" SG_ 388 APS_Slot5_BothSidesInfo 0;
BA_ "GenSigSendType" SG_ 388 APS_Slot3_BothSidesInfo 0;
BA_ "GenSigSendType" SG_ 388 APS_Slot4_BothSidesInfo 0;
BA_ "GenSigSendType" SG_ 388 APS_Slot2_BothSidesInfo 0;
BA_ "GenSigSendType" SG_ 388 APS_Slot1_BothSidesInfo 0;
BA_ "GenSigSendType" SG_ 388 APS_Slot6_ParkType 0;
BA_ "GenSigSendType" SG_ 388 APS_Slot6_ParkDirection 0;
BA_ "GenSigSendType" SG_ 388 APS_Slot6_Info 0;
BA_ "GenSigSendType" SG_ 388 APS_Slot6_DetectStatus 0;
BA_ "GenSigSendType" SG_ 388 APS_Slot5_ParkType 0;
BA_ "GenSigSendType" SG_ 388 APS_Slot5_ParkDirection 0;
BA_ "GenSigSendType" SG_ 388 APS_Slot5_Info 0;
BA_ "GenSigSendType" SG_ 388 APS_Slot5_DetectStatus 0;
BA_ "GenSigSendType" SG_ 388 APS_Slot4_ParkType 0;
BA_ "GenSigSendType" SG_ 388 APS_Slot4_ParkDirection 0;
BA_ "GenSigSendType" SG_ 388 APS_Slot4_Info 0;
BA_ "GenSigSendType" SG_ 388 APS_Slot4_DetectStatus 0;
BA_ "GenSigSendType" SG_ 388 APS_Slot3_ParkType 0;
BA_ "GenSigSendType" SG_ 388 APS_Slot3_ParkDirection 0;
BA_ "GenSigSendType" SG_ 388 APS_Slot3_Info 0;
BA_ "GenSigSendType" SG_ 388 APS_Slot3_DetectStatus 0;
BA_ "GenSigSendType" SG_ 388 APS_Slot2_ParkType 0;
BA_ "GenSigSendType" SG_ 388 APS_Slot2_ParkDirection 0;
BA_ "GenSigSendType" SG_ 388 APS_Slot2_Info 0;
BA_ "GenSigSendType" SG_ 388 APS_Slot2_DetectStatus 0;
BA_ "GenSigSendType" SG_ 388 APS_Slot1_ParkType 0;
BA_ "GenSigSendType" SG_ 388 APS_Slot1_ParkDirection 0;
BA_ "GenSigSendType" SG_ 388 APS_Slot1_Info 0;
BA_ "GenSigSendType" SG_ 388 APS_Slot1_DetectStatus 0;
BA_ "GenSigSendType" SG_ 604 SensorErrorSt_FL 3;
BA_ "GenSigSendType" SG_ 604 ObjectRange_FL 3;
BA_ "GenSigSendType" SG_ 604 SensorErrorSt_FML 3;
BA_ "GenSigSendType" SG_ 604 ObjectRange_FML 3;
BA_ "GenSigSendType" SG_ 604 SensorErrorSt_FMR 3;
BA_ "GenSigSendType" SG_ 604 ObjectRange_FMR 3;
BA_ "GenSigSendType" SG_ 604 SensorErrorSt_FR 3;
BA_ "GenSigSendType" SG_ 604 ObjectRange_FR 3;
BA_ "GenSigSendType" SG_ 604 SensorErrorSt_RL 3;
BA_ "GenSigSendType" SG_ 604 ObjectRange_RL 3;
BA_ "GenSigSendType" SG_ 604 SensorErrorSt_RML 3;
BA_ "GenSigSendType" SG_ 604 ObjectRange_RML 3;
BA_ "GenSigSendType" SG_ 604 SensorErrorSt_RMR 3;
BA_ "GenSigSendType" SG_ 604 ObjectRange_RMR 3;
BA_ "GenSigSendType" SG_ 604 SensorErrorSt_RR 3;
BA_ "GenSigSendType" SG_ 604 ObjectRange_RR 3;
BA_ "GenSigSendType" SG_ 604 BuzeerCmd_PDC 3;
BA_ "GenSigSendType" SG_ 604 RadarSysSt_Rear 3;
BA_ "GenSigSendType" SG_ 604 RadarSysSt_Front 3;
BA_ "GenSigSendType" SG_ 604 ErrorSt_PDC 3;
BA_ "GenSigSendType" SG_ 604 SysSt_PDC 3;
BA_ "GenSigTimeoutTime" SG_ 180 LeverInfo 1000;
BA_ "GenSigTimeoutTime" SG_ 208 SteeringWheelAngleSign 500;
BA_ "GenSigTimeoutTime" SG_ 208 SteeringWheelAngle 500;
BA_ "GenSigStartValue" SG_ 208 SAS_St 1;
BA_ "GenSigTimeoutTime" SG_ 648 DynamicPGSReq 5000;
BA_ "GenSigTimeoutTime" SG_ 648 AVSViewModeReq 5000;
BA_ "GenSigTimeoutTime" SG_ 648 LanguageSet 5000;
BA_ "GenSigStartValue" SG_ 678 GPSTime_Year 1;
BA_ "GenSigStartValue" SG_ 678 GPSTime_Month 1;
BA_ "GenSigStartValue" SG_ 678 GPSTime_Day 1;
BA_ "GenSigSendType" SG_ 1422 Extension_information 0;
BA_ "GenSigSendType" SG_ 1422 Stay_awake_reason 0;
BA_ "GenSigSendType" SG_ 1422 Wakeup_reason 0;
BA_ "GenSigSendType" SG_ 2015 Diag_Fun_Req 0;
BA_ "GenSigSendType" SG_ 1838 AVM_Phy_Resp 0;
BA_ "GenSigSendType" SG_ 1830 AVM_Phy_Req 0;
BA_ "GenSigSendType" SG_ 600 AVSViewMode 3;
BA_ "GenSigSendType" SG_ 600 AVSErrorSt 3;
BA_ "GenSigSendType" SG_ 600 SwitchScreenRequest_AVS 3;
BA_ "GenSigSendType" SG_ 600 AVSCameraErrorSt_Right 3;
BA_ "GenSigSendType" SG_ 600 AVSCameraErrorSt_Rear 3;
BA_ "GenSigSendType" SG_ 600 MODSt_AVS 3;
BA_ "GenSigSendType" SG_ 600 MODWarning_Rear 3;
BA_ "GenSigSendType" SG_ 600 MODWarning_Front 3;
BA_ "GenSigSendType" SG_ 600 AVSCameraErrorSt_Left 3;
BA_ "GenSigSendType" SG_ 600 LanguageTypeSt_AVS 3;
BA_ "GenSigSendType" SG_ 600 AVSCameraErrorSt_Front 3;
BA_ "GenSigSendType" SG_ 600 DynamicPGSSt_AVS 3;
BA_ "GenSigSendType" SG_ 600 AVSSt 3;
VAL_ 3221225472 PDC_SwitchScreenRequest 3 "Reserved" 2 "PDC Display Exit Request" 1 "PDC Display Enter Request" 0 "Inactive" ;
VAL_ 3221225472 PDC_BuzzerSwitchSt 1 "On" 0 "Off" ;
VAL_ 3221225472 PDC_AutoOnFunctionInd 1 "On" 0 "Off" ;
VAL_ 3221225472 PDC_SideRadarSystemStatus 1 "On" 0 "Off" ;
VAL_ 3221225472 PDC_RRLevel 7 "Invalid Value" 6 "Reserved" 5 "Reserved" 4 "Reserved" 3 "Level3" 2 "Level2" 1 "Level1" 0 "Inactive" ;
VAL_ 3221225472 PDC_RLLevel 7 "Invalid Value" 6 "Reserved" 5 "Reserved" 4 "Reserved" 3 "Level3" 2 "Level2" 1 "Level1" 0 "Inactive" ;
VAL_ 3221225472 PDC_RearRadarSystemStatus 1 "On" 0 "Off" ;
VAL_ 3221225472 PDC_FrontRadarSystemStatus 1 "On" 0 "Off" ;
VAL_ 3221225472 PDC_FRLevel 7 "Invalid Value" 6 "Reserved" 5 "Reserved" 4 "Reserved" 3 "Level3" 2 "Level2" 1 "Level1" 0 "Inactive" ;
VAL_ 3221225472 PDC_FLLevel 7 "Invalid Value" 6 "Reserved" 5 "Reserved" 4 "Reserved" 3 "Level3" 2 "Level2" 1 "Level1" 0 "Inactive" ;
VAL_ 3221225472 PDC_CenterRRLevel 7 "Invalid Value" 6 "Reserved" 5 "Reserved" 4 "Reserved" 3 "Level3" 2 "Level2" 1 "Level1" 0 "Inactive" ;
VAL_ 3221225472 PDC_CenterRLLevel 7 "Invalid Value" 6 "Reserved" 5 "Reserved" 4 "Reserved" 3 "Level3" 2 "Level2" 1 "Level1" 0 "Inactive" ;
VAL_ 3221225472 PDC_CenterFRLevel 7 "Invalid Value" 6 "Reserved" 5 "Reserved" 4 "Reserved" 3 "Level3" 2 "Level2" 1 "Level1" 0 "Inactive" ;
VAL_ 3221225472 PDC_CenterFLLevel 7 "Invalid Value" 6 "Reserved" 5 "Reserved" 4 "Reserved" 3 "Level3" 2 "Level2" 1 "Level1" 0 "Inactive" ;
VAL_ 3221225472 PDC_BuzzerControl 7 "Invalid Value" 6 "System fault tone" 5 "Normal start tone" 4 "Low frequency tone" 3 "Reserved" 2 "High frequency tone" 1 "Continuous tone" 0 "Inactive" ;
VAL_ 3221225472 PDC_RightLongDistSensorErrSta 3 "Reserved" 2 "Blockage" 1 "Error" 0 "No error" ;
VAL_ 3221225472 PDC_LeftLongDistSensorErrSta 3 "Reserved" 2 "Blockage" 1 "Error" 0 "No error" ;
VAL_ 3221225472 PDC_RRSensorErrorStatus 3 "Reserved" 2 "Blockage" 1 "Error" 0 "No error" ;
VAL_ 3221225472 PDC_CenterRRSensorErrorStatus 3 "Reserved" 2 "Blockage" 1 "Error" 0 "No error" ;
VAL_ 3221225472 PDC_CenterRLSensorErrorStatus 3 "Reserved" 2 "Blockage" 1 "Error" 0 "No error" ;
VAL_ 3221225472 PDC_RLSensorErrorStatus 3 "Reserved" 2 "Blockage" 1 "Error" 0 "No error" ;
VAL_ 3221225472 PDC_FRSensorErrorStatus 3 "Reserved" 2 "Blockage" 1 "Error" 0 "No error" ;
VAL_ 3221225472 PDC_CenterFRSensorErrorStatus 3 "Reserved" 2 "Blockage" 1 "Error" 0 "No error" ;
VAL_ 3221225472 PDC_CenterFLSensorErrorStatus 3 "Reserved" 2 "Blockage" 1 "Error" 0 "No error" ;
VAL_ 3221225472 PDC_FLSensorErrorStatus 3 "Reserved" 2 "Blockage" 1 "Error" 0 "No error" ;
VAL_ 3221225472 BCM_RightTurnLightCmd 1 "On" 0 "Off" ;
VAL_ 3221225472 BCM_LeftTurnLightCmd 1 "On" 0 "Off" ;
VAL_ 3221225472 HU_SpeechRequest_AVMView 8 "Screen Dragged 3D View" 7 "Rear Wide View" 6 "Front Wide View" 5 "Top View and Right View" 4 "Top View and Left View" 3 "Top View and Rear View" 2 "Top View and Front View" 1 "All Top View" 0 "No request" ;
VAL_ 3221225472 HU_SpeechRequest_AVMandPDC 2 "Off" 1 "On" 0 "No request" ;
VAL_ 3221225472 HU_PDCFunctionReq 1 "Pressed" 0 "Not pressed" ;
VAL_ 3221225472 HU_PDCBuzzerReq 1 "Pressed" 0 "Not pressed" ;
VAL_ 3221225472 HU_PDCAutoOnFunctionReq 1 "Pressed" 0 "Not pressed" ;
VAL_ 3221225472 HU_PDCAVMFunctionCmd 1 "Pressed" 0 "Not pressed" ;
VAL_ 3221225472 AVS_SpeechControlFeedback 24 "Reserved" 23 "Reserved" 22 "Reserved" 21 "Reserved" 20 "Reserved" 19 "Reserved" 18 "Reserved" 17 "Reserved" 16 "Reserved" 15 "Reserved" 14 "Reserved" 13 "Reserved" 12 "Reserved" 11 "Reserved" 10 "Reserved" 9 "Reserved" 8 "Reserved" 7 "Reserved" 6 "Reserved" 5 "Reserved" 4 "Off Failure" 3 "Off Success" 2 "On Failure" 1 "On Success" 0 "Inactive" ;
VAL_ 3221225472 MODWarning_Right 1 "Warning" 0 "No warning" ;
VAL_ 3221225472 MODWarning_Left 1 "Warning" 0 "No warning" ;
VAL_ 3221225472 CTAWarning_Rear 1 "Warning" 0 "No warning" ;
VAL_ 3221225472 CTAWarning_Front 1 "Warning" 0 "No warning" ;
VAL_ 3221225472 SensorBlockageSt_RLong 1 "Blockage" 0 "No blockage" ;
VAL_ 3221225472 SensorBlockageSt_Llong 1 "Blockage" 0 "No blockage" ;
VAL_ 3221225472 PDC_SpeechControlFeedback 7 "Reserved" 6 "Reserved" 5 "Reserved" 4 "Off Failure" 3 "Off Success" 2 "On Failure" 1 "On Success" 0 "Inactive" ;
VAL_ 3221225472 SensorErrorSt_RLong 1 "Error" 0 "No error" ;
VAL_ 3221225472 SensorErrorSt_LLong 1 "Error" 0 "No error" ;
VAL_ 3221225472 RadarSysSt_Side 1 "On" 0 "Off" ;
VAL_ 3221225472 HandParkingBrakeSt 3 "Error" 2 "Reserved" 1 "Brake Tightened" 0 "Brake Released" ;
VAL_ 3221225472 FogLightSt_FR 1 "On" 0 "Off" ;
VAL_ 3221225472 FogLightSt_FL 1 "On" 0 "Off" ;
VAL_ 3221225472 ParkInSlotSearchModeSet 3 "Reserved" 2 "Manual" 1 "Auto" 0 "Inactive" ;
VAL_ 3221225472 AVSViewModeReponse 15 "Reserved" 14 "Calibration Mode" 13 "Factoty Mode" 12 "Reserved" 11 "Screen Dragged 3D View" 10 "Rear Rim view" 9 "Front Rim view" 8 "Reserved" 7 "Rear Wide View" 6 "Front Wide View" 5 "Top View and Right View" 4 "Top View and Left View" 3 "Top View and Rear View" 2 "Top View and Front View" 1 "All Top View" 0 "Inactive" ;
VAL_ 386 ADV_DebugEnabled 1 "Enabled" 0 "Not Enabled" ;
VAL_ 386 ADV_TargetTracingAvaialble 1 "Available" 0 "Not Available" ;
VAL_ 384 ADV_PathTracingAvaialble 1 "Available" 0 "Not Available" ;
VAL_ 384 ADV_CurrentDirection 1 "Backward" 0 "Forward" ;
VAL_ 593 ADV_Alarm_Position_Rear_Right 3 "Invalid" 2 "Range 2" 1 "Range 1" 0 "No Object" ;
VAL_ 593 ADV_Alarm_Position_Rear_Left 3 "Invalid" 2 "Range 2" 1 "Range 1" 0 "No Object" ;
VAL_ 593 ADV_Alarm_Position_Front_Right 3 "Invalid" 2 "Range 2" 1 "Range 1" 0 "No Object" ;
VAL_ 593 ADV_Alarm_Position_Front_Left 3 "Invalid" 2 "Range 2" 1 "Range 1" 0 "No Object" ;
VAL_ 593 ADV_PDCSchedule 3 "Reserved" 2 "Reserved" 1 "Sensor one time" 0 "No Request" ;
VAL_ 593 ADV_RightSlotSearchType 3 "All" 2 "Parallel" 1 "Perpedicular" 0 "Inactive" ;
VAL_ 593 ADV_LeftSlotSearchType 3 "All" 2 "Parallel" 1 "Perpedicular" 0 "Inactive" ;
VAL_ 672 RemoteAVSViewModeReq 15 "Reserved" 14 "Reserved" 13 "Reserved" 12 "Reserved" 11 "Screen Dragged 3D View" 10 "Rear Rim view" 9 "Front Rim view" 8 "Reserved" 7 "Rear Wide View" 6 "Front Wide View" 5 "Top View and Right View" 4 "Top View and Left View" 3 "Top View and Rear View" 2 "Top View and Front View" 1 "All Top View" 0 "Inactive" ;
VAL_ 672 RemoteAVSSharpnessReq 3 "Reserved" 2 "HD" 1 "SD" 0 "No Request" ;
VAL_ 672 RemoteMonitoringReq 3 "Reserved" 2 "On" 1 "Off" 0 "Inactive" ;
VAL_ 591 DoorSt_RR 1 "Open" 0 "Close" ;
VAL_ 590 DoorSt_RL 1 "Open" 0 "Close" ;
VAL_ 420 MCP_AVSandFRadarSwitch 1 "Pressed" 0 "Not pressed" ;
VAL_ 643 HU_PDCAutoOnFunctionReq 3 "Reserved" 2 "OFF" 1 "ON" 0 "Inactive" ;
VAL_ 643 HU_BlindSpotFilledFunctionReq 3 "Reserved" 2 "On" 1 "Off" 0 "Inactive" ;
VAL_ 657 DisplayTheme 7 "Reserved" 6 "Reserved" 5 "Reserved" 4 "Reserved" 3 "Theme 3" 2 "Theme 2" 1 "Theme 1" 0 "Not define" ;
VAL_ 667 HU_PDCBuzzerReq 3 "Reserved" 2 "On" 1 "Off" 0 "Inactive" ;
VAL_ 688 GW_RemoteVehicleMode 1 "Remote Mode" 0 "Normal Mode" ;
VAL_ 688 GW_OTAMode 7 "Reserved" 6 "Reserved" 5 "Reserved" 4 "Reserved" 3 "Reserved" 2 "Reserved" 1 "OTA Mode" 0 "Normal Mode" ;
VAL_ 534 DMS_VehicleModeinfo 15 "Invalid value" 14 "Reserved" 13 "Reserved" 12 "Reserved" 11 "Reserved" 10 "Reserved" 9 "Reserved" 8 "Reserved" 7 "EV" 6 "Individual" 5 "Off road" 4 "Snow" 3 "Sport" 2 "Comfort" 1 "Eco" 0 "Auto" ;
VAL_ 564 EngineHoodSt 1 "Open" 0 "Close" ;
VAL_ 453 TxRxSt_RR 3 "Reserved" 2 "Rx" 1 "Tx" 0 "Reserved" ;
VAL_ 453 TxRxSt_RMR 3 "Reserved" 2 "Rx" 1 "Tx" 0 "Reserved" ;
VAL_ 452 TxRxSt_RML 3 "Reserved" 2 "Rx" 1 "Tx" 0 "Reserved" ;
VAL_ 452 TxRxSt_RL 3 "Reserved" 2 "Rx" 1 "Tx" 0 "Reserved" ;
VAL_ 451 TxRxSt_FR 3 "Reserved" 2 "Rx" 1 "Tx" 0 "Reserved" ;
VAL_ 451 TxRxSt_FMR 3 "Reserved" 2 "Rx" 1 "Tx" 0 "Reserved" ;
VAL_ 450 TxRxSt_FML 3 "Reserved" 2 "Rx" 1 "Tx" 0 "Reserved" ;
VAL_ 450 TxRxSt_FL 3 "Reserved" 2 "Rx" 1 "Tx" 0 "Reserved" ;
VAL_ 578 LuggageDoorSt 1 "Open" 0 "Close" ;
VAL_ 588 MirrorFoldSt_FR 3 "Reserved" 2 "Reserved" 1 "Fold" 0 "Unfold" ;
VAL_ 588 DoorSt_FR 1 "Open" 0 "Close" ;
VAL_ 308 ErrorSt_YRS 1 "Error" 0 "No Error" ;
VAL_ 308 YRSSt 1 "Not Calibrated" 0 "Calibrated" ;
VAL_ 306 WorkingSt_EPB 3 "Unknown" 2 "Locked" 1 "Releasing/Locking" 0 "Released" ;
VAL_ 148 BrakePedalSt 3 "Error" 2 "Reserved" 1 "Actuated" 0 "Not Actuated" ;
VAL_ 586 MirrorFoldSt_FL 3 "Reserved" 2 "Reserved" 1 "Fold" 0 "Unfold" ;
VAL_ 586 DoorSt_FL 1 "Open" 0 "Close" ;
VAL_ 560 AutoLightMode 1 "Active" 0 "Inactive" ;
VAL_ 560 HazardWarningSt 1 "Active" 0 "Inactive" ;
VAL_ 560 TurningSt_right 1 "Active" 0 "Inactive" ;
VAL_ 560 TurningSt_Left 1 "Active" 0 "Inactive" ;
VAL_ 560 HighBeamSt_FR 1 "On" 0 "Off" ;
VAL_ 560 HighBeamSt_FL 1 "On" 0 "Off" ;
VAL_ 560 LowBeamSt_FR 1 "On" 0 "Off" ;
VAL_ 560 LowBeamSt_FL 1 "On" 0 "Off" ;
VAL_ 592 ADV_ParkType 7 "Reserved" 6 "Reserved" 5 "Reserved" 4 "Reserved" 3 "Auto" 2 "Backward Oblique" 1 "Backward Perpendicular" 0 "Parallel" ;
VAL_ 592 ADV_ParkOutDirection 7 "Reserved" 6 "Reserved" 5 "Left Parallel" 4 "Right Parallel" 3 "Left perpendicular" 2 "Rear perpendicular" 1 "Front perpendicular" 0 "Right perpendicular" ;
VAL_ 592 ADV_ParkInSlotSearchMode 1 "Manual" 0 "Auto" ;
VAL_ 592 ADV_FunctionAbnormalTip 63 "Reserved" 62 "Reserved" 61 "Reserved" 60 "Reserved" 59 "Reserved" 58 "Reserved" 57 "Reserved" 56 "Reserved" 55 "Wireless charging,ifstopcharging" 54 "Wireless charge station founded" 53 "Wireless charge enquiry charging" 52 "Air suspension is adjusting" 51 "Vehicle is in remote mode" 50 "Start park out tip" 49 "Start park in tip" 48 "Disclaimer tip" 47 "Wifi signal loss" 46 "Abnormal tire pressure" 45 "Space Unknown" 44 "Space Insufficient" 43 "Parking has been completed" 42 "Press DMH to start or exit" 41 "vehicle height not fulfilled" 40 "Vehicle direction incorrect" 39 "EPS Sys Can't Respons Correctly" 38 "Driving brake SysCan'tRespoCorre" 37 "AVS SysCan'tRespCorrectly" 36 "StartSysCan'tResp Correctly" 35 "Door SysCan'tResponCorrectly" 34 "Remote contro Sys Can't RespCorr" 33 "Gear shift SysCan'tResCorrectly" 32 "ParkinBrakeSysCan'tRespCorrectly" 31 "Forward-look signa is unavailab" 30 "PDC Signal Interf Not Available" 29 "AVS Signal Interf Not Available" 28 "YAW Signal Interf Not Available" 27 "SAS Signal Interf Not Available" 26 "Onekey startup interf is unavail" 25 "IVI Interface Not Available" 24 "VehicleDriveInterf Not Available" 23 "Comfort Sys Interfac unavailable" 22 "Steering interface unavailable" 21 "Parking Brake Interf unavailable" 20 "Shift gears interfac unavailable" 19 "DrivingBrake Interfa unavailable" 18 "SACC or LKA activated" 17 "Tracking error" 16 "Unable to switch vehicle mode" 15 "Space Insufficient" 14 "Obstacle is too close" 13 "Door open" 12 "Cannot enter parking status" 11 "Speed too fast,system exit" 10 "Speed too fast,Please slow down" 9 "Parki can'tcomple pleasetakeover" 8 "Road surface complexity" 7 "Gradient too high" 6 "Driver intervention EPB" 5 "Driver intervention steeringwhee" 4 "Driver intervention brake pedal" 3 "Vehicle not started" 2 "Parking syst exit by hard butt" 1 "Parking sys exit by soft butt" 0 "No Tip" ;
VAL_ 592 ADV_ParkStatus 15 "Reserved" 14 "Reserved" 13 "Reserved" 12 "Reserved" 11 "Error" 10 "Finish" 9 "Abort" 8 "Suspended" 7 "Driver override" 6 "Parking out" 5 "Parking in" 4 "Map update" 3 "Searching for park-out" 2 "Searching for park-in" 1 "Stand by" 0 "Initial" ;
VAL_ 650 ParkOutDirection 15 "Reserved" 14 "Reserved" 13 "Reserved" 12 "Reserved" 11 "Reserved" 10 "Reserved" 9 "Reserved" 8 "Reserved" 7 "Remote control" 6 "Left Parallel" 5 "Right Parallel" 4 "Left perpendicular" 3 "Rear perpendicular" 2 "Front perpendicular" 1 "Right perpendicular" 0 "No request" ;
VAL_ 650 TargetSelection_Area 1 "Green Area" 0 "Red Area" ;
VAL_ 650 TargetSelection_ParkType 7 "Reserved" 6 "Reserved" 5 "Reserved" 4 "Auto" 3 "Backward Oblique" 2 "Backward Perpendicular" 1 "Parallel" 0 "Inactive" ;
VAL_ 650 TargetSelection_ParkDirection 3 "Reserved" 2 "Left" 1 "Right" 0 "Inactive" ;
VAL_ 650 TargetSelection_ConfirmReq 1 "Active" 0 "Inactive" ;
VAL_ 605 SensorErrorSt_RRS 1 "error" 0 "No error" ;
VAL_ 605 SensorErrorSt_RLS 1 "Error" 0 "No error" ;
VAL_ 605 SensorErrorSt_FRS 1 "Error" 0 "No error" ;
VAL_ 605 SensorErrorSt_FLS 1 "Error" 0 "No error" ;
VAL_ 605 SensorBlockageSt_RRS 1 "blockage" 0 "No blockage" ;
VAL_ 605 SensorBlockageSt_RLS 1 "Blockage" 0 "No blockage" ;
VAL_ 605 SensorBlockageSt_FRS 1 "Blockage" 0 "No blockage" ;
VAL_ 605 SensorBlockageSt_FLS 1 "Blockage" 0 "No blockage" ;
VAL_ 605 ObjectRange_RRS 7 "Invalid Value" 6 "Range 6" 5 "Range 5" 4 "Range 4" 3 "Range 3" 2 "Range 2" 1 "Range 1" 0 "No Object" ;
VAL_ 605 ObjectRange_RLS 7 "Invalid Value" 6 "Range 6" 5 "Range 5" 4 "Range 4" 3 "Range 3" 2 "Range 2" 1 "Range 1" 0 "No Object" ;
VAL_ 605 ObjectRange_FRS 7 "Invalid Value" 6 "Range 6" 5 "Range 5" 4 "Range 4" 3 "Range 3" 2 "Range 2" 1 "Range 1" 0 "No Object" ;
VAL_ 605 ObjectRange_FLS 7 "Invalid Value" 6 "Range 6" 5 "Range 5" 4 "Range 4" 3 "Range 3" 2 "Range 2" 1 "Range 1" 0 "No Object" ;
VAL_ 605 SensorBlockageSt_RR 1 "Blockage" 0 "No blockage" ;
VAL_ 605 SensorBlockageSt_RMR 1 "Blockage" 0 "No blockage" ;
VAL_ 605 SensorBlockageSt_RML 1 "Blockage" 0 "No blockage" ;
VAL_ 605 SensorBlockageSt_RL 1 "Blockage" 0 "No blockage" ;
VAL_ 605 SensorBlockageSt_FR 1 "Blockage" 0 "No blockage" ;
VAL_ 605 SensorBlockageSt_FMR 1 "Blockage" 0 "No blockage" ;
VAL_ 605 SensorBlockageSt_FML 1 "Blockage" 0 "No blockage" ;
VAL_ 605 SensorBlockageSt_FL 1 "Blockage" 0 "No blockage" ;
VAL_ 388 APS_Slot6_BothSidesInfo 3 "Reserved" 2 "Obstacle" 1 "No obstacle" 0 "Initial" ;
VAL_ 388 APS_Slot5_BothSidesInfo 3 "Parking slot det using Sor Fus" 2 "Parking slot det using USS only" 1 "Parking slot det using AVM only" 0 "Not detected" ;
VAL_ 388 APS_Slot3_BothSidesInfo 3 "Backward_obilique" 2 "Backward perpendicular" 1 "Parallel" 0 "Initial" ;
VAL_ 388 APS_Slot4_BothSidesInfo 1 "Left" 0 "Right" ;
VAL_ 388 APS_Slot2_BothSidesInfo 3 "Reserved" 2 "Obstacle" 1 "No obstacle" 0 "Initial" ;
VAL_ 388 APS_Slot1_BothSidesInfo 3 "Parking slot det using Sor Fus" 2 "Parking slot det using USS only" 1 "Parking slot det using AVM only" 0 "Not detected" ;
VAL_ 388 APS_Slot6_ParkType 3 "Backward_obilique" 2 "Backward perpendicular" 1 "Parallel" 0 "Initial" ;
VAL_ 388 APS_Slot6_ParkDirection 1 "Left" 0 "Right" ;
VAL_ 388 APS_Slot6_Info 3 "Reserved" 2 "Obstacle" 1 "No obstacle" 0 "Initial" ;
VAL_ 388 APS_Slot6_DetectStatus 3 "Parking slot det using Sor Fus" 2 "Parking slot det using USS only" 1 "Parking slot det using AVM only" 0 "Not detected" ;
VAL_ 388 APS_Slot5_ParkType 3 "Backward_obilique" 2 "Backward perpendicular" 1 "Parallel" 0 "Initial" ;
VAL_ 388 APS_Slot5_ParkDirection 1 "Left" 0 "Right" ;
VAL_ 388 APS_Slot5_Info 3 "Reserved" 2 "Obstacle" 1 "No obstacle" 0 "Initial" ;
VAL_ 388 APS_Slot5_DetectStatus 3 "Parking slot det using Sor Fus" 2 "Parking slot det using USS only" 1 "Parking slot det using AVM only" 0 "Not detected" ;
VAL_ 388 APS_Slot4_ParkType 3 "Backward_obilique" 2 "Backward perpendicular" 1 "Parallel" 0 "Initial" ;
VAL_ 388 APS_Slot4_ParkDirection 1 "Left" 0 "Right" ;
VAL_ 388 APS_Slot4_Info 3 "Reserved" 2 "Obstacle" 1 "No obstacle" 0 "Initial" ;
VAL_ 388 APS_Slot4_DetectStatus 3 "Parking slot det using Sor Fus" 2 "Parking slot det using USS only" 1 "Parking slot det using AVM only" 0 "Not detected" ;
VAL_ 388 APS_Slot3_ParkType 3 "Backward_obilique" 2 "Backward perpendicular" 1 "Parallel" 0 "Initial" ;
VAL_ 388 APS_Slot3_ParkDirection 1 "Left" 0 "Right" ;
VAL_ 388 APS_Slot3_Info 3 "Reserved" 2 "Obstacle" 1 "No obstacle" 0 "Initial" ;
VAL_ 388 APS_Slot3_DetectStatus 3 "Parking slot det using Sor Fus" 2 "Parking slot det using USS only" 1 "Parking slot det using AVM only" 0 "Not detected" ;
VAL_ 388 APS_Slot2_ParkType 3 "Backward_obilique" 2 "Backward perpendicular" 1 "Parallel" 0 "Initial" ;
VAL_ 388 APS_Slot2_ParkDirection 1 "Left" 0 "Right" ;
VAL_ 388 APS_Slot2_Info 3 "Reserved" 2 "Obstacle" 1 "No obstacle" 0 "Initial" ;
VAL_ 388 APS_Slot2_DetectStatus 3 "Parking slot det using Sor Fus" 2 "Parking slot det using USS only" 1 "Parking slot det using AVM only" 0 "Not detected" ;
VAL_ 388 APS_Slot1_ParkType 3 "Backward_obilique" 2 "Backward perpendicular" 1 "Parallel" 0 "Initial" ;
VAL_ 388 APS_Slot1_ParkDirection 1 "Left" 0 "Right" ;
VAL_ 388 APS_Slot1_Info 3 "Reserved" 2 "Obstacle" 1 "No obstacle" 0 "Initial" ;
VAL_ 388 APS_Slot1_DetectStatus 3 "Parking slot det using Sor Fus" 2 "Parking slot det using USS only" 1 "Parking slot det using AVM only" 0 "Not detected" ;
VAL_ 604 PDC_FunctionTip 7 "Reserved" 6 "Searching both slot failure" 5 "Searching both slot success" 4 "Searching left slot success" 3 "Searching left slot failure" 2 "Searching right slot success" 1 "Searching right slot failure" 0 "Inactive" ;
VAL_ 604 BuzzerAlarmPosition 7 "Reserved" 6 "Reserved" 5 "Reserved" 4 "Front + Rear" 3 "SelfCheck" 2 "Rear" 1 "Front" 0 "Off" ;
VAL_ 604 RadarSysSt_RearSide 1 "On" 0 "Off" ;
VAL_ 604 RadarSysSt_FrontSide 1 "On" 0 "Off" ;
VAL_ 604 BuzzerSwitchSt 1 "On" 0 "Off" ;
VAL_ 604 SwitchScreenRequest_PDC 3 "Reserved" 2 "PDC Display Enter Request" 1 "PDC Display Exit Request" 0 "Inactive" ;
VAL_ 604 PDCAutoOnFunctionInd 1 "On" 0 "Off" ;
VAL_ 604 SensorErrorSt_FL 1 "Error" 0 "No error" ;
VAL_ 604 ObjectRange_FL 7 "Invalid Value" 6 "Range 6" 5 "Range 5" 4 "Range 4" 3 "Range 3" 2 "Range 2" 1 "Range 1" 0 "No Object" ;
VAL_ 604 SensorErrorSt_FML 1 "Error" 0 "No error" ;
VAL_ 604 ObjectRange_FML 7 "Invalid Value" 6 "Range 6" 5 "Range 5" 4 "Range 4" 3 "Range 3" 2 "Range 2" 1 "Range 1" 0 "No Object" ;
VAL_ 604 SensorErrorSt_FMR 1 "Error" 0 "No error" ;
VAL_ 604 ObjectRange_FMR 7 "Invalid Value" 6 "Range 6" 5 "Range 5" 4 "Range 4" 3 "Range 3" 2 "Range 2" 1 "Range 1" 0 "No Object" ;
VAL_ 604 SensorErrorSt_FR 1 "Error" 0 "No error" ;
VAL_ 604 ObjectRange_FR 7 "Invalid Value" 6 "Range 6" 5 "Range 5" 4 "Range 4" 3 "Range 3" 2 "Range 2" 1 "Range 1" 0 "No Object" ;
VAL_ 604 SensorErrorSt_RL 1 "Error" 0 "No error" ;
VAL_ 604 ObjectRange_RL 7 "Invalid Value" 6 "Range 6" 5 "Range 5" 4 "Range 4" 3 "Range 3" 2 "Range 2" 1 "Range 1" 0 "No Object" ;
VAL_ 604 SensorErrorSt_RML 1 "Error" 0 "No error" ;
VAL_ 604 ObjectRange_RML 7 "Invalid Value" 6 "Range 6" 5 "Range 5" 4 "Range 4" 3 "Range 3" 2 "Range 2" 1 "Range 1" 0 "No Object" ;
VAL_ 604 SensorErrorSt_RMR 1 "Error" 0 "No error" ;
VAL_ 604 ObjectRange_RMR 7 "Invalid Value" 6 "Range 6" 5 "Range 5" 4 "Range 4" 3 "Range 3" 2 "Range 2" 1 "Range 1" 0 "No Object" ;
VAL_ 604 SensorErrorSt_RR 1 "Error" 0 "No error" ;
VAL_ 604 ObjectRange_RR 7 "Invalid Value" 6 "Range 6" 5 "Range 5" 4 "Range 4" 3 "Range 3" 2 "Range 2" 1 "Range 1" 0 "No Object" ;
VAL_ 604 BuzeerCmd_PDC 7 "Level 5(Low Frequency Tone)" 6 "Level 4" 5 "Self check ok tone" 4 "Self check error tone" 3 "Level 3" 2 "Level 2" 1 "Level 1(Continuous tone)" 0 "None" ;
VAL_ 604 RadarSysSt_Rear 1 "On" 0 "Off" ;
VAL_ 604 RadarSysSt_Front 1 "On" 0 "Off" ;
VAL_ 604 ErrorSt_PDC 1 "Error" 0 "No error" ;
VAL_ 604 SysSt_PDC 1 "On" 0 "Off" ;
VAL_ 180 LeverInfo 15 "Invalid Value" 14 "No Connection" 13 "Reserved" 12 "Reserved" 11 "Reserved" 10 "Reserved" 9 "Reserved" 8 "B" 7 "E" 6 "W" 5 "M" 4 "S" 3 "D" 2 "N" 1 "R" 0 "P" ;
VAL_ 208 SteeringWheelAngleSign 1 "Right (Negative)" 0 "Left (Positive)" ;
VAL_ 208 SAS_St 3 "Permanent Error Detected" 2 "Intermittent Error Detected" 1 "SAS Not Calibrated" 0 "SAS Angle And Speed Correct" ;
VAL_ 652 HU_SpeechReq_AVS 3 "Reserved" 2 "On" 1 "Off" 0 "Inactive" ;
VAL_ 648 AVSFunctionExitReq 1 "Active" 0 "Inactive" ;
VAL_ 648 MODReq 3 "Reserved" 2 "On" 1 "Off" 0 "Inactive" ;
VAL_ 648 DynamicPGSReq 3 "Reserved" 2 "On" 1 "Off" 0 "Inactive" ;
VAL_ 648 SwitchScreenResponse_AVS 3 "Reserved" 2 "AVM Exit Response" 1 "AVM Enter Response" 0 "Inactive" ;
VAL_ 648 AVSViewModeReq 15 "Reserved" 14 "Calibration Mode" 13 "Factoty Mode" 12 "Reserved" 11 "Screen Dragged 3D View" 10 "Rear Rim view" 9 "Front Rim view" 8 "Reserved" 7 "Rear Wide View" 6 "Front Wide View" 5 "Top View and Right View" 4 "Top View and Left View" 3 "Top View and Rear View" 2 "Top View and Front View" 1 "All Top View" 0 "Inactive" ;
VAL_ 648 LanguageSet 0 "Inactive" 1 "Simplified Chinese" 2 "Traditional Chinese" 3 "English" 4 "French" 5 "Arabic" 6 "Russian" 7 "reserved" 8 "reserved" 9 "reserved" 10 "reserved" 11 "reserved" 12 "reserved" 13 "reserved" 14 "reserved" 15 "reserved" ;
VAL_ 562 PowerMode 15 "Invalid value" 14 "Reserved" 13 "Reserved" 12 "Reserved" 11 "Reserved" 10 "Reserved" 9 "Reserved" 8 "Reserved" 7 "Reserved" 6 "Reserved" 5 "Reserved" 4 "IgnitionOn" 3 "Reserved" 2 "Reserved" 1 "Reserved" 0 "Off" ;
VAL_ 304 WheelSpeedDirection_RR 3 "Invalid Value" 2 "Backward" 1 "Forward" 0 "Stop" ;
VAL_ 304 WheelSpeedDirection_RL 3 "Invalid Value" 2 "Backward" 1 "Forward" 0 "Stop" ;
VAL_ 304 WheelSpeedDirection_FR 3 "Invalid Value" 2 "Backward" 1 "Forward" 0 "Stop" ;
VAL_ 304 WheelSpeedDirection_FL 3 "Invalid Value" 2 "Backward" 1 "Forward" 0 "Stop" ;
VAL_ 192 DrivingDirection 3 "Invalid Value" 2 "Backward" 1 "Forward" 0 "Stop" ;
VAL_ 600 TurnFollowUpFunctionInd 1 "On" 0 "Off" ;
VAL_ 600 RemoteMonitoringSt_AVS 1 "On" 0 "Off" ;
VAL_ 600 RemoteMonitoringSharpnessSt_AVS 1 "HD" 0 "SD" ;
VAL_ 600 RemoteMonitoringModeSt_AVS 1 "Video Mode" 0 "Picture Mode" ;
VAL_ 600 FoundSlotBuzzerTip 1 "Active" 0 "Inactive" ;
VAL_ 600 BlindSpotFilledFunctionInd 1 "On" 0 "Off" ;
VAL_ 600 AVSViewtype 3 "Reserved" 2 "Other" 1 "3D" 0 "2D" ;
VAL_ 600 AVSCameraBlockageSt_Right 1 "Blockage" 0 "No Blockage" ;
VAL_ 600 AVSCameraBlockageSt_Rear 1 "Blockage" 0 "No Blockage" ;
VAL_ 600 AVSCameraBlockageSt_Left 1 "Blockage" 0 "No Blockage" ;
VAL_ 600 AVSCameraBlockageSt_Front 1 "Blockage" 0 "No Blockage" ;
VAL_ 600 AVS_RemoteViewModeFeedback 31 "Reserved" 30 "Reserved" 29 "Reserved" 28 "Reserved" 27 "Reserved" 26 "Reserved" 25 "Reserved" 24 "Rear Rim view Failure" 23 "Rear Rim view Success" 22 "Front Rim view Failure" 21 "Front Rim view Success" 20 "Reserved" 19 "Reserved" 18 "Rear Wide View Failure" 17 "Rear Wide View Success" 16 "Front Wide View Failure" 15 "Front Wide View Success" 14 "Top View and Right View Failure" 13 "Top View and Right View Success" 12 "Top View and Left View Failure" 11 "Top View and Left View Success" 10 "Top View and Rear View Failure" 9 "Top View and Rear View Success" 8 "Top View and Front View Failure" 7 "Top View and Front View Success" 6 "All Top View Failure" 5 "All Top View Success" 4 "On Failure" 3 "On Success" 2 "Off Failure" 1 "Off Success" 0 "Inactive" ;
VAL_ 600 AVS_RemoteSharpnessFeedback 7 "Reserved" 6 "Reserved" 5 "Reserved" 4 "HD Failure" 3 "HD Success" 2 "SD Failure" 1 "SD Success" 0 "Inactive" ;
VAL_ 600 AVS_RemoteMonitorigFeedback 7 "Reserved" 6 "Reserved" 5 "Reserved" 4 "On Failure" 3 "On Success" 2 "Off Failure" 1 "Off Success" 0 "Inactive" ;
VAL_ 600 AVS_PDWarning_Rear 1 "Warning" 0 "No warning" ;
VAL_ 600 AVS_PDWarning_Front 1 "Warning" 0 "No warning" ;
VAL_ 600 AVS_CalibrationSt 3 "Reserved" 2 "Calibrated" 1 "Calibrating" 0 "Not calibrated" ;
VAL_ 600 AVS_AbnormalTip 7 "Reserved" 6 "Reserved" 5 "Reserved" 4 "Reserved" 3 "Reserved" 2 "Reserved" 1 "Speed too high" 0 "Inactive" ;
VAL_ 600 AVSViewMode 15 "Invalid value" 14 "Calibration Mode" 13 "Factoty Mode" 12 "Reserved" 11 "Screen Dragged 3D View" 10 "Rear Rim view" 9 "Front Rim view" 8 "Reserved" 7 "Rear Wide View" 6 "Front Wide View" 5 "Top View and Right View" 4 "Top View and Left View" 3 "Top View and Rear View" 2 "Top View and Front View" 1 "All Top View" 0 "Inactive" ;
VAL_ 600 AVSErrorSt 1 "Error" 0 "No error" ;
VAL_ 600 SwitchScreenRequest_AVS 3 "Reserved" 2 "AVS Exit Request" 1 "AVS Enter Request" 0 "Inactive" ;
VAL_ 600 AVSCameraErrorSt_Right 1 "Error" 0 "No error" ;
VAL_ 600 AVSCameraErrorSt_Rear 1 "Error" 0 "No error" ;
VAL_ 600 MODSt_AVS 1 "on" 0 "off" ;
VAL_ 600 MODWarning_Rear 1 "Warning" 0 "No warning" ;
VAL_ 600 MODWarning_Front 1 "Warning" 0 "No warning" ;
VAL_ 600 AVSCameraErrorSt_Left 1 "Error" 0 "No error" ;
VAL_ 600 LanguageTypeSt_AVS 0 "Simple Chinese" 1 "Traditional Chinese" 2 "English" 3 "French" 4 "Arabic" 5 "Russian" 6 "reserved" 7 "reserved" 8 "reserved" 9 "reserved" 10 "reserved" 11 "reserved" 12 "reserved" 13 "reserved" 14 "reserved" 15 "reserved" ;
VAL_ 600 AVSCameraErrorSt_Front 1 "Error" 0 "No error" ;
VAL_ 600 DynamicPGSSt_AVS 1 "On" 0 "Off" ;
VAL_ 600 AVSSt 1 "on" 0 "off" ;
